VERSION ""

NS_ :

BS_:

BU_: VCM TCM ECM EBS ACM

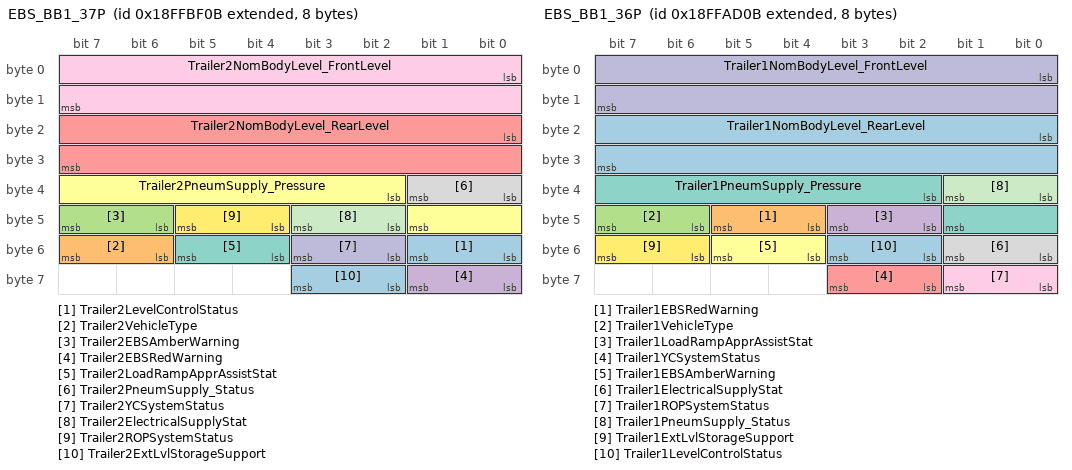
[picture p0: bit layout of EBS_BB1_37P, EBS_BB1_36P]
BO_ 2566897419 EBS_BB1_37P: 8 EBS
 SG_ Trailer2LevelControlStatus : 48|2@1+ (1,0) [0|0] ""  VCM
 SG_ Trailer2VehicleType : 54|2@1+ (1,0) [0|0] ""  VCM
 SG_ Trailer2EBSAmberWarning : 46|2@1+ (1,0) [0|0] ""  VCM
 SG_ Trailer2EBSRedWarning : 56|2@1+ (1,0) [0|0] ""  VCM
 SG_ Trailer2NomBodyLevel_RearLevel : 16|16@1+ (1,0) [0|65535] "mm"  VCM
 SG_ Trailer2PneumSupply_Pressure : 34|8@1+ (5,0) [0|1275] "kPa"  VCM
 SG_ Trailer2LoadRampApprAssistStat : 52|2@1+ (1,0) [0|0] ""  VCM
 SG_ Trailer2PneumSupply_Status : 32|2@1+ (1,0) [0|0] ""  VCM
 SG_ Trailer2NomBodyLevel_FrontLevel : 0|16@1+ (1,0) [0|65535] "mm"  VCM
 SG_ Trailer2YCSystemStatus : 50|2@1+ (1,0) [0|0] ""  VCM
 SG_ Trailer2ElectricalSupplyStat : 42|2@1+ (1,0) [0|0] ""  VCM
 SG_ Trailer2ROPSystemStatus : 44|2@1+ (1,0) [0|0] ""  VCM
 SG_ Trailer2ExtLvlStorageSupport : 58|2@1+ (1,0) [0|0] ""  VCM

BO_ 2566892811 EBS_BB1_36P: 8 EBS
 SG_ Trailer1NomBodyLevel_RearLevel : 16|16@1+ (1,0) [0|65535] "mm"  VCM
 SG_ Trailer1EBSRedWarning : 44|2@1+ (1,0) [0|0] ""  VCM
 SG_ Trailer1VehicleType : 46|2@1+ (1,0) [0|0] ""  VCM
 SG_ Trailer1LoadRampApprAssistStat : 42|2@1+ (1,0) [0|0] ""  VCM
 SG_ Trailer1YCSystemStatus : 58|2@1+ (1,0) [0|0] ""  VCM
 SG_ Trailer1EBSAmberWarning : 52|2@1+ (1,0) [0|0] ""  VCM
 SG_ Trailer1PneumSupply_Pressure : 34|8@1+ (5,0) [0|1275] "kPa"  VCM
 SG_ Trailer1ElectricalSupplyStat : 48|2@1+ (1,0) [0|0] ""  VCM
 SG_ Trailer1ROPSystemStatus : 56|2@1+ (1,0) [0|0] ""  VCM
 SG_ Trailer1NomBodyLevel_FrontLevel : 0|16@1+ (1,0) [0|65535] "mm"  VCM
 SG_ Trailer1PneumSupply_Status : 32|2@1+ (1,0) [0|0] ""  VCM
 SG_ Trailer1ExtLvlStorageSupport : 54|2@1+ (1,0) [0|0] ""  VCM
 SG_ Trailer1LevelControlStatus : 50|2@1+ (1,0) [0|0] ""  VCM

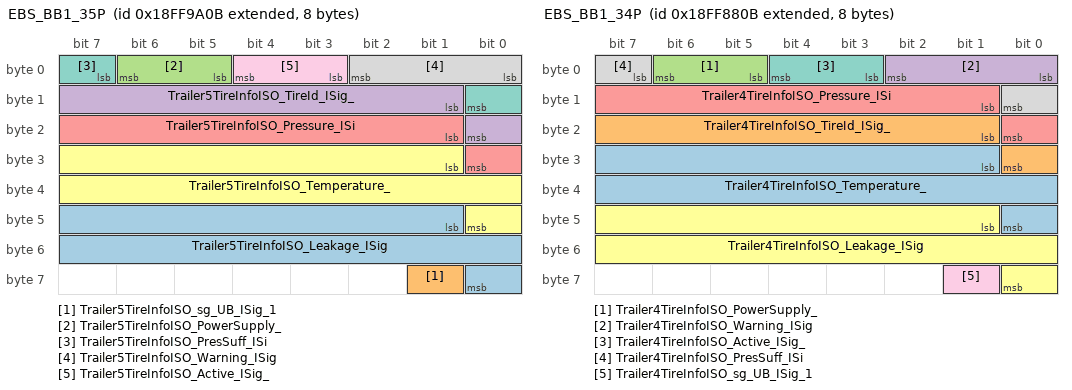
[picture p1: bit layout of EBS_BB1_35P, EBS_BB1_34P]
BO_ 2566887947 EBS_BB1_35P: 8 EBS
 SG_ Trailer5TireInfoISO_Leakage_ISig : 41|16@1+ (0.1,0) [0|6553.5] "Pa_per_s"  VCM
 SG_ Trailer5TireInfoISO_sg_UB_ISig_1 : 57|1@1+ (1,0) [0|0] ""  VCM
 SG_ Trailer5TireInfoISO_PowerSupply_ : 5|2@1+ (1,0) [0|0] ""  VCM
 SG_ Trailer5TireInfoISO_TireId_ISig_ : 9|8@1+ (1,0) [0|255] "NotApplicable"  VCM
 SG_ Trailer5TireInfoISO_Pressure_ISi : 17|8@1+ (10,0) [0|2550] "kPa"  VCM
 SG_ Trailer5TireInfoISO_Temperature_ : 25|16@1+ (0.03125,-273) [-273|1774.96875] "DegreeC"  VCM
 SG_ Trailer5TireInfoISO_PresSuff_ISi : 7|2@1+ (1,0) [0|0] ""  VCM
 SG_ Trailer5TireInfoISO_Warning_ISig : 0|3@1+ (1,0) [0|0] ""  VCM
 SG_ Trailer5TireInfoISO_Active_ISig_ : 3|2@1+ (1,0) [0|0] ""  VCM

BO_ 2566883339 EBS_BB1_34P: 8 EBS
 SG_ Trailer4TireInfoISO_Temperature_ : 25|16@1+ (0.03125,-273) [-273|1774.96875] "DegreeC"  VCM
 SG_ Trailer4TireInfoISO_TireId_ISig_ : 17|8@1+ (1,0) [0|255] "NotApplicable"  VCM
 SG_ Trailer4TireInfoISO_PowerSupply_ : 5|2@1+ (1,0) [0|0] ""  VCM
 SG_ Trailer4TireInfoISO_Warning_ISig : 0|3@1+ (1,0) [0|0] ""  VCM
 SG_ Trailer4TireInfoISO_Pressure_ISi : 9|8@1+ (10,0) [0|2550] "kPa"  VCM
 SG_ Trailer4TireInfoISO_Leakage_ISig : 41|16@1+ (0.1,0) [0|6553.5] "Pa_per_s"  VCM
 SG_ Trailer4TireInfoISO_Active_ISig_ : 3|2@1+ (1,0) [0|0] ""  VCM
 SG_ Trailer4TireInfoISO_PresSuff_ISi : 7|2@1+ (1,0) [0|0] ""  VCM
 SG_ Trailer4TireInfoISO_sg_UB_ISig_1 : 57|1@1+ (1,0) [0|0] ""  VCM

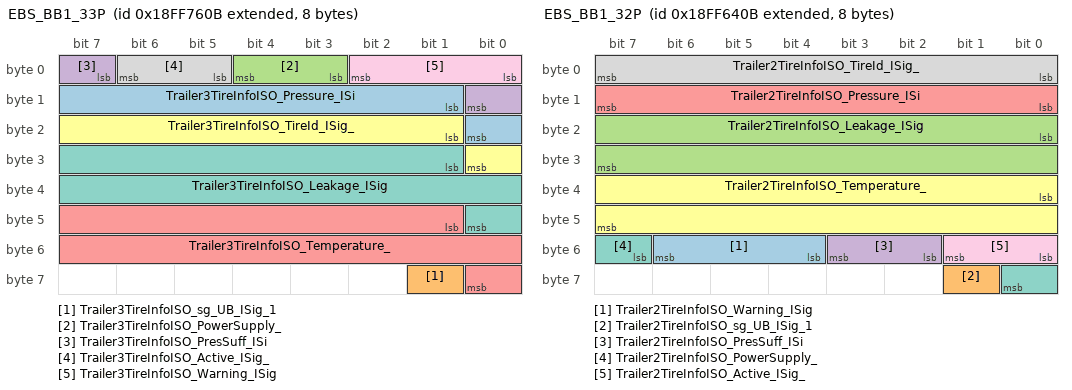
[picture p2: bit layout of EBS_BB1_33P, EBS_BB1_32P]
BO_ 2566878731 EBS_BB1_33P: 8 EBS
 SG_ Trailer3TireInfoISO_Pressure_ISi : 9|8@1+ (10,0) [0|2550] "kPa"  VCM
 SG_ Trailer3TireInfoISO_sg_UB_ISig_1 : 57|1@1+ (1,0) [0|0] ""  VCM
 SG_ Trailer3TireInfoISO_PowerSupply_ : 3|2@1+ (1,0) [0|0] ""  VCM
 SG_ Trailer3TireInfoISO_PresSuff_ISi : 7|2@1+ (1,0) [0|0] ""  VCM
 SG_ Trailer3TireInfoISO_Temperature_ : 41|16@1+ (0.03125,-273) [-273|1774.96875] "DegreeC"  VCM
 SG_ Trailer3TireInfoISO_TireId_ISig_ : 17|8@1+ (1,0) [0|255] "NotApplicable"  VCM
 SG_ Trailer3TireInfoISO_Leakage_ISig : 25|16@1+ (0.1,0) [0|6553.5] "Pa_per_s"  VCM
 SG_ Trailer3TireInfoISO_Active_ISig_ : 5|2@1+ (1,0) [0|0] ""  VCM
 SG_ Trailer3TireInfoISO_Warning_ISig : 0|3@1+ (1,0) [0|0] ""  VCM

BO_ 2566874123 EBS_BB1_32P: 8 EBS
 SG_ Trailer2TireInfoISO_Warning_ISig : 52|3@1+ (1,0) [0|0] ""  VCM
 SG_ Trailer2TireInfoISO_sg_UB_ISig_1 : 57|1@1+ (1,0) [0|0] ""  VCM
 SG_ Trailer2TireInfoISO_Leakage_ISig : 16|16@1+ (0.1,0) [0|6553.5] "Pa_per_s"  VCM
 SG_ Trailer2TireInfoISO_PresSuff_ISi : 50|2@1+ (1,0) [0|0] ""  VCM
 SG_ Trailer2TireInfoISO_Pressure_ISi : 8|8@1+ (10,0) [0|2550] "kPa"  VCM
 SG_ Trailer2TireInfoISO_Temperature_ : 32|16@1+ (0.03125,-273) [-273|1774.96875] "DegreeC"  VCM
 SG_ Trailer2TireInfoISO_PowerSupply_ : 55|2@1+ (1,0) [0|0] ""  VCM
 SG_ Trailer2TireInfoISO_TireId_ISig_ : 0|8@1+ (1,0) [0|255] "NotApplicable"  VCM
 SG_ Trailer2TireInfoISO_Active_ISig_ : 48|2@1+ (1,0) [0|0] ""  VCM

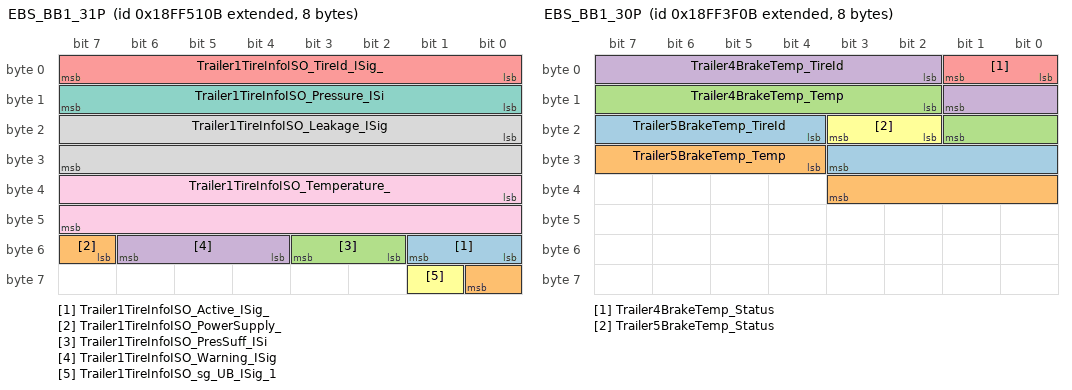
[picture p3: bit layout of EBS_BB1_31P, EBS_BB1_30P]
BO_ 2566869259 EBS_BB1_31P: 8 EBS
 SG_ Trailer1TireInfoISO_Active_ISig_ : 48|2@1+ (1,0) [0|0] ""  VCM
 SG_ Trailer1TireInfoISO_PowerSupply_ : 55|2@1+ (1,0) [0|0] ""  VCM
 SG_ Trailer1TireInfoISO_PresSuff_ISi : 50|2@1+ (1,0) [0|0] ""  VCM
 SG_ Trailer1TireInfoISO_Warning_ISig : 52|3@1+ (1,0) [0|0] ""  VCM
 SG_ Trailer1TireInfoISO_TireId_ISig_ : 0|8@1+ (1,0) [0|255] "NotApplicable"  VCM
 SG_ Trailer1TireInfoISO_sg_UB_ISig_1 : 57|1@1+ (1,0) [0|0] ""  VCM
 SG_ Trailer1TireInfoISO_Pressure_ISi : 8|8@1+ (10,0) [0|2550] "kPa"  VCM
 SG_ Trailer1TireInfoISO_Leakage_ISig : 16|16@1+ (0.1,0) [0|6553.5] "Pa_per_s"  VCM
 SG_ Trailer1TireInfoISO_Temperature_ : 32|16@1+ (0.03125,-273) [-273|1774.96875] "DegreeC"  VCM

BO_ 2566864651 EBS_BB1_30P: 8 EBS
 SG_ Trailer5BrakeTemp_TireId : 20|8@1+ (1,0) [0|255] "NotApplicable"  VCM
 SG_ Trailer5BrakeTemp_Temp : 28|8@1+ (10,0) [0|2550] "DegreeC"  VCM
 SG_ Trailer4BrakeTemp_Temp : 10|8@1+ (10,0) [0|2550] "DegreeC"  VCM
 SG_ Trailer4BrakeTemp_TireId : 2|8@1+ (1,0) [0|255] "NotApplicable"  VCM
 SG_ Trailer4BrakeTemp_Status : 0|2@1+ (1,0) [0|0] ""  VCM
 SG_ Trailer5BrakeTemp_Status : 18|2@1+ (1,0) [0|0] ""  VCM

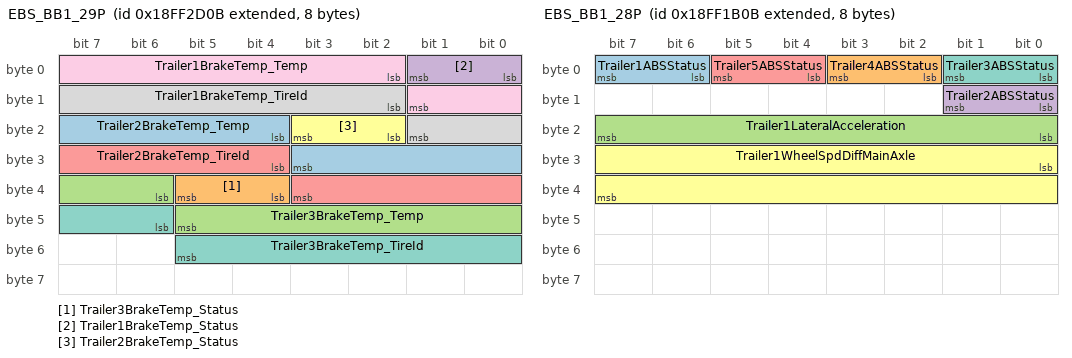
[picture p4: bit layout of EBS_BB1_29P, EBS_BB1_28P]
BO_ 2566860043 EBS_BB1_29P: 8 EBS
 SG_ Trailer2BrakeTemp_Temp : 20|8@1+ (10,0) [0|2550] "DegreeC"  VCM
 SG_ Trailer3BrakeTemp_Status : 36|2@1+ (1,0) [0|0] ""  VCM
 SG_ Trailer3BrakeTemp_Temp : 38|8@1+ (10,0) [0|2550] "DegreeC"  VCM
 SG_ Trailer1BrakeTemp_Status : 0|2@1+ (1,0) [0|0] ""  VCM
 SG_ Trailer2BrakeTemp_TireId : 28|8@1+ (1,0) [0|255] "NotApplicable"  VCM
 SG_ Trailer2BrakeTemp_Status : 18|2@1+ (1,0) [0|0] ""  VCM
 SG_ Trailer3BrakeTemp_TireId : 46|8@1+ (1,0) [0|255] "NotApplicable"  VCM
 SG_ Trailer1BrakeTemp_TireId : 10|8@1+ (1,0) [0|255] "NotApplicable"  VCM
 SG_ Trailer1BrakeTemp_Temp : 2|8@1+ (10,0) [0|2550] "DegreeC"  VCM

BO_ 2566855435 EBS_BB1_28P: 8 EBS
 SG_ Trailer1ABSStatus : 6|2@1+ (1,0) [0|0] ""  VCM
 SG_ Trailer4ABSStatus : 2|2@1+ (1,0) [0|0] ""  VCM
 SG_ Trailer1LateralAcceleration : 16|8@1+ (0.1,-12.5) [-12.5|13] "m_per_s_squared"  VCM
 SG_ Trailer2ABSStatus : 8|2@1+ (1,0) [0|0] ""  VCM
 SG_ Trailer5ABSStatus : 4|2@1+ (1,0) [0|0] ""  VCM
 SG_ Trailer1WheelSpdDiffMainAxle : 24|16@1+ (0.00390625,-125) [-125|130.99609375] "Km_per_h"  VCM
 SG_ Trailer3ABSStatus : 0|2@1+ (1,0) [0|0] ""  VCM

BO_ 2566850827 EBS_BB1_27P: 8 EBS
 SG_ Trailer4StopLevelChangeAck : 18|2@1+ (1,0) [0|0] ""  VCM
 SG_ Trailer4NormalLevelStorStat : 2|2@1+ (1,0) [0|0] ""  VCM
 SG_ Trailer2StopLevelChangeAck : 22|2@1+ (1,0) [0|0] ""  VCM
 SG_ Trailer4RampLevelStorStat : 28|2@1+ (1,0) [0|0] ""  VCM
 SG_ Trailer5NormalLevelStorStat : 6|2@1+ (1,0) [0|0] ""  VCM
 SG_ Trailer5LevelChangeFrontAxle : 26|2@1+ (1,0) [0|0] ""  VCM
 SG_ Trailer3NormalLevelStorStat : 56|2@1+ (1,0) [0|0] ""  VCM
 SG_ Trailer2NormalLevelStorStat : 46|2@1+ (1,0) [0|0] ""  VCM
 SG_ Trailer4TractionHelp : 42|2@1+ (1,0) [0|0] ""  VCM
 SG_ Trailer5StopLevelChangeAck : 24|2@1+ (1,0) [0|0] ""  VCM
 SG_ Trailer1LevelChangeRearAxle : 54|2@1+ (1,0) [0|0] ""  VCM
 SG_ Trailer4LevelChangeRearAxle : 36|2@1+ (1,0) [0|0] ""  VCM
 SG_ Trailer3LevelChangeRearAxle : 0|2@1+ (1,0) [0|0] ""  VCM
 SG_ Trailer3TractionHelp : 32|2@1+ (1,0) [0|0] ""  VCM
 SG_ Trailer2LevelChangeRearAxle : 30|2@1+ (1,0) [0|0] ""  VCM
 SG_ Trailer2RampLevelStorStat : 14|2@1+ (1,0) [0|0] ""  VCM
 SG_ Trailer3StopLevelChangeAck : 44|2@1+ (1,0) [0|0] ""  VCM
 SG_ Trailer5LevelChangeRearAxle : 48|2@1+ (1,0) [0|0] ""  VCM
 SG_ Trailer4LevelChangeFrontAxle : 40|2@1+ (1,0) [0|0] ""  VCM
 SG_ Trailer2TractionHelp : 4|2@1+ (1,0) [0|0] ""  VCM
 SG_ Trailer1RampLevelStorStat : 52|2@1+ (1,0) [0|0] ""  VCM
 SG_ Trailer5RampLevelStorStat : 8|2@1+ (1,0) [0|0] ""  VCM
 SG_ Trailer3LevelChangeFrontAxle : 38|2@1+ (1,0) [0|0] ""  VCM
 SG_ Trailer1StopLevelChangeAck : 50|2@1+ (1,0) [0|0] ""  VCM
 SG_ Trailer2LevelChangeFrontAxle : 34|2@1+ (1,0) [0|0] ""  VCM
 SG_ Trailer5TractionHelp : 58|2@1+ (1,0) [0|0] ""  VCM
 SG_ Trailer1LevelChangeFrontAxle : 16|2@1+ (1,0) [0|0] ""  VCM
 SG_ Trailer3RampLevelStorStat : 12|2@1+ (1,0) [0|0] ""  VCM
 SG_ Trailer1NormalLevelStorStat : 10|2@1+ (1,0) [0|0] ""  VCM

BO_ 2566899211 EBS_BB1_26P: 8 EBS
 SG_ Trailer5TowedVehStat_BrakeSystem : 36|2@1+ (1,0) [0|0] ""  VCM
 SG_ Trailer4TowedVehStat_DetectSupp : 30|2@1+ (1,0) [0|0] ""  VCM
 SG_ Trailer4TowedVehStat_CANAvail : 26|2@1+ (1,0) [0|0] ""  VCM
 SG_ Trailer3TowedVehStat_DetectStat : 16|2@1+ (1,0) [0|0] ""  VCM
 SG_ Trailer1TowedVehStat_DetectSupp : 6|2@1+ (1,0) [0|0] ""  VCM
 SG_ Trailer2TowedVehStat_CANAvail : 10|2@1+ (1,0) [0|0] ""  VCM
 SG_ Trailer1TowedVehStat_CANAvail : 2|2@1+ (1,0) [0|0] ""  VCM
 SG_ Trailer3TowedVehStat_DetectSupp : 22|2@1+ (1,0) [0|0] ""  VCM
 SG_ Trailer3TowedVehStat_CANAvail : 18|2@1+ (1,0) [0|0] ""  VCM
 SG_ Trailer1TowedVehStat_DetectStat : 0|2@1+ (1,0) [0|0] ""  VCM
 SG_ Trailer5TowedVehStat_DetectSupp : 38|2@1+ (1,0) [0|0] ""  VCM
 SG_ Trailer4TowedVehStat_DetectStat : 24|2@1+ (1,0) [0|0] ""  VCM
 SG_ Trailer4TowedVehStat_BrakeSystem : 28|2@1+ (1,0) [0|0] ""  VCM
 SG_ Trailer5TowedVehStat_DetectStat : 32|2@1+ (1,0) [0|0] ""  VCM
 SG_ Trailer3TowedVehStat_BrakeSystem : 20|2@1+ (1,0) [0|0] ""  VCM
 SG_ Trailer1TowedVehStat_BrakeSystem : 4|2@1+ (1,0) [0|0] ""  VCM
 SG_ Trailer5TowedVehStat_CANAvail : 34|2@1+ (1,0) [0|0] ""  VCM
 SG_ Trailer2TowedVehStat_DetectStat : 8|2@1+ (1,0) [0|0] ""  VCM
 SG_ Trailer2TowedVehStat_BrakeSystem : 12|2@1+ (1,0) [0|0] ""  VCM
 SG_ Trailer2TowedVehStat_DetectSupp : 14|2@1+ (1,0) [0|0] ""  VCM

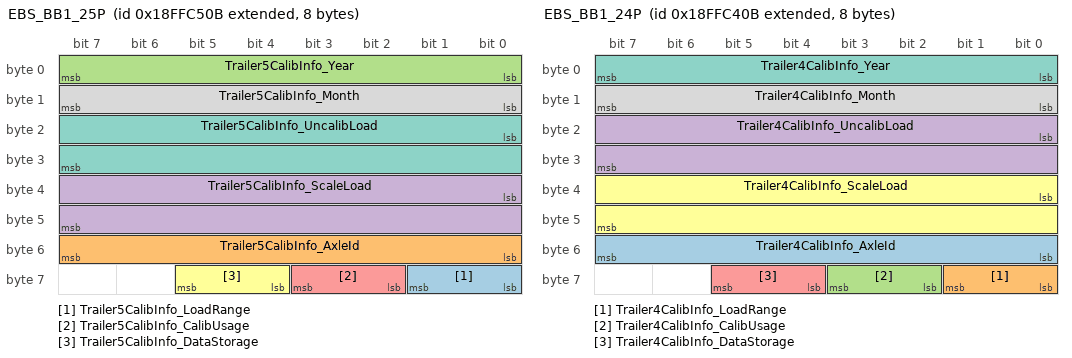
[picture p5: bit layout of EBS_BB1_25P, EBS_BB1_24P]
BO_ 2566898955 EBS_BB1_25P: 8 EBS
 SG_ Trailer5CalibInfo_LoadRange : 56|2@1+ (1,0) [0|0] ""  VCM
 SG_ Trailer5CalibInfo_AxleId : 48|8@1+ (1,0) [0|255] "NotApplicable"  VCM
 SG_ Trailer5CalibInfo_Year : 0|8@1+ (1,1985) [1985|2240] "Years"  VCM
 SG_ Trailer5CalibInfo_ScaleLoad : 32|16@1+ (1,0) [0|65535] "kg"  VCM
 SG_ Trailer5CalibInfo_CalibUsage : 58|2@1+ (1,0) [0|0] ""  VCM
 SG_ Trailer5CalibInfo_DataStorage : 60|2@1+ (1,0) [0|0] ""  VCM
 SG_ Trailer5CalibInfo_UncalibLoad : 16|16@1+ (1,0) [0|65535] "kg"  VCM
 SG_ Trailer5CalibInfo_Month : 8|8@1+ (1,0) [0|255] "Months"  VCM

BO_ 2566898699 EBS_BB1_24P: 8 EBS
 SG_ Trailer4CalibInfo_AxleId : 48|8@1+ (1,0) [0|255] "NotApplicable"  VCM
 SG_ Trailer4CalibInfo_LoadRange : 56|2@1+ (1,0) [0|0] ""  VCM
 SG_ Trailer4CalibInfo_CalibUsage : 58|2@1+ (1,0) [0|0] ""  VCM
 SG_ Trailer4CalibInfo_UncalibLoad : 16|16@1+ (1,0) [0|65535] "kg"  VCM
 SG_ Trailer4CalibInfo_DataStorage : 60|2@1+ (1,0) [0|0] ""  VCM
 SG_ Trailer4CalibInfo_ScaleLoad : 32|16@1+ (1,0) [0|65535] "kg"  VCM
 SG_ Trailer4CalibInfo_Year : 0|8@1+ (1,1985) [1985|2240] "Years"  VCM
 SG_ Trailer4CalibInfo_Month : 8|8@1+ (1,0) [0|255] "Months"  VCM

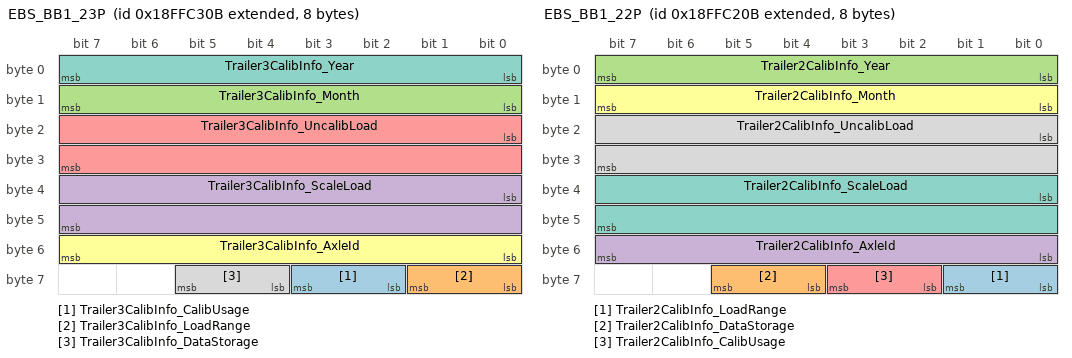
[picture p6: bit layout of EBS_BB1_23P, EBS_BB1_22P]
BO_ 2566898443 EBS_BB1_23P: 8 EBS
 SG_ Trailer3CalibInfo_CalibUsage : 58|2@1+ (1,0) [0|0] ""  VCM
 SG_ Trailer3CalibInfo_LoadRange : 56|2@1+ (1,0) [0|0] ""  VCM
 SG_ Trailer3CalibInfo_Month : 8|8@1+ (1,0) [0|255] "Months"  VCM
 SG_ Trailer3CalibInfo_ScaleLoad : 32|16@1+ (1,0) [0|65535] "kg"  VCM
 SG_ Trailer3CalibInfo_UncalibLoad : 16|16@1+ (1,0) [0|65535] "kg"  VCM
 SG_ Trailer3CalibInfo_AxleId : 48|8@1+ (1,0) [0|255] "NotApplicable"  VCM
 SG_ Trailer3CalibInfo_Year : 0|8@1+ (1,1985) [1985|2240] "Years"  VCM
 SG_ Trailer3CalibInfo_DataStorage : 60|2@1+ (1,0) [0|0] ""  VCM

BO_ 2566898187 EBS_BB1_22P: 8 EBS
 SG_ Trailer2CalibInfo_LoadRange : 56|2@1+ (1,0) [0|0] ""  VCM
 SG_ Trailer2CalibInfo_DataStorage : 60|2@1+ (1,0) [0|0] ""  VCM
 SG_ Trailer2CalibInfo_Year : 0|8@1+ (1,1985) [1985|2240] "Years"  VCM
 SG_ Trailer2CalibInfo_AxleId : 48|8@1+ (1,0) [0|255] "NotApplicable"  VCM
 SG_ Trailer2CalibInfo_CalibUsage : 58|2@1+ (1,0) [0|0] ""  VCM
 SG_ Trailer2CalibInfo_Month : 8|8@1+ (1,0) [0|255] "Months"  VCM
 SG_ Trailer2CalibInfo_ScaleLoad : 32|16@1+ (1,0) [0|65535] "kg"  VCM
 SG_ Trailer2CalibInfo_UncalibLoad : 16|16@1+ (1,0) [0|65535] "kg"  VCM

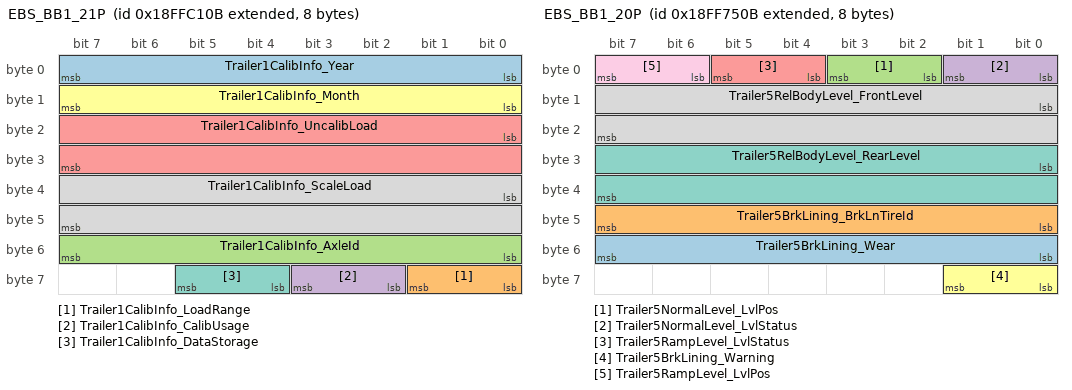
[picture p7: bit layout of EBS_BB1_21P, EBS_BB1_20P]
BO_ 2566897931 EBS_BB1_21P: 8 EBS
 SG_ Trailer1CalibInfo_Year : 0|8@1+ (1,1985) [1985|2240] "Years"  VCM
 SG_ Trailer1CalibInfo_LoadRange : 56|2@1+ (1,0) [0|0] ""  VCM
 SG_ Trailer1CalibInfo_AxleId : 48|8@1+ (1,0) [0|255] "NotApplicable"  VCM
 SG_ Trailer1CalibInfo_CalibUsage : 58|2@1+ (1,0) [0|0] ""  VCM
 SG_ Trailer1CalibInfo_UncalibLoad : 16|16@1+ (1,0) [0|65535] "kg"  VCM
 SG_ Trailer1CalibInfo_Month : 8|8@1+ (1,0) [0|255] "Months"  VCM
 SG_ Trailer1CalibInfo_DataStorage : 60|2@1+ (1,0) [0|0] ""  VCM
 SG_ Trailer1CalibInfo_ScaleLoad : 32|16@1+ (1,0) [0|65535] "kg"  VCM

BO_ 2566878475 EBS_BB1_20P: 8 EBS
 SG_ Trailer5BrkLining_Wear : 48|8@1+ (0.4,0) [0|102] "Percent"  VCM
 SG_ Trailer5BrkLining_BrkLnTireId : 40|8@1+ (1,0) [0|255] "NotApplicable"  VCM
 SG_ Trailer5NormalLevel_LvlPos : 2|2@1+ (1,0) [0|0] ""  VCM
 SG_ Trailer5NormalLevel_LvlStatus : 0|2@1+ (1,0) [0|0] ""  VCM
 SG_ Trailer5RampLevel_LvlStatus : 4|2@1+ (1,0) [0|0] ""  VCM
 SG_ Trailer5BrkLining_Warning : 56|2@1+ (1,0) [0|0] ""  VCM
 SG_ Trailer5RelBodyLevel_RearLevel : 24|16@1+ (1,-32000) [-32000|33535] "mm"  VCM
 SG_ Trailer5RelBodyLevel_FrontLevel : 8|16@1+ (1,-32000) [-32000|33535] "mm"  VCM
 SG_ Trailer5RampLevel_LvlPos : 6|2@1+ (1,0) [0|0] ""  VCM

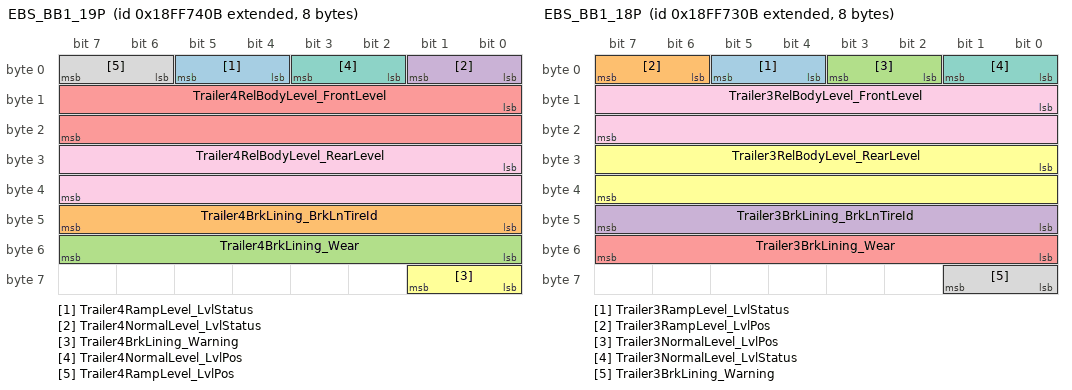
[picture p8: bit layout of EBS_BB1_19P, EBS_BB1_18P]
BO_ 2566878219 EBS_BB1_19P: 8 EBS
 SG_ Trailer4RampLevel_LvlStatus : 4|2@1+ (1,0) [0|0] ""  VCM
 SG_ Trailer4BrkLining_BrkLnTireId : 40|8@1+ (1,0) [0|255] "NotApplicable"  VCM
 SG_ Trailer4BrkLining_Wear : 48|8@1+ (0.4,0) [0|102] "Percent"  VCM
 SG_ Trailer4NormalLevel_LvlStatus : 0|2@1+ (1,0) [0|0] ""  VCM
 SG_ Trailer4RelBodyLevel_FrontLevel : 8|16@1+ (1,-32000) [-32000|33535] "mm"  VCM
 SG_ Trailer4BrkLining_Warning : 56|2@1+ (1,0) [0|0] ""  VCM
 SG_ Trailer4NormalLevel_LvlPos : 2|2@1+ (1,0) [0|0] ""  VCM
 SG_ Trailer4RampLevel_LvlPos : 6|2@1+ (1,0) [0|0] ""  VCM
 SG_ Trailer4RelBodyLevel_RearLevel : 24|16@1+ (1,-32000) [-32000|33535] "mm"  VCM

BO_ 2566877963 EBS_BB1_18P: 8 EBS
 SG_ Trailer3RampLevel_LvlStatus : 4|2@1+ (1,0) [0|0] ""  VCM
 SG_ Trailer3RampLevel_LvlPos : 6|2@1+ (1,0) [0|0] ""  VCM
 SG_ Trailer3NormalLevel_LvlPos : 2|2@1+ (1,0) [0|0] ""  VCM
 SG_ Trailer3BrkLining_BrkLnTireId : 40|8@1+ (1,0) [0|255] "NotApplicable"  VCM
 SG_ Trailer3BrkLining_Wear : 48|8@1+ (0.4,0) [0|102] "Percent"  VCM
 SG_ Trailer3RelBodyLevel_RearLevel : 24|16@1+ (1,-32000) [-32000|33535] "mm"  VCM
 SG_ Trailer3NormalLevel_LvlStatus : 0|2@1+ (1,0) [0|0] ""  VCM
 SG_ Trailer3BrkLining_Warning : 56|2@1+ (1,0) [0|0] ""  VCM
 SG_ Trailer3RelBodyLevel_FrontLevel : 8|16@1+ (1,-32000) [-32000|33535] "mm"  VCM

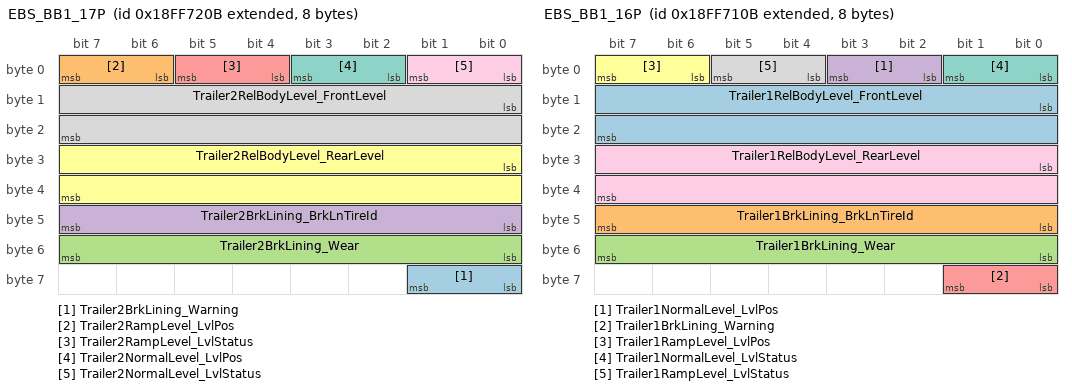
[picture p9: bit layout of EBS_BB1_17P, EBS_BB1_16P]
BO_ 2566877707 EBS_BB1_17P: 8 EBS
 SG_ Trailer2BrkLining_Warning : 56|2@1+ (1,0) [0|0] ""  VCM
 SG_ Trailer2RampLevel_LvlPos : 6|2@1+ (1,0) [0|0] ""  VCM
 SG_ Trailer2BrkLining_Wear : 48|8@1+ (0.4,0) [0|102] "Percent"  VCM
 SG_ Trailer2BrkLining_BrkLnTireId : 40|8@1+ (1,0) [0|255] "NotApplicable"  VCM
 SG_ Trailer2RampLevel_LvlStatus : 4|2@1+ (1,0) [0|0] ""  VCM
 SG_ Trailer2RelBodyLevel_RearLevel : 24|16@1+ (1,-32000) [-32000|33535] "mm"  VCM
 SG_ Trailer2NormalLevel_LvlPos : 2|2@1+ (1,0) [0|0] ""  VCM
 SG_ Trailer2RelBodyLevel_FrontLevel : 8|16@1+ (1,-32000) [-32000|33535] "mm"  VCM
 SG_ Trailer2NormalLevel_LvlStatus : 0|2@1+ (1,0) [0|0] ""  VCM

BO_ 2566877451 EBS_BB1_16P: 8 EBS
 SG_ Trailer1RelBodyLevel_FrontLevel : 8|16@1+ (1,-32000) [-32000|33535] "mm"  VCM
 SG_ Trailer1BrkLining_BrkLnTireId : 40|8@1+ (1,0) [0|255] "NotApplicable"  VCM
 SG_ Trailer1BrkLining_Wear : 48|8@1+ (0.4,0) [0|102] "Percent"  VCM
 SG_ Trailer1NormalLevel_LvlPos : 2|2@1+ (1,0) [0|0] ""  VCM
 SG_ Trailer1BrkLining_Warning : 56|2@1+ (1,0) [0|0] ""  VCM
 SG_ Trailer1RampLevel_LvlPos : 6|2@1+ (1,0) [0|0] ""  VCM
 SG_ Trailer1NormalLevel_LvlStatus : 0|2@1+ (1,0) [0|0] ""  VCM
 SG_ Trailer1RampLevel_LvlStatus : 4|2@1+ (1,0) [0|0] ""  VCM
 SG_ Trailer1RelBodyLevel_RearLevel : 24|16@1+ (1,-32000) [-32000|33535] "mm"  VCM

BO_ 2566894859 EBS_BB1_15P: 17 EBS
 SG_ Trailer5VIN : 0|136@1+ (1,0) [0|0] ""  VCM

BO_ 2566894603 EBS_BB1_14P: 17 EBS
 SG_ Trailer4VIN : 0|136@1+ (1,0) [0|0] ""  VCM

BO_ 2566894347 EBS_BB1_13P: 17 EBS
 SG_ Trailer3VIN : 0|136@1+ (1,0) [0|0] ""  VCM

BO_ 2566894091 EBS_BB1_12P: 17 EBS
 SG_ Trailer2VIN : 0|136@1+ (1,0) [0|0] ""  VCM

BO_ 2566893835 EBS_BB1_11P: 17 EBS
 SG_ Trailer1VIN : 0|136@1+ (1,0) [0|0] ""  VCM

CM_ SG_ 2566897419 Trailer2PneumSupply_Pressure "254 Error ; 255 Not available";
CM_ SG_ 2566892811 Trailer1PneumSupply_Pressure "254 Error ; 255 Not available";
CM_ SG_ 2566887947 Trailer5TireInfoISO_Leakage_ISig "64256-65023 Spare; 65024-65279 Error; 65280-65535 NotAvailable;";
CM_ SG_ 2566887947 Trailer5TireInfoISO_Pressure_ISi "251-253 Spare; 254 Error; 255 NotAvailable;";
CM_ SG_ 2566887947 Trailer5TireInfoISO_Temperature_ "64256-65023 Spare; 65024-65279 Error; 65280-65535 NotAvailable;";
CM_ SG_ 2566883339 Trailer4TireInfoISO_Temperature_ "64256-65023 Spare; 65024-65279 Error; 65280-65535 NotAvailable;";
CM_ SG_ 2566883339 Trailer4TireInfoISO_Pressure_ISi "251-253 Spare; 254 Error; 255 NotAvailable;";
CM_ SG_ 2566883339 Trailer4TireInfoISO_Leakage_ISig "64256-65023 Spare; 65024-65279 Error; 65280-65535 NotAvailable;";
CM_ SG_ 2566878731 Trailer3TireInfoISO_Pressure_ISi "251-253 Spare; 254 Error; 255 NotAvailable;";
CM_ SG_ 2566878731 Trailer3TireInfoISO_Temperature_ "64256-65023 Spare; 65024-65279 Error; 65280-65535 NotAvailable;";
CM_ SG_ 2566878731 Trailer3TireInfoISO_Leakage_ISig "64256-65023 Spare; 65024-65279 Error; 65280-65535 NotAvailable;";
CM_ SG_ 2566874123 Trailer2TireInfoISO_Leakage_ISig "64256-65023 Spare; 65024-65279 Error; 65280-65535 NotAvailable;";
CM_ SG_ 2566874123 Trailer2TireInfoISO_Pressure_ISi "251-253 Spare; 254 Error; 255 NotAvailable;";
CM_ SG_ 2566874123 Trailer2TireInfoISO_Temperature_ "64256-65023 Spare; 65024-65279 Error; 65280-65535 NotAvailable;";
CM_ SG_ 2566869259 Trailer1TireInfoISO_Pressure_ISi "251-253 Spare; 254 Error; 255 NotAvailable;";
CM_ SG_ 2566869259 Trailer1TireInfoISO_Leakage_ISig "64256-65023 Spare; 65024-65279 Error; 65280-65535 NotAvailable;";
CM_ SG_ 2566869259 Trailer1TireInfoISO_Temperature_ "64256-65023 Spare; 65024-65279 Error; 65280-65535 NotAvailable;";
CM_ SG_ 2566864651 Trailer5BrakeTemp_Temp "254 Error; 255 Not Available";
CM_ SG_ 2566864651 Trailer4BrakeTemp_Temp "254 Error; 255 Not Available";
CM_ SG_ 2566860043 Trailer2BrakeTemp_Temp "254 Error; 255 Not Available";
CM_ SG_ 2566860043 Trailer3BrakeTemp_Temp "254 Error; 255 Not Available";
CM_ SG_ 2566860043 Trailer1BrakeTemp_Temp "254 Error; 255 Not Available";
CM_ SG_ 2566898955 Trailer5CalibInfo_Year "254 Error ; 255 Not available";
CM_ SG_ 2566898955 Trailer5CalibInfo_ScaleLoad "10000-65023: Spare, 65024-65279: Error, 65280-65535: NotAvailable";
CM_ SG_ 2566898955 Trailer5CalibInfo_UncalibLoad "10000-65023: Spare, 65024-65279: Error, 65280-65535: NotAvailable";
CM_ SG_ 2566898955 Trailer5CalibInfo_Month "254 Error ; 255 Not available";
CM_ SG_ 2566898699 Trailer4CalibInfo_UncalibLoad "10000-65023: Spare, 65024-65279: Error, 65280-65535: NotAvailable";
CM_ SG_ 2566898699 Trailer4CalibInfo_ScaleLoad "10000-65023: Spare, 65024-65279: Error, 65280-65535: NotAvailable";
CM_ SG_ 2566898699 Trailer4CalibInfo_Year "254 Error ; 255 Not available";
CM_ SG_ 2566898699 Trailer4CalibInfo_Month "254 Error ; 255 Not available";
CM_ SG_ 2566898443 Trailer3CalibInfo_Month "254 Error ; 255 Not available";
CM_ SG_ 2566898443 Trailer3CalibInfo_ScaleLoad "10000-65023: Spare, 65024-65279: Error, 65280-65535: NotAvailable";
CM_ SG_ 2566898443 Trailer3CalibInfo_UncalibLoad "10000-65023: Spare, 65024-65279: Error, 65280-65535: NotAvailable";
CM_ SG_ 2566898443 Trailer3CalibInfo_Year "254 Error ; 255 Not available";
CM_ SG_ 2566898187 Trailer2CalibInfo_Year "254 Error ; 255 Not available";
CM_ SG_ 2566898187 Trailer2CalibInfo_Month "254 Error ; 255 Not available";
CM_ SG_ 2566898187 Trailer2CalibInfo_ScaleLoad "10000-65023: Spare, 65024-65279: Error, 65280-65535: NotAvailable";
CM_ SG_ 2566898187 Trailer2CalibInfo_UncalibLoad "10000-65023: Spare, 65024-65279: Error, 65280-65535: NotAvailable";
CM_ SG_ 2566897931 Trailer1CalibInfo_Year "254 Error ; 255 Not available";
CM_ SG_ 2566897931 Trailer1CalibInfo_UncalibLoad "10000-65023: Spare, 65024-65279: Error, 65280-65535: NotAvailable";
CM_ SG_ 2566897931 Trailer1CalibInfo_Month "254 Error ; 255 Not available";
CM_ SG_ 2566897931 Trailer1CalibInfo_ScaleLoad "10000-65023: Spare, 65024-65279: Error, 65280-65535: NotAvailable";
BA_DEF_ BO_  "GenMsgStartDelayTime" INT 0 0;
BA_DEF_ BO_  "GenMsgDelayTime" INT 0 0;
BA_DEF_ BO_  "GenMsgNrOfRepetition" INT 0 0;
BA_DEF_ BO_  "GenMsgCycleTimeFast" INT 0 0;
BA_DEF_ BO_  "GenMsgCycleTime" INT 0 0;
BA_DEF_ BO_  "GenMsgSendType" ENUM  "Cyclic","NotUsed","NotUsed","NotUsed","NotUsed","NotUsed","NotUsed","IfActive","NoMsgSendType","NotUsed";
BA_DEF_ SG_  "GenSigStartValue" INT 0 0;
BA_DEF_ SG_  "GenSigCycleTimeActive" INT 0 0;
BA_DEF_ SG_  "GenSigCycleTime" INT 0 0;
BA_DEF_ SG_  "GenSigSendType" ENUM  "Cyclic","OnWrite","OnWriteWithRepetition","OnChange","OnChangeWithRepetition","IfActive","IfActiveWithRepetition","NoSigSendType","NotUsed","NotUsed","NotUsed","NotUsed","NotUsed";
BA_DEF_ BO_  "VFrameFormat" ENUM  "StandardCAN","ExtendedCAN","reserved","J1939PG","reserved","reserved","reserved","reserved","reserved","reserved","reserved","reserved","reserved","reserved","StandardCAN_FD","ExtendedCAN_FD";
BA_DEF_ BO_  "TpJ1939VarDlc" ENUM  "No","Yes";
BA_DEF_ SG_  "SigType" ENUM  "Default","Range","RangeSigned","ASCII","Discrete","Control","ReferencePGN","DTC","StringDelimiter","StringLength","StringLengthControl";
BA_DEF_ SG_  "SeToolVersion_SIGNAL" STRING ;
BA_DEF_ SG_  "SeToolUniqueID_SIGNAL" STRING ;
BA_DEF_ SG_  "SeToolOwnerSigGroup_SIGNAL" STRING ;
BA_DEF_ SG_  "SeToolOwnerSigGroupID_SIGNAL" STRING ;
BA_DEF_ SG_  "SeToolName_SIGNAL" STRING ;
BA_DEF_ SG_  "SeToolItemID_SIGNAL" STRING ;
BA_DEF_ SG_  "SeToolAncestorID_SIGNAL" STRING ;
BA_DEF_ SG_  "Platform_VMCU1_Sig" ENUM  "No","Yes";
BA_DEF_ SG_  "NeedsUpdateBit" ENUM  "No","Yes";
BA_DEF_ SG_  "GenSigMaxLatency" INT 0 65535;
BA_DEF_ SG_  "GenSigILSupport" ENUM  "Yes","No";
BA_DEF_ BO_  "GenMsgILSupport" ENUM  "No","Yes";
BA_DEF_ SG_  "E2EProfile" STRING ;
BA_DEF_ SG_  "E2EDataLength" INT 0 65535;
BA_DEF_ SG_  "E2EDataId" INT 0 65535;
BA_DEF_ BO_  "DiagUUDTResponse" ENUM  "No","Yes";
BA_DEF_ BO_  "DiagState" ENUM  "No","Yes";
BA_DEF_ BO_  "DiagResponse" ENUM  "No","Yes";
BA_DEF_ BO_  "DiagRequest" ENUM  "No","Yes";
BA_DEF_ BO_  "DiagConnection" HEX 0 65535;
BA_DEF_ BO_  "CanTpFcFrameId" HEX 0 2147483647;
BA_DEF_ BO_  "CanTpBs" INT 0 255;
BA_DEF_ SG_  "SystemSignalLongSymbol" STRING ;
BA_DEF_REL_ BU_SG_REL_  "GenSigTimeoutTime" INT 0 65535;
BA_DEF_REL_ BU_SG_REL_  "GenSigFirstTimeoutTime" INT 0 65535;
BA_DEF_DEF_  "GenMsgStartDelayTime" 0;
BA_DEF_DEF_  "GenMsgDelayTime" 0;
BA_DEF_DEF_  "GenMsgNrOfRepetition" 0;
BA_DEF_DEF_  "GenMsgCycleTimeFast" 0;
BA_DEF_DEF_  "GenMsgCycleTime" 0;
BA_DEF_DEF_  "GenMsgSendType" "Cyclic";
BA_DEF_DEF_  "GenSigStartValue" 0;
BA_DEF_DEF_  "GenSigCycleTimeActive" 0;
BA_DEF_DEF_  "GenSigCycleTime" 0;
BA_DEF_DEF_  "GenSigSendType" "Cyclic";
BA_DEF_DEF_  "VFrameFormat" "ExtendedCAN";
BA_DEF_DEF_  "TpJ1939VarDlc" "No";
BA_DEF_DEF_  "SigType" "Default";
BA_DEF_DEF_  "SeToolVersion_SIGNAL" "";
BA_DEF_DEF_  "SeToolUniqueID_SIGNAL" "";
BA_DEF_DEF_  "SeToolOwnerSigGroup_SIGNAL" "";
BA_DEF_DEF_  "SeToolOwnerSigGroupID_SIGNAL" "";
BA_DEF_DEF_  "SeToolName_SIGNAL" "";
BA_DEF_DEF_  "SeToolItemID_SIGNAL" "";
BA_DEF_DEF_  "SeToolAncestorID_SIGNAL" "";
BA_DEF_DEF_  "Platform_VMCU1_Sig" "No";
BA_DEF_DEF_  "NeedsUpdateBit" "No";
BA_DEF_DEF_  "GenSigMaxLatency" 0;
BA_DEF_DEF_  "GenSigILSupport" "Yes";
BA_DEF_DEF_  "GenMsgILSupport" "Yes";
BA_DEF_DEF_  "E2EProfile" "none";
BA_DEF_DEF_  "E2EDataLength" 0;
BA_DEF_DEF_  "E2EDataId" 0;
BA_DEF_DEF_  "DiagUUDTResponse" "No";
BA_DEF_DEF_  "DiagState" "No";
BA_DEF_DEF_  "DiagResponse" "No";
BA_DEF_DEF_  "DiagRequest" "No";
BA_DEF_DEF_  "DiagConnection" 0;
BA_DEF_DEF_  "CanTpFcFrameId" 2147483647;
BA_DEF_DEF_  "CanTpBs" 255;
BA_DEF_DEF_REL_ "GenSigTimeoutTime" 0;
BA_DEF_DEF_REL_ "GenSigFirstTimeoutTime" 0;
BA_DEF_DEF_  "SystemSignalLongSymbol" "";
BA_ "GenMsgCycleTime" BO_ 2566897419 1000;
BA_ "GenMsgStartDelayTime" BO_ 2566897419 340;
BA_ "VFrameFormat" BO_ 2566897419 3;
BA_ "GenMsgCycleTime" BO_ 2566892811 1000;
BA_ "GenMsgStartDelayTime" BO_ 2566892811 270;
BA_ "VFrameFormat" BO_ 2566892811 3;
BA_ "GenMsgCycleTime" BO_ 2566887947 1000;
BA_ "GenMsgStartDelayTime" BO_ 2566887947 220;
BA_ "VFrameFormat" BO_ 2566887947 3;
BA_ "GenMsgCycleTime" BO_ 2566883339 1000;
BA_ "GenMsgStartDelayTime" BO_ 2566883339 180;
BA_ "VFrameFormat" BO_ 2566883339 3;
BA_ "GenMsgCycleTime" BO_ 2566878731 1000;
BA_ "GenMsgStartDelayTime" BO_ 2566878731 120;
BA_ "VFrameFormat" BO_ 2566878731 3;
BA_ "GenMsgCycleTime" BO_ 2566874123 1000;
BA_ "GenMsgStartDelayTime" BO_ 2566874123 70;
BA_ "VFrameFormat" BO_ 2566874123 3;
BA_ "GenMsgCycleTime" BO_ 2566869259 1000;
BA_ "GenMsgStartDelayTime" BO_ 2566869259 30;
BA_ "VFrameFormat" BO_ 2566869259 3;
BA_ "GenMsgCycleTime" BO_ 2566864651 100;
BA_ "GenMsgStartDelayTime" BO_ 2566864651 60;
BA_ "VFrameFormat" BO_ 2566864651 3;
BA_ "GenMsgCycleTime" BO_ 2566860043 100;
BA_ "GenMsgStartDelayTime" BO_ 2566860043 40;
BA_ "VFrameFormat" BO_ 2566860043 3;
BA_ "GenMsgCycleTime" BO_ 2566855435 100;
BA_ "GenMsgStartDelayTime" BO_ 2566855435 20;
BA_ "VFrameFormat" BO_ 2566855435 3;
BA_ "GenMsgCycleTime" BO_ 2566850827 100;
BA_ "GenMsgStartDelayTime" BO_ 2566850827 10;
BA_ "VFrameFormat" BO_ 2566850827 3;
BA_ "GenMsgCycleTime" BO_ 2566899211 1000;
BA_ "GenMsgStartDelayTime" BO_ 2566899211 530;
BA_ "VFrameFormat" BO_ 2566899211 3;
BA_ "GenMsgCycleTime" BO_ 2566898955 1000;
BA_ "GenMsgStartDelayTime" BO_ 2566898955 485;
BA_ "VFrameFormat" BO_ 2566898955 3;
BA_ "GenMsgCycleTime" BO_ 2566898699 1000;
BA_ "GenMsgStartDelayTime" BO_ 2566898699 375;
BA_ "VFrameFormat" BO_ 2566898699 3;
BA_ "GenMsgCycleTime" BO_ 2566898443 1000;
BA_ "GenMsgStartDelayTime" BO_ 2566898443 275;
BA_ "VFrameFormat" BO_ 2566898443 3;
BA_ "GenMsgCycleTime" BO_ 2566898187 1000;
BA_ "GenMsgStartDelayTime" BO_ 2566898187 160;
BA_ "VFrameFormat" BO_ 2566898187 3;
BA_ "GenMsgCycleTime" BO_ 2566897931 1000;
BA_ "GenMsgStartDelayTime" BO_ 2566897931 55;
BA_ "VFrameFormat" BO_ 2566897931 3;
BA_ "GenMsgCycleTime" BO_ 2566878475 100;
BA_ "GenMsgStartDelayTime" BO_ 2566878475 65;
BA_ "VFrameFormat" BO_ 2566878475 3;
BA_ "GenMsgCycleTime" BO_ 2566878219 100;
BA_ "GenMsgStartDelayTime" BO_ 2566878219 25;
BA_ "VFrameFormat" BO_ 2566878219 3;
BA_ "GenMsgCycleTime" BO_ 2566877963 100;
BA_ "GenMsgStartDelayTime" BO_ 2566877963 75;
BA_ "VFrameFormat" BO_ 2566877963 3;
BA_ "GenMsgCycleTime" BO_ 2566877707 100;
BA_ "GenMsgStartDelayTime" BO_ 2566877707 15;
BA_ "VFrameFormat" BO_ 2566877707 3;
BA_ "GenMsgCycleTime" BO_ 2566877451 100;
BA_ "GenMsgStartDelayTime" BO_ 2566877451 80;
BA_ "VFrameFormat" BO_ 2566877451 3;
BA_ "GenMsgCycleTime" BO_ 2566894859 10000;
BA_ "GenMsgStartDelayTime" BO_ 2566894859 2040;
BA_ "VFrameFormat" BO_ 2566894859 3;
BA_ "GenMsgCycleTime" BO_ 2566894603 10000;
BA_ "GenMsgStartDelayTime" BO_ 2566894603 1530;
BA_ "VFrameFormat" BO_ 2566894603 3;
BA_ "GenMsgCycleTime" BO_ 2566894347 10000;
BA_ "GenMsgStartDelayTime" BO_ 2566894347 1020;
BA_ "VFrameFormat" BO_ 2566894347 3;
BA_ "GenMsgCycleTime" BO_ 2566894091 10000;
BA_ "GenMsgStartDelayTime" BO_ 2566894091 510;
BA_ "VFrameFormat" BO_ 2566894091 3;
BA_ "GenMsgCycleTime" BO_ 2566893835 10000;
BA_ "GenMsgStartDelayTime" BO_ 2566893835 100;
BA_ "VFrameFormat" BO_ 2566893835 3;
BA_ "GenSigCycleTime" SG_ 2566897419 Trailer2LevelControlStatus 100;
BA_ "GenSigCycleTimeActive" SG_ 2566897419 Trailer2LevelControlStatus 100;
BA_ "GenSigStartValue" SG_ 2566897419 Trailer2LevelControlStatus 3;
BA_ "GenSigCycleTime" SG_ 2566897419 Trailer2VehicleType 100;
BA_ "GenSigCycleTimeActive" SG_ 2566897419 Trailer2VehicleType 100;
BA_ "GenSigStartValue" SG_ 2566897419 Trailer2VehicleType 3;
BA_ "GenSigCycleTime" SG_ 2566897419 Trailer2EBSAmberWarning 100;
BA_ "GenSigCycleTimeActive" SG_ 2566897419 Trailer2EBSAmberWarning 100;
BA_ "GenSigStartValue" SG_ 2566897419 Trailer2EBSAmberWarning 3;
BA_ "GenSigCycleTime" SG_ 2566897419 Trailer2EBSRedWarning 100;
BA_ "GenSigCycleTimeActive" SG_ 2566897419 Trailer2EBSRedWarning 100;
BA_ "GenSigStartValue" SG_ 2566897419 Trailer2EBSRedWarning 3;
BA_ "GenSigCycleTime" SG_ 2566897419 Trailer2NomBodyLevel_RearLevel 100;
BA_ "GenSigCycleTimeActive" SG_ 2566897419 Trailer2NomBodyLevel_RearLevel 100;
BA_ "GenSigStartValue" SG_ 2566897419 Trailer2NomBodyLevel_RearLevel 65535;
BA_ "GenSigCycleTime" SG_ 2566897419 Trailer2PneumSupply_Pressure 100;
BA_ "GenSigCycleTimeActive" SG_ 2566897419 Trailer2PneumSupply_Pressure 100;
BA_ "GenSigStartValue" SG_ 2566897419 Trailer2PneumSupply_Pressure 255;
BA_ "GenSigCycleTime" SG_ 2566897419 Trailer2LoadRampApprAssistStat 100;
BA_ "GenSigCycleTimeActive" SG_ 2566897419 Trailer2LoadRampApprAssistStat 100;
BA_ "GenSigStartValue" SG_ 2566897419 Trailer2LoadRampApprAssistStat 3;
BA_ "GenSigCycleTime" SG_ 2566897419 Trailer2PneumSupply_Status 100;
BA_ "GenSigCycleTimeActive" SG_ 2566897419 Trailer2PneumSupply_Status 100;
BA_ "GenSigStartValue" SG_ 2566897419 Trailer2PneumSupply_Status 3;
BA_ "GenSigCycleTime" SG_ 2566897419 Trailer2NomBodyLevel_FrontLevel 100;
BA_ "GenSigCycleTimeActive" SG_ 2566897419 Trailer2NomBodyLevel_FrontLevel 100;
BA_ "GenSigStartValue" SG_ 2566897419 Trailer2NomBodyLevel_FrontLevel 65535;
BA_ "GenSigCycleTime" SG_ 2566897419 Trailer2YCSystemStatus 100;
BA_ "GenSigCycleTimeActive" SG_ 2566897419 Trailer2YCSystemStatus 100;
BA_ "GenSigStartValue" SG_ 2566897419 Trailer2YCSystemStatus 3;
BA_ "GenSigCycleTime" SG_ 2566897419 Trailer2ElectricalSupplyStat 100;
BA_ "GenSigCycleTimeActive" SG_ 2566897419 Trailer2ElectricalSupplyStat 100;
BA_ "GenSigStartValue" SG_ 2566897419 Trailer2ElectricalSupplyStat 3;
BA_ "GenSigCycleTime" SG_ 2566897419 Trailer2ROPSystemStatus 100;
BA_ "GenSigCycleTimeActive" SG_ 2566897419 Trailer2ROPSystemStatus 100;
BA_ "GenSigStartValue" SG_ 2566897419 Trailer2ROPSystemStatus 3;
BA_ "GenSigCycleTime" SG_ 2566897419 Trailer2ExtLvlStorageSupport 100;
BA_ "GenSigCycleTimeActive" SG_ 2566897419 Trailer2ExtLvlStorageSupport 100;
BA_ "GenSigStartValue" SG_ 2566897419 Trailer2ExtLvlStorageSupport 3;
BA_ "GenSigCycleTime" SG_ 2566892811 Trailer1NomBodyLevel_RearLevel 100;
BA_ "GenSigCycleTimeActive" SG_ 2566892811 Trailer1NomBodyLevel_RearLevel 100;
BA_ "GenSigStartValue" SG_ 2566892811 Trailer1NomBodyLevel_RearLevel 65535;
BA_ "GenSigCycleTime" SG_ 2566892811 Trailer1EBSRedWarning 100;
BA_ "GenSigCycleTimeActive" SG_ 2566892811 Trailer1EBSRedWarning 100;
BA_ "GenSigStartValue" SG_ 2566892811 Trailer1EBSRedWarning 3;
BA_ "GenSigCycleTime" SG_ 2566892811 Trailer1VehicleType 100;
BA_ "GenSigCycleTimeActive" SG_ 2566892811 Trailer1VehicleType 100;
BA_ "GenSigStartValue" SG_ 2566892811 Trailer1VehicleType 3;
BA_ "GenSigCycleTime" SG_ 2566892811 Trailer1LoadRampApprAssistStat 100;
BA_ "GenSigCycleTimeActive" SG_ 2566892811 Trailer1LoadRampApprAssistStat 100;
BA_ "GenSigStartValue" SG_ 2566892811 Trailer1LoadRampApprAssistStat 3;
BA_ "GenSigCycleTime" SG_ 2566892811 Trailer1YCSystemStatus 100;
BA_ "GenSigCycleTimeActive" SG_ 2566892811 Trailer1YCSystemStatus 100;
BA_ "GenSigStartValue" SG_ 2566892811 Trailer1YCSystemStatus 3;
BA_ "GenSigCycleTime" SG_ 2566892811 Trailer1EBSAmberWarning 100;
BA_ "GenSigCycleTimeActive" SG_ 2566892811 Trailer1EBSAmberWarning 100;
BA_ "GenSigStartValue" SG_ 2566892811 Trailer1EBSAmberWarning 3;
BA_ "GenSigCycleTime" SG_ 2566892811 Trailer1PneumSupply_Pressure 100;
BA_ "GenSigCycleTimeActive" SG_ 2566892811 Trailer1PneumSupply_Pressure 100;
BA_ "GenSigStartValue" SG_ 2566892811 Trailer1PneumSupply_Pressure 255;
BA_ "GenSigCycleTime" SG_ 2566892811 Trailer1ElectricalSupplyStat 100;
BA_ "GenSigCycleTimeActive" SG_ 2566892811 Trailer1ElectricalSupplyStat 100;
BA_ "GenSigStartValue" SG_ 2566892811 Trailer1ElectricalSupplyStat 3;
BA_ "GenSigCycleTime" SG_ 2566892811 Trailer1ROPSystemStatus 100;
BA_ "GenSigCycleTimeActive" SG_ 2566892811 Trailer1ROPSystemStatus 100;
BA_ "GenSigStartValue" SG_ 2566892811 Trailer1ROPSystemStatus 3;
BA_ "GenSigCycleTime" SG_ 2566892811 Trailer1NomBodyLevel_FrontLevel 100;
BA_ "GenSigCycleTimeActive" SG_ 2566892811 Trailer1NomBodyLevel_FrontLevel 100;
BA_ "GenSigStartValue" SG_ 2566892811 Trailer1NomBodyLevel_FrontLevel 65535;
BA_ "GenSigCycleTime" SG_ 2566892811 Trailer1PneumSupply_Status 100;
BA_ "GenSigCycleTimeActive" SG_ 2566892811 Trailer1PneumSupply_Status 100;
BA_ "GenSigStartValue" SG_ 2566892811 Trailer1PneumSupply_Status 3;
BA_ "GenSigCycleTime" SG_ 2566892811 Trailer1ExtLvlStorageSupport 100;
BA_ "GenSigCycleTimeActive" SG_ 2566892811 Trailer1ExtLvlStorageSupport 100;
BA_ "GenSigStartValue" SG_ 2566892811 Trailer1ExtLvlStorageSupport 3;
BA_ "GenSigCycleTime" SG_ 2566892811 Trailer1LevelControlStatus 100;
BA_ "GenSigCycleTimeActive" SG_ 2566892811 Trailer1LevelControlStatus 100;
BA_ "GenSigStartValue" SG_ 2566892811 Trailer1LevelControlStatus 3;
BA_ "GenSigCycleTime" SG_ 2566887947 Trailer5TireInfoISO_Leakage_ISig 100;
BA_ "GenSigCycleTimeActive" SG_ 2566887947 Trailer5TireInfoISO_Leakage_ISig 100;
BA_ "GenSigStartValue" SG_ 2566887947 Trailer5TireInfoISO_Leakage_ISig 65535;
BA_ "NeedsUpdateBit" SG_ 2566887947 Trailer5TireInfoISO_Leakage_ISig 1;
BA_ "SystemSignalLongSymbol" SG_ 2566887947 Trailer5TireInfoISO_Leakage_ISig "Trailer5TireInfoISO_Leakage_ISig_1";
BA_ "GenSigSendType" SG_ 2566887947 Trailer5TireInfoISO_sg_UB_ISig_1 7;
BA_ "Platform_VMCU1_Sig" SG_ 2566887947 Trailer5TireInfoISO_sg_UB_ISig_1 1;
BA_ "GenSigCycleTime" SG_ 2566887947 Trailer5TireInfoISO_PowerSupply_ 100;
BA_ "GenSigCycleTimeActive" SG_ 2566887947 Trailer5TireInfoISO_PowerSupply_ 100;
BA_ "GenSigStartValue" SG_ 2566887947 Trailer5TireInfoISO_PowerSupply_ 3;
BA_ "NeedsUpdateBit" SG_ 2566887947 Trailer5TireInfoISO_PowerSupply_ 1;
BA_ "SystemSignalLongSymbol" SG_ 2566887947 Trailer5TireInfoISO_PowerSupply_ "Trailer5TireInfoISO_PowerSupply_ISig_1";
BA_ "GenSigCycleTime" SG_ 2566887947 Trailer5TireInfoISO_TireId_ISig_ 100;
BA_ "GenSigCycleTimeActive" SG_ 2566887947 Trailer5TireInfoISO_TireId_ISig_ 100;
BA_ "NeedsUpdateBit" SG_ 2566887947 Trailer5TireInfoISO_TireId_ISig_ 1;
BA_ "SystemSignalLongSymbol" SG_ 2566887947 Trailer5TireInfoISO_TireId_ISig_ "Trailer5TireInfoISO_TireId_ISig_1";
BA_ "GenSigCycleTime" SG_ 2566887947 Trailer5TireInfoISO_Pressure_ISi 100;
BA_ "GenSigCycleTimeActive" SG_ 2566887947 Trailer5TireInfoISO_Pressure_ISi 100;
BA_ "GenSigStartValue" SG_ 2566887947 Trailer5TireInfoISO_Pressure_ISi 255;
BA_ "NeedsUpdateBit" SG_ 2566887947 Trailer5TireInfoISO_Pressure_ISi 1;
BA_ "SystemSignalLongSymbol" SG_ 2566887947 Trailer5TireInfoISO_Pressure_ISi "Trailer5TireInfoISO_Pressure_ISig_1";
BA_ "GenSigCycleTime" SG_ 2566887947 Trailer5TireInfoISO_Temperature_ 100;
BA_ "GenSigCycleTimeActive" SG_ 2566887947 Trailer5TireInfoISO_Temperature_ 100;
BA_ "GenSigStartValue" SG_ 2566887947 Trailer5TireInfoISO_Temperature_ 65535;
BA_ "NeedsUpdateBit" SG_ 2566887947 Trailer5TireInfoISO_Temperature_ 1;
BA_ "SystemSignalLongSymbol" SG_ 2566887947 Trailer5TireInfoISO_Temperature_ "Trailer5TireInfoISO_Temperature_ISig_1";
BA_ "GenSigCycleTime" SG_ 2566887947 Trailer5TireInfoISO_PresSuff_ISi 100;
BA_ "GenSigCycleTimeActive" SG_ 2566887947 Trailer5TireInfoISO_PresSuff_ISi 100;
BA_ "GenSigStartValue" SG_ 2566887947 Trailer5TireInfoISO_PresSuff_ISi 3;
BA_ "NeedsUpdateBit" SG_ 2566887947 Trailer5TireInfoISO_PresSuff_ISi 1;
BA_ "SystemSignalLongSymbol" SG_ 2566887947 Trailer5TireInfoISO_PresSuff_ISi "Trailer5TireInfoISO_PresSuff_ISig_1";
BA_ "GenSigCycleTime" SG_ 2566887947 Trailer5TireInfoISO_Warning_ISig 100;
BA_ "GenSigCycleTimeActive" SG_ 2566887947 Trailer5TireInfoISO_Warning_ISig 100;
BA_ "GenSigStartValue" SG_ 2566887947 Trailer5TireInfoISO_Warning_ISig 7;
BA_ "NeedsUpdateBit" SG_ 2566887947 Trailer5TireInfoISO_Warning_ISig 1;
BA_ "SystemSignalLongSymbol" SG_ 2566887947 Trailer5TireInfoISO_Warning_ISig "Trailer5TireInfoISO_Warning_ISig_1";
BA_ "GenSigCycleTime" SG_ 2566887947 Trailer5TireInfoISO_Active_ISig_ 100;
BA_ "GenSigCycleTimeActive" SG_ 2566887947 Trailer5TireInfoISO_Active_ISig_ 100;
BA_ "GenSigStartValue" SG_ 2566887947 Trailer5TireInfoISO_Active_ISig_ 3;
BA_ "NeedsUpdateBit" SG_ 2566887947 Trailer5TireInfoISO_Active_ISig_ 1;
BA_ "SystemSignalLongSymbol" SG_ 2566887947 Trailer5TireInfoISO_Active_ISig_ "Trailer5TireInfoISO_Active_ISig_1";
BA_ "GenSigCycleTime" SG_ 2566883339 Trailer4TireInfoISO_Temperature_ 100;
BA_ "GenSigCycleTimeActive" SG_ 2566883339 Trailer4TireInfoISO_Temperature_ 100;
BA_ "GenSigStartValue" SG_ 2566883339 Trailer4TireInfoISO_Temperature_ 65535;
BA_ "NeedsUpdateBit" SG_ 2566883339 Trailer4TireInfoISO_Temperature_ 1;
BA_ "SystemSignalLongSymbol" SG_ 2566883339 Trailer4TireInfoISO_Temperature_ "Trailer4TireInfoISO_Temperature_ISig_1";
BA_ "GenSigCycleTime" SG_ 2566883339 Trailer4TireInfoISO_TireId_ISig_ 100;
BA_ "GenSigCycleTimeActive" SG_ 2566883339 Trailer4TireInfoISO_TireId_ISig_ 100;
BA_ "NeedsUpdateBit" SG_ 2566883339 Trailer4TireInfoISO_TireId_ISig_ 1;
BA_ "SystemSignalLongSymbol" SG_ 2566883339 Trailer4TireInfoISO_TireId_ISig_ "Trailer4TireInfoISO_TireId_ISig_1";
BA_ "GenSigCycleTime" SG_ 2566883339 Trailer4TireInfoISO_PowerSupply_ 100;
BA_ "GenSigCycleTimeActive" SG_ 2566883339 Trailer4TireInfoISO_PowerSupply_ 100;
BA_ "GenSigStartValue" SG_ 2566883339 Trailer4TireInfoISO_PowerSupply_ 3;
BA_ "NeedsUpdateBit" SG_ 2566883339 Trailer4TireInfoISO_PowerSupply_ 1;
BA_ "SystemSignalLongSymbol" SG_ 2566883339 Trailer4TireInfoISO_PowerSupply_ "Trailer4TireInfoISO_PowerSupply_ISig_1";
BA_ "GenSigCycleTime" SG_ 2566883339 Trailer4TireInfoISO_Warning_ISig 100;
BA_ "GenSigCycleTimeActive" SG_ 2566883339 Trailer4TireInfoISO_Warning_ISig 100;
BA_ "GenSigStartValue" SG_ 2566883339 Trailer4TireInfoISO_Warning_ISig 7;
BA_ "NeedsUpdateBit" SG_ 2566883339 Trailer4TireInfoISO_Warning_ISig 1;
BA_ "SystemSignalLongSymbol" SG_ 2566883339 Trailer4TireInfoISO_Warning_ISig "Trailer4TireInfoISO_Warning_ISig_1";
BA_ "GenSigCycleTime" SG_ 2566883339 Trailer4TireInfoISO_Pressure_ISi 100;
BA_ "GenSigCycleTimeActive" SG_ 2566883339 Trailer4TireInfoISO_Pressure_ISi 100;
BA_ "GenSigStartValue" SG_ 2566883339 Trailer4TireInfoISO_Pressure_ISi 255;
BA_ "NeedsUpdateBit" SG_ 2566883339 Trailer4TireInfoISO_Pressure_ISi 1;
BA_ "SystemSignalLongSymbol" SG_ 2566883339 Trailer4TireInfoISO_Pressure_ISi "Trailer4TireInfoISO_Pressure_ISig_1";
BA_ "GenSigCycleTime" SG_ 2566883339 Trailer4TireInfoISO_Leakage_ISig 100;
BA_ "GenSigCycleTimeActive" SG_ 2566883339 Trailer4TireInfoISO_Leakage_ISig 100;
BA_ "GenSigStartValue" SG_ 2566883339 Trailer4TireInfoISO_Leakage_ISig 65535;
BA_ "NeedsUpdateBit" SG_ 2566883339 Trailer4TireInfoISO_Leakage_ISig 1;
BA_ "SystemSignalLongSymbol" SG_ 2566883339 Trailer4TireInfoISO_Leakage_ISig "Trailer4TireInfoISO_Leakage_ISig_1";
BA_ "GenSigCycleTime" SG_ 2566883339 Trailer4TireInfoISO_Active_ISig_ 100;
BA_ "GenSigCycleTimeActive" SG_ 2566883339 Trailer4TireInfoISO_Active_ISig_ 100;
BA_ "GenSigStartValue" SG_ 2566883339 Trailer4TireInfoISO_Active_ISig_ 3;
BA_ "NeedsUpdateBit" SG_ 2566883339 Trailer4TireInfoISO_Active_ISig_ 1;
BA_ "SystemSignalLongSymbol" SG_ 2566883339 Trailer4TireInfoISO_Active_ISig_ "Trailer4TireInfoISO_Active_ISig_1";
BA_ "GenSigCycleTime" SG_ 2566883339 Trailer4TireInfoISO_PresSuff_ISi 100;
BA_ "GenSigCycleTimeActive" SG_ 2566883339 Trailer4TireInfoISO_PresSuff_ISi 100;
BA_ "GenSigStartValue" SG_ 2566883339 Trailer4TireInfoISO_PresSuff_ISi 3;
BA_ "NeedsUpdateBit" SG_ 2566883339 Trailer4TireInfoISO_PresSuff_ISi 1;
BA_ "SystemSignalLongSymbol" SG_ 2566883339 Trailer4TireInfoISO_PresSuff_ISi "Trailer4TireInfoISO_PresSuff_ISig_1";
BA_ "GenSigSendType" SG_ 2566883339 Trailer4TireInfoISO_sg_UB_ISig_1 7;
BA_ "Platform_VMCU1_Sig" SG_ 2566883339 Trailer4TireInfoISO_sg_UB_ISig_1 1;
BA_ "GenSigCycleTime" SG_ 2566878731 Trailer3TireInfoISO_Pressure_ISi 100;
BA_ "GenSigCycleTimeActive" SG_ 2566878731 Trailer3TireInfoISO_Pressure_ISi 100;
BA_ "GenSigStartValue" SG_ 2566878731 Trailer3TireInfoISO_Pressure_ISi 255;
BA_ "NeedsUpdateBit" SG_ 2566878731 Trailer3TireInfoISO_Pressure_ISi 1;
BA_ "SystemSignalLongSymbol" SG_ 2566878731 Trailer3TireInfoISO_Pressure_ISi "Trailer3TireInfoISO_Pressure_ISig_1";
BA_ "GenSigSendType" SG_ 2566878731 Trailer3TireInfoISO_sg_UB_ISig_1 7;
BA_ "Platform_VMCU1_Sig" SG_ 2566878731 Trailer3TireInfoISO_sg_UB_ISig_1 1;
BA_ "GenSigCycleTime" SG_ 2566878731 Trailer3TireInfoISO_PowerSupply_ 100;
BA_ "GenSigCycleTimeActive" SG_ 2566878731 Trailer3TireInfoISO_PowerSupply_ 100;
BA_ "GenSigStartValue" SG_ 2566878731 Trailer3TireInfoISO_PowerSupply_ 3;
BA_ "NeedsUpdateBit" SG_ 2566878731 Trailer3TireInfoISO_PowerSupply_ 1;
BA_ "SystemSignalLongSymbol" SG_ 2566878731 Trailer3TireInfoISO_PowerSupply_ "Trailer3TireInfoISO_PowerSupply_ISig_1";
BA_ "GenSigCycleTime" SG_ 2566878731 Trailer3TireInfoISO_PresSuff_ISi 100;
BA_ "GenSigCycleTimeActive" SG_ 2566878731 Trailer3TireInfoISO_PresSuff_ISi 100;
BA_ "GenSigStartValue" SG_ 2566878731 Trailer3TireInfoISO_PresSuff_ISi 3;
BA_ "NeedsUpdateBit" SG_ 2566878731 Trailer3TireInfoISO_PresSuff_ISi 1;
BA_ "SystemSignalLongSymbol" SG_ 2566878731 Trailer3TireInfoISO_PresSuff_ISi "Trailer3TireInfoISO_PresSuff_ISig_1";
BA_ "GenSigCycleTime" SG_ 2566878731 Trailer3TireInfoISO_Temperature_ 100;
BA_ "GenSigCycleTimeActive" SG_ 2566878731 Trailer3TireInfoISO_Temperature_ 100;
BA_ "GenSigStartValue" SG_ 2566878731 Trailer3TireInfoISO_Temperature_ 65535;
BA_ "NeedsUpdateBit" SG_ 2566878731 Trailer3TireInfoISO_Temperature_ 1;
BA_ "SystemSignalLongSymbol" SG_ 2566878731 Trailer3TireInfoISO_Temperature_ "Trailer3TireInfoISO_Temperature_ISig_1";
BA_ "GenSigCycleTime" SG_ 2566878731 Trailer3TireInfoISO_TireId_ISig_ 100;
BA_ "GenSigCycleTimeActive" SG_ 2566878731 Trailer3TireInfoISO_TireId_ISig_ 100;
BA_ "NeedsUpdateBit" SG_ 2566878731 Trailer3TireInfoISO_TireId_ISig_ 1;
BA_ "SystemSignalLongSymbol" SG_ 2566878731 Trailer3TireInfoISO_TireId_ISig_ "Trailer3TireInfoISO_TireId_ISig_1";
BA_ "GenSigCycleTime" SG_ 2566878731 Trailer3TireInfoISO_Leakage_ISig 100;
BA_ "GenSigCycleTimeActive" SG_ 2566878731 Trailer3TireInfoISO_Leakage_ISig 100;
BA_ "GenSigStartValue" SG_ 2566878731 Trailer3TireInfoISO_Leakage_ISig 65535;
BA_ "NeedsUpdateBit" SG_ 2566878731 Trailer3TireInfoISO_Leakage_ISig 1;
BA_ "SystemSignalLongSymbol" SG_ 2566878731 Trailer3TireInfoISO_Leakage_ISig "Trailer3TireInfoISO_Leakage_ISig_1";
BA_ "GenSigCycleTime" SG_ 2566878731 Trailer3TireInfoISO_Active_ISig_ 100;
BA_ "GenSigCycleTimeActive" SG_ 2566878731 Trailer3TireInfoISO_Active_ISig_ 100;
BA_ "GenSigStartValue" SG_ 2566878731 Trailer3TireInfoISO_Active_ISig_ 3;
BA_ "NeedsUpdateBit" SG_ 2566878731 Trailer3TireInfoISO_Active_ISig_ 1;
BA_ "SystemSignalLongSymbol" SG_ 2566878731 Trailer3TireInfoISO_Active_ISig_ "Trailer3TireInfoISO_Active_ISig_1";
BA_ "GenSigCycleTime" SG_ 2566878731 Trailer3TireInfoISO_Warning_ISig 100;
BA_ "GenSigCycleTimeActive" SG_ 2566878731 Trailer3TireInfoISO_Warning_ISig 100;
BA_ "GenSigStartValue" SG_ 2566878731 Trailer3TireInfoISO_Warning_ISig 7;
BA_ "NeedsUpdateBit" SG_ 2566878731 Trailer3TireInfoISO_Warning_ISig 1;
BA_ "SystemSignalLongSymbol" SG_ 2566878731 Trailer3TireInfoISO_Warning_ISig "Trailer3TireInfoISO_Warning_ISig_1";
BA_ "GenSigCycleTime" SG_ 2566874123 Trailer2TireInfoISO_Warning_ISig 100;
BA_ "GenSigCycleTimeActive" SG_ 2566874123 Trailer2TireInfoISO_Warning_ISig 100;
BA_ "GenSigStartValue" SG_ 2566874123 Trailer2TireInfoISO_Warning_ISig 7;
BA_ "NeedsUpdateBit" SG_ 2566874123 Trailer2TireInfoISO_Warning_ISig 1;
BA_ "SystemSignalLongSymbol" SG_ 2566874123 Trailer2TireInfoISO_Warning_ISig "Trailer2TireInfoISO_Warning_ISig_1";
BA_ "GenSigSendType" SG_ 2566874123 Trailer2TireInfoISO_sg_UB_ISig_1 7;
BA_ "Platform_VMCU1_Sig" SG_ 2566874123 Trailer2TireInfoISO_sg_UB_ISig_1 1;
BA_ "GenSigCycleTime" SG_ 2566874123 Trailer2TireInfoISO_Leakage_ISig 100;
BA_ "GenSigCycleTimeActive" SG_ 2566874123 Trailer2TireInfoISO_Leakage_ISig 100;
BA_ "GenSigStartValue" SG_ 2566874123 Trailer2TireInfoISO_Leakage_ISig 65535;
BA_ "NeedsUpdateBit" SG_ 2566874123 Trailer2TireInfoISO_Leakage_ISig 1;
BA_ "SystemSignalLongSymbol" SG_ 2566874123 Trailer2TireInfoISO_Leakage_ISig "Trailer2TireInfoISO_Leakage_ISig_1";
BA_ "GenSigCycleTime" SG_ 2566874123 Trailer2TireInfoISO_PresSuff_ISi 100;
BA_ "GenSigCycleTimeActive" SG_ 2566874123 Trailer2TireInfoISO_PresSuff_ISi 100;
BA_ "GenSigStartValue" SG_ 2566874123 Trailer2TireInfoISO_PresSuff_ISi 3;
BA_ "NeedsUpdateBit" SG_ 2566874123 Trailer2TireInfoISO_PresSuff_ISi 1;
BA_ "SystemSignalLongSymbol" SG_ 2566874123 Trailer2TireInfoISO_PresSuff_ISi "Trailer2TireInfoISO_PresSuff_ISig_1";
BA_ "GenSigCycleTime" SG_ 2566874123 Trailer2TireInfoISO_Pressure_ISi 100;
BA_ "GenSigCycleTimeActive" SG_ 2566874123 Trailer2TireInfoISO_Pressure_ISi 100;
BA_ "GenSigStartValue" SG_ 2566874123 Trailer2TireInfoISO_Pressure_ISi 255;
BA_ "NeedsUpdateBit" SG_ 2566874123 Trailer2TireInfoISO_Pressure_ISi 1;
BA_ "SystemSignalLongSymbol" SG_ 2566874123 Trailer2TireInfoISO_Pressure_ISi "Trailer2TireInfoISO_Pressure_ISig_1";
BA_ "GenSigCycleTime" SG_ 2566874123 Trailer2TireInfoISO_Temperature_ 100;
BA_ "GenSigCycleTimeActive" SG_ 2566874123 Trailer2TireInfoISO_Temperature_ 100;
BA_ "GenSigStartValue" SG_ 2566874123 Trailer2TireInfoISO_Temperature_ 65535;
BA_ "NeedsUpdateBit" SG_ 2566874123 Trailer2TireInfoISO_Temperature_ 1;
BA_ "SystemSignalLongSymbol" SG_ 2566874123 Trailer2TireInfoISO_Temperature_ "Trailer2TireInfoISO_Temperature_ISig_1";
BA_ "GenSigCycleTime" SG_ 2566874123 Trailer2TireInfoISO_PowerSupply_ 100;
BA_ "GenSigCycleTimeActive" SG_ 2566874123 Trailer2TireInfoISO_PowerSupply_ 100;
BA_ "GenSigStartValue" SG_ 2566874123 Trailer2TireInfoISO_PowerSupply_ 3;
BA_ "NeedsUpdateBit" SG_ 2566874123 Trailer2TireInfoISO_PowerSupply_ 1;
BA_ "SystemSignalLongSymbol" SG_ 2566874123 Trailer2TireInfoISO_PowerSupply_ "Trailer2TireInfoISO_PowerSupply_ISig_1";
BA_ "GenSigCycleTime" SG_ 2566874123 Trailer2TireInfoISO_TireId_ISig_ 100;
BA_ "GenSigCycleTimeActive" SG_ 2566874123 Trailer2TireInfoISO_TireId_ISig_ 100;
BA_ "NeedsUpdateBit" SG_ 2566874123 Trailer2TireInfoISO_TireId_ISig_ 1;
BA_ "SystemSignalLongSymbol" SG_ 2566874123 Trailer2TireInfoISO_TireId_ISig_ "Trailer2TireInfoISO_TireId_ISig_1";
BA_ "GenSigCycleTime" SG_ 2566874123 Trailer2TireInfoISO_Active_ISig_ 100;
BA_ "GenSigCycleTimeActive" SG_ 2566874123 Trailer2TireInfoISO_Active_ISig_ 100;
BA_ "GenSigStartValue" SG_ 2566874123 Trailer2TireInfoISO_Active_ISig_ 3;
BA_ "NeedsUpdateBit" SG_ 2566874123 Trailer2TireInfoISO_Active_ISig_ 1;
BA_ "SystemSignalLongSymbol" SG_ 2566874123 Trailer2TireInfoISO_Active_ISig_ "Trailer2TireInfoISO_Active_ISig_1";
BA_ "GenSigCycleTime" SG_ 2566869259 Trailer1TireInfoISO_Active_ISig_ 100;
BA_ "GenSigCycleTimeActive" SG_ 2566869259 Trailer1TireInfoISO_Active_ISig_ 100;
BA_ "GenSigStartValue" SG_ 2566869259 Trailer1TireInfoISO_Active_ISig_ 3;
BA_ "NeedsUpdateBit" SG_ 2566869259 Trailer1TireInfoISO_Active_ISig_ 1;
BA_ "SystemSignalLongSymbol" SG_ 2566869259 Trailer1TireInfoISO_Active_ISig_ "Trailer1TireInfoISO_Active_ISig_1";
BA_ "GenSigCycleTime" SG_ 2566869259 Trailer1TireInfoISO_PowerSupply_ 100;
BA_ "GenSigCycleTimeActive" SG_ 2566869259 Trailer1TireInfoISO_PowerSupply_ 100;
BA_ "GenSigStartValue" SG_ 2566869259 Trailer1TireInfoISO_PowerSupply_ 3;
BA_ "NeedsUpdateBit" SG_ 2566869259 Trailer1TireInfoISO_PowerSupply_ 1;
BA_ "SystemSignalLongSymbol" SG_ 2566869259 Trailer1TireInfoISO_PowerSupply_ "Trailer1TireInfoISO_PowerSupply_ISig_1";
BA_ "GenSigCycleTime" SG_ 2566869259 Trailer1TireInfoISO_PresSuff_ISi 100;
BA_ "GenSigCycleTimeActive" SG_ 2566869259 Trailer1TireInfoISO_PresSuff_ISi 100;
BA_ "GenSigStartValue" SG_ 2566869259 Trailer1TireInfoISO_PresSuff_ISi 3;
BA_ "NeedsUpdateBit" SG_ 2566869259 Trailer1TireInfoISO_PresSuff_ISi 1;
BA_ "SystemSignalLongSymbol" SG_ 2566869259 Trailer1TireInfoISO_PresSuff_ISi "Trailer1TireInfoISO_PresSuff_ISig_1";
BA_ "GenSigCycleTime" SG_ 2566869259 Trailer1TireInfoISO_Warning_ISig 100;
BA_ "GenSigCycleTimeActive" SG_ 2566869259 Trailer1TireInfoISO_Warning_ISig 100;
BA_ "GenSigStartValue" SG_ 2566869259 Trailer1TireInfoISO_Warning_ISig 7;
BA_ "NeedsUpdateBit" SG_ 2566869259 Trailer1TireInfoISO_Warning_ISig 1;
BA_ "SystemSignalLongSymbol" SG_ 2566869259 Trailer1TireInfoISO_Warning_ISig "Trailer1TireInfoISO_Warning_ISig_1";
BA_ "GenSigCycleTime" SG_ 2566869259 Trailer1TireInfoISO_TireId_ISig_ 100;
BA_ "GenSigCycleTimeActive" SG_ 2566869259 Trailer1TireInfoISO_TireId_ISig_ 100;
BA_ "NeedsUpdateBit" SG_ 2566869259 Trailer1TireInfoISO_TireId_ISig_ 1;
BA_ "SystemSignalLongSymbol" SG_ 2566869259 Trailer1TireInfoISO_TireId_ISig_ "Trailer1TireInfoISO_TireId_ISig_1";
BA_ "GenSigSendType" SG_ 2566869259 Trailer1TireInfoISO_sg_UB_ISig_1 7;
BA_ "Platform_VMCU1_Sig" SG_ 2566869259 Trailer1TireInfoISO_sg_UB_ISig_1 1;
BA_ "GenSigCycleTime" SG_ 2566869259 Trailer1TireInfoISO_Pressure_ISi 100;
BA_ "GenSigCycleTimeActive" SG_ 2566869259 Trailer1TireInfoISO_Pressure_ISi 100;
BA_ "GenSigStartValue" SG_ 2566869259 Trailer1TireInfoISO_Pressure_ISi 255;
BA_ "NeedsUpdateBit" SG_ 2566869259 Trailer1TireInfoISO_Pressure_ISi 1;
BA_ "SystemSignalLongSymbol" SG_ 2566869259 Trailer1TireInfoISO_Pressure_ISi "Trailer1TireInfoISO_Pressure_ISig_1";
BA_ "GenSigCycleTime" SG_ 2566869259 Trailer1TireInfoISO_Leakage_ISig 100;
BA_ "GenSigCycleTimeActive" SG_ 2566869259 Trailer1TireInfoISO_Leakage_ISig 100;
BA_ "GenSigStartValue" SG_ 2566869259 Trailer1TireInfoISO_Leakage_ISig 65535;
BA_ "NeedsUpdateBit" SG_ 2566869259 Trailer1TireInfoISO_Leakage_ISig 1;
BA_ "SystemSignalLongSymbol" SG_ 2566869259 Trailer1TireInfoISO_Leakage_ISig "Trailer1TireInfoISO_Leakage_ISig_1";
BA_ "GenSigCycleTime" SG_ 2566869259 Trailer1TireInfoISO_Temperature_ 100;
BA_ "GenSigCycleTimeActive" SG_ 2566869259 Trailer1TireInfoISO_Temperature_ 100;
BA_ "GenSigStartValue" SG_ 2566869259 Trailer1TireInfoISO_Temperature_ 65535;
BA_ "NeedsUpdateBit" SG_ 2566869259 Trailer1TireInfoISO_Temperature_ 1;
BA_ "SystemSignalLongSymbol" SG_ 2566869259 Trailer1TireInfoISO_Temperature_ "Trailer1TireInfoISO_Temperature_ISig_1";
BA_ "GenSigCycleTime" SG_ 2566864651 Trailer5BrakeTemp_TireId 100;
BA_ "GenSigCycleTimeActive" SG_ 2566864651 Trailer5BrakeTemp_TireId 100;
BA_ "GenSigStartValue" SG_ 2566864651 Trailer5BrakeTemp_TireId 255;
BA_ "GenSigCycleTime" SG_ 2566864651 Trailer5BrakeTemp_Temp 100;
BA_ "GenSigCycleTimeActive" SG_ 2566864651 Trailer5BrakeTemp_Temp 100;
BA_ "GenSigStartValue" SG_ 2566864651 Trailer5BrakeTemp_Temp 255;
BA_ "GenSigCycleTime" SG_ 2566864651 Trailer4BrakeTemp_Temp 100;
BA_ "GenSigCycleTimeActive" SG_ 2566864651 Trailer4BrakeTemp_Temp 100;
BA_ "GenSigStartValue" SG_ 2566864651 Trailer4BrakeTemp_Temp 255;
BA_ "GenSigCycleTime" SG_ 2566864651 Trailer4BrakeTemp_TireId 100;
BA_ "GenSigCycleTimeActive" SG_ 2566864651 Trailer4BrakeTemp_TireId 100;
BA_ "GenSigStartValue" SG_ 2566864651 Trailer4BrakeTemp_TireId 255;
BA_ "GenSigCycleTime" SG_ 2566864651 Trailer4BrakeTemp_Status 100;
BA_ "GenSigCycleTimeActive" SG_ 2566864651 Trailer4BrakeTemp_Status 100;
BA_ "GenSigStartValue" SG_ 2566864651 Trailer4BrakeTemp_Status 3;
BA_ "GenSigCycleTime" SG_ 2566864651 Trailer5BrakeTemp_Status 100;
BA_ "GenSigCycleTimeActive" SG_ 2566864651 Trailer5BrakeTemp_Status 100;
BA_ "GenSigStartValue" SG_ 2566864651 Trailer5BrakeTemp_Status 3;
BA_ "GenSigCycleTime" SG_ 2566860043 Trailer2BrakeTemp_Temp 100;
BA_ "GenSigCycleTimeActive" SG_ 2566860043 Trailer2BrakeTemp_Temp 100;
BA_ "GenSigStartValue" SG_ 2566860043 Trailer2BrakeTemp_Temp 255;
BA_ "GenSigCycleTime" SG_ 2566860043 Trailer3BrakeTemp_Status 100;
BA_ "GenSigCycleTimeActive" SG_ 2566860043 Trailer3BrakeTemp_Status 100;
BA_ "GenSigStartValue" SG_ 2566860043 Trailer3BrakeTemp_Status 3;
BA_ "GenSigCycleTime" SG_ 2566860043 Trailer3BrakeTemp_Temp 100;
BA_ "GenSigCycleTimeActive" SG_ 2566860043 Trailer3BrakeTemp_Temp 100;
BA_ "GenSigStartValue" SG_ 2566860043 Trailer3BrakeTemp_Temp 255;
BA_ "GenSigCycleTime" SG_ 2566860043 Trailer1BrakeTemp_Status 100;
BA_ "GenSigCycleTimeActive" SG_ 2566860043 Trailer1BrakeTemp_Status 100;
BA_ "GenSigStartValue" SG_ 2566860043 Trailer1BrakeTemp_Status 3;
BA_ "GenSigCycleTime" SG_ 2566860043 Trailer2BrakeTemp_TireId 100;
BA_ "GenSigCycleTimeActive" SG_ 2566860043 Trailer2BrakeTemp_TireId 100;
BA_ "GenSigStartValue" SG_ 2566860043 Trailer2BrakeTemp_TireId 255;
BA_ "GenSigCycleTime" SG_ 2566860043 Trailer2BrakeTemp_Status 100;
BA_ "GenSigCycleTimeActive" SG_ 2566860043 Trailer2BrakeTemp_Status 100;
BA_ "GenSigStartValue" SG_ 2566860043 Trailer2BrakeTemp_Status 3;
BA_ "GenSigCycleTime" SG_ 2566860043 Trailer3BrakeTemp_TireId 100;
BA_ "GenSigCycleTimeActive" SG_ 2566860043 Trailer3BrakeTemp_TireId 100;
BA_ "GenSigStartValue" SG_ 2566860043 Trailer3BrakeTemp_TireId 255;
BA_ "GenSigCycleTime" SG_ 2566860043 Trailer1BrakeTemp_TireId 100;
BA_ "GenSigCycleTimeActive" SG_ 2566860043 Trailer1BrakeTemp_TireId 100;
BA_ "GenSigStartValue" SG_ 2566860043 Trailer1BrakeTemp_TireId 255;
BA_ "GenSigCycleTime" SG_ 2566860043 Trailer1BrakeTemp_Temp 100;
BA_ "GenSigCycleTimeActive" SG_ 2566860043 Trailer1BrakeTemp_Temp 100;
BA_ "GenSigStartValue" SG_ 2566860043 Trailer1BrakeTemp_Temp 255;
BA_ "GenSigCycleTime" SG_ 2566855435 Trailer1ABSStatus 100;
BA_ "GenSigCycleTimeActive" SG_ 2566855435 Trailer1ABSStatus 100;
BA_ "GenSigStartValue" SG_ 2566855435 Trailer1ABSStatus 3;
BA_ "GenSigCycleTime" SG_ 2566855435 Trailer4ABSStatus 100;
BA_ "GenSigCycleTimeActive" SG_ 2566855435 Trailer4ABSStatus 100;
BA_ "GenSigStartValue" SG_ 2566855435 Trailer4ABSStatus 3;
BA_ "GenSigCycleTime" SG_ 2566855435 Trailer1LateralAcceleration 100;
BA_ "GenSigCycleTimeActive" SG_ 2566855435 Trailer1LateralAcceleration 100;
BA_ "GenSigStartValue" SG_ 2566855435 Trailer1LateralAcceleration 255;
BA_ "GenSigCycleTime" SG_ 2566855435 Trailer2ABSStatus 100;
BA_ "GenSigCycleTimeActive" SG_ 2566855435 Trailer2ABSStatus 100;
BA_ "GenSigStartValue" SG_ 2566855435 Trailer2ABSStatus 3;
BA_ "GenSigCycleTime" SG_ 2566855435 Trailer5ABSStatus 100;
BA_ "GenSigCycleTimeActive" SG_ 2566855435 Trailer5ABSStatus 100;
BA_ "GenSigStartValue" SG_ 2566855435 Trailer5ABSStatus 3;
BA_ "GenSigCycleTime" SG_ 2566855435 Trailer1WheelSpdDiffMainAxle 100;
BA_ "GenSigCycleTimeActive" SG_ 2566855435 Trailer1WheelSpdDiffMainAxle 100;
BA_ "GenSigStartValue" SG_ 2566855435 Trailer1WheelSpdDiffMainAxle 65535;
BA_ "GenSigCycleTime" SG_ 2566855435 Trailer3ABSStatus 100;
BA_ "GenSigCycleTimeActive" SG_ 2566855435 Trailer3ABSStatus 100;
BA_ "GenSigStartValue" SG_ 2566855435 Trailer3ABSStatus 3;
BA_ "GenSigCycleTime" SG_ 2566850827 Trailer4StopLevelChangeAck 100;
BA_ "GenSigCycleTimeActive" SG_ 2566850827 Trailer4StopLevelChangeAck 100;
BA_ "GenSigStartValue" SG_ 2566850827 Trailer4StopLevelChangeAck 3;
BA_ "GenSigCycleTime" SG_ 2566850827 Trailer4NormalLevelStorStat 100;
BA_ "GenSigCycleTimeActive" SG_ 2566850827 Trailer4NormalLevelStorStat 100;
BA_ "GenSigStartValue" SG_ 2566850827 Trailer4NormalLevelStorStat 3;
BA_ "GenSigCycleTime" SG_ 2566850827 Trailer2StopLevelChangeAck 100;
BA_ "GenSigCycleTimeActive" SG_ 2566850827 Trailer2StopLevelChangeAck 100;
BA_ "GenSigStartValue" SG_ 2566850827 Trailer2StopLevelChangeAck 3;
BA_ "GenSigCycleTime" SG_ 2566850827 Trailer4RampLevelStorStat 100;
BA_ "GenSigCycleTimeActive" SG_ 2566850827 Trailer4RampLevelStorStat 100;
BA_ "GenSigStartValue" SG_ 2566850827 Trailer4RampLevelStorStat 3;
BA_ "GenSigCycleTime" SG_ 2566850827 Trailer5NormalLevelStorStat 100;
BA_ "GenSigCycleTimeActive" SG_ 2566850827 Trailer5NormalLevelStorStat 100;
BA_ "GenSigStartValue" SG_ 2566850827 Trailer5NormalLevelStorStat 3;
BA_ "GenSigCycleTime" SG_ 2566850827 Trailer5LevelChangeFrontAxle 100;
BA_ "GenSigCycleTimeActive" SG_ 2566850827 Trailer5LevelChangeFrontAxle 100;
BA_ "GenSigStartValue" SG_ 2566850827 Trailer5LevelChangeFrontAxle 3;
BA_ "GenSigCycleTime" SG_ 2566850827 Trailer3NormalLevelStorStat 100;
BA_ "GenSigCycleTimeActive" SG_ 2566850827 Trailer3NormalLevelStorStat 100;
BA_ "GenSigStartValue" SG_ 2566850827 Trailer3NormalLevelStorStat 3;
BA_ "GenSigCycleTime" SG_ 2566850827 Trailer2NormalLevelStorStat 100;
BA_ "GenSigCycleTimeActive" SG_ 2566850827 Trailer2NormalLevelStorStat 100;
BA_ "GenSigStartValue" SG_ 2566850827 Trailer2NormalLevelStorStat 3;
BA_ "GenSigCycleTime" SG_ 2566850827 Trailer4TractionHelp 100;
BA_ "GenSigCycleTimeActive" SG_ 2566850827 Trailer4TractionHelp 100;
BA_ "GenSigStartValue" SG_ 2566850827 Trailer4TractionHelp 3;
BA_ "GenSigCycleTime" SG_ 2566850827 Trailer5StopLevelChangeAck 100;
BA_ "GenSigCycleTimeActive" SG_ 2566850827 Trailer5StopLevelChangeAck 100;
BA_ "GenSigStartValue" SG_ 2566850827 Trailer5StopLevelChangeAck 3;
BA_ "GenSigCycleTime" SG_ 2566850827 Trailer1LevelChangeRearAxle 100;
BA_ "GenSigCycleTimeActive" SG_ 2566850827 Trailer1LevelChangeRearAxle 100;
BA_ "GenSigStartValue" SG_ 2566850827 Trailer1LevelChangeRearAxle 3;
BA_ "GenSigCycleTime" SG_ 2566850827 Trailer4LevelChangeRearAxle 100;
BA_ "GenSigCycleTimeActive" SG_ 2566850827 Trailer4LevelChangeRearAxle 100;
BA_ "GenSigStartValue" SG_ 2566850827 Trailer4LevelChangeRearAxle 3;
BA_ "GenSigCycleTime" SG_ 2566850827 Trailer3LevelChangeRearAxle 100;
BA_ "GenSigCycleTimeActive" SG_ 2566850827 Trailer3LevelChangeRearAxle 100;
BA_ "GenSigStartValue" SG_ 2566850827 Trailer3LevelChangeRearAxle 3;
BA_ "GenSigCycleTime" SG_ 2566850827 Trailer3TractionHelp 100;
BA_ "GenSigCycleTimeActive" SG_ 2566850827 Trailer3TractionHelp 100;
BA_ "GenSigStartValue" SG_ 2566850827 Trailer3TractionHelp 3;
BA_ "GenSigCycleTime" SG_ 2566850827 Trailer2LevelChangeRearAxle 100;
BA_ "GenSigCycleTimeActive" SG_ 2566850827 Trailer2LevelChangeRearAxle 100;
BA_ "GenSigStartValue" SG_ 2566850827 Trailer2LevelChangeRearAxle 3;
BA_ "GenSigCycleTime" SG_ 2566850827 Trailer2RampLevelStorStat 100;
BA_ "GenSigCycleTimeActive" SG_ 2566850827 Trailer2RampLevelStorStat 100;
BA_ "GenSigStartValue" SG_ 2566850827 Trailer2RampLevelStorStat 3;
BA_ "GenSigCycleTime" SG_ 2566850827 Trailer3StopLevelChangeAck 100;
BA_ "GenSigCycleTimeActive" SG_ 2566850827 Trailer3StopLevelChangeAck 100;
BA_ "GenSigStartValue" SG_ 2566850827 Trailer3StopLevelChangeAck 3;
BA_ "GenSigCycleTime" SG_ 2566850827 Trailer5LevelChangeRearAxle 100;
BA_ "GenSigCycleTimeActive" SG_ 2566850827 Trailer5LevelChangeRearAxle 100;
BA_ "GenSigStartValue" SG_ 2566850827 Trailer5LevelChangeRearAxle 3;
BA_ "GenSigCycleTime" SG_ 2566850827 Trailer4LevelChangeFrontAxle 100;
BA_ "GenSigCycleTimeActive" SG_ 2566850827 Trailer4LevelChangeFrontAxle 100;
BA_ "GenSigStartValue" SG_ 2566850827 Trailer4LevelChangeFrontAxle 3;
BA_ "GenSigCycleTime" SG_ 2566850827 Trailer2TractionHelp 100;
BA_ "GenSigCycleTimeActive" SG_ 2566850827 Trailer2TractionHelp 100;
BA_ "GenSigStartValue" SG_ 2566850827 Trailer2TractionHelp 3;
BA_ "GenSigCycleTime" SG_ 2566850827 Trailer1RampLevelStorStat 100;
BA_ "GenSigCycleTimeActive" SG_ 2566850827 Trailer1RampLevelStorStat 100;
BA_ "GenSigStartValue" SG_ 2566850827 Trailer1RampLevelStorStat 3;
BA_ "GenSigCycleTime" SG_ 2566850827 Trailer5RampLevelStorStat 100;
BA_ "GenSigCycleTimeActive" SG_ 2566850827 Trailer5RampLevelStorStat 100;
BA_ "GenSigStartValue" SG_ 2566850827 Trailer5RampLevelStorStat 3;
BA_ "GenSigCycleTime" SG_ 2566850827 Trailer3LevelChangeFrontAxle 100;
BA_ "GenSigCycleTimeActive" SG_ 2566850827 Trailer3LevelChangeFrontAxle 100;
BA_ "GenSigStartValue" SG_ 2566850827 Trailer3LevelChangeFrontAxle 3;
BA_ "GenSigCycleTime" SG_ 2566850827 Trailer1StopLevelChangeAck 100;
BA_ "GenSigCycleTimeActive" SG_ 2566850827 Trailer1StopLevelChangeAck 100;
BA_ "GenSigStartValue" SG_ 2566850827 Trailer1StopLevelChangeAck 3;
BA_ "GenSigCycleTime" SG_ 2566850827 Trailer2LevelChangeFrontAxle 100;
BA_ "GenSigCycleTimeActive" SG_ 2566850827 Trailer2LevelChangeFrontAxle 100;
BA_ "GenSigStartValue" SG_ 2566850827 Trailer2LevelChangeFrontAxle 3;
BA_ "GenSigCycleTime" SG_ 2566850827 Trailer5TractionHelp 100;
BA_ "GenSigCycleTimeActive" SG_ 2566850827 Trailer5TractionHelp 100;
BA_ "GenSigStartValue" SG_ 2566850827 Trailer5TractionHelp 3;
BA_ "GenSigCycleTime" SG_ 2566850827 Trailer1LevelChangeFrontAxle 100;
BA_ "GenSigCycleTimeActive" SG_ 2566850827 Trailer1LevelChangeFrontAxle 100;
BA_ "GenSigStartValue" SG_ 2566850827 Trailer1LevelChangeFrontAxle 3;
BA_ "GenSigCycleTime" SG_ 2566850827 Trailer3RampLevelStorStat 100;
BA_ "GenSigCycleTimeActive" SG_ 2566850827 Trailer3RampLevelStorStat 100;
BA_ "GenSigStartValue" SG_ 2566850827 Trailer3RampLevelStorStat 3;
BA_ "GenSigCycleTime" SG_ 2566850827 Trailer1NormalLevelStorStat 100;
BA_ "GenSigCycleTimeActive" SG_ 2566850827 Trailer1NormalLevelStorStat 100;
BA_ "GenSigStartValue" SG_ 2566850827 Trailer1NormalLevelStorStat 3;
BA_ "GenSigCycleTime" SG_ 2566899211 Trailer5TowedVehStat_BrakeSystem 100;
BA_ "GenSigCycleTimeActive" SG_ 2566899211 Trailer5TowedVehStat_BrakeSystem 100;
BA_ "GenSigStartValue" SG_ 2566899211 Trailer5TowedVehStat_BrakeSystem 3;
BA_ "GenSigCycleTime" SG_ 2566899211 Trailer4TowedVehStat_DetectSupp 100;
BA_ "GenSigCycleTimeActive" SG_ 2566899211 Trailer4TowedVehStat_DetectSupp 100;
BA_ "GenSigStartValue" SG_ 2566899211 Trailer4TowedVehStat_DetectSupp 3;
BA_ "GenSigCycleTime" SG_ 2566899211 Trailer4TowedVehStat_CANAvail 100;
BA_ "GenSigCycleTimeActive" SG_ 2566899211 Trailer4TowedVehStat_CANAvail 100;
BA_ "GenSigStartValue" SG_ 2566899211 Trailer4TowedVehStat_CANAvail 3;
BA_ "GenSigCycleTime" SG_ 2566899211 Trailer3TowedVehStat_DetectStat 100;
BA_ "GenSigCycleTimeActive" SG_ 2566899211 Trailer3TowedVehStat_DetectStat 100;
BA_ "GenSigStartValue" SG_ 2566899211 Trailer3TowedVehStat_DetectStat 3;
BA_ "GenSigCycleTime" SG_ 2566899211 Trailer1TowedVehStat_DetectSupp 100;
BA_ "GenSigCycleTimeActive" SG_ 2566899211 Trailer1TowedVehStat_DetectSupp 100;
BA_ "GenSigStartValue" SG_ 2566899211 Trailer1TowedVehStat_DetectSupp 3;
BA_ "GenSigCycleTime" SG_ 2566899211 Trailer2TowedVehStat_CANAvail 100;
BA_ "GenSigCycleTimeActive" SG_ 2566899211 Trailer2TowedVehStat_CANAvail 100;
BA_ "GenSigStartValue" SG_ 2566899211 Trailer2TowedVehStat_CANAvail 3;
BA_ "GenSigCycleTime" SG_ 2566899211 Trailer1TowedVehStat_CANAvail 100;
BA_ "GenSigCycleTimeActive" SG_ 2566899211 Trailer1TowedVehStat_CANAvail 100;
BA_ "GenSigStartValue" SG_ 2566899211 Trailer1TowedVehStat_CANAvail 3;
BA_ "GenSigCycleTime" SG_ 2566899211 Trailer3TowedVehStat_DetectSupp 100;
BA_ "GenSigCycleTimeActive" SG_ 2566899211 Trailer3TowedVehStat_DetectSupp 100;
BA_ "GenSigStartValue" SG_ 2566899211 Trailer3TowedVehStat_DetectSupp 3;
BA_ "GenSigCycleTime" SG_ 2566899211 Trailer3TowedVehStat_CANAvail 100;
BA_ "GenSigCycleTimeActive" SG_ 2566899211 Trailer3TowedVehStat_CANAvail 100;
BA_ "GenSigStartValue" SG_ 2566899211 Trailer3TowedVehStat_CANAvail 3;
BA_ "GenSigCycleTime" SG_ 2566899211 Trailer1TowedVehStat_DetectStat 100;
BA_ "GenSigCycleTimeActive" SG_ 2566899211 Trailer1TowedVehStat_DetectStat 100;
BA_ "GenSigStartValue" SG_ 2566899211 Trailer1TowedVehStat_DetectStat 3;
BA_ "GenSigCycleTime" SG_ 2566899211 Trailer5TowedVehStat_DetectSupp 100;
BA_ "GenSigCycleTimeActive" SG_ 2566899211 Trailer5TowedVehStat_DetectSupp 100;
BA_ "GenSigStartValue" SG_ 2566899211 Trailer5TowedVehStat_DetectSupp 3;
BA_ "GenSigCycleTime" SG_ 2566899211 Trailer4TowedVehStat_DetectStat 100;
BA_ "GenSigCycleTimeActive" SG_ 2566899211 Trailer4TowedVehStat_DetectStat 100;
BA_ "GenSigStartValue" SG_ 2566899211 Trailer4TowedVehStat_DetectStat 3;
BA_ "GenSigCycleTime" SG_ 2566899211 Trailer4TowedVehStat_BrakeSystem 100;
BA_ "GenSigCycleTimeActive" SG_ 2566899211 Trailer4TowedVehStat_BrakeSystem 100;
BA_ "GenSigStartValue" SG_ 2566899211 Trailer4TowedVehStat_BrakeSystem 3;
BA_ "GenSigCycleTime" SG_ 2566899211 Trailer5TowedVehStat_DetectStat 100;
BA_ "GenSigCycleTimeActive" SG_ 2566899211 Trailer5TowedVehStat_DetectStat 100;
BA_ "GenSigStartValue" SG_ 2566899211 Trailer5TowedVehStat_DetectStat 3;
BA_ "GenSigCycleTime" SG_ 2566899211 Trailer3TowedVehStat_BrakeSystem 100;
BA_ "GenSigCycleTimeActive" SG_ 2566899211 Trailer3TowedVehStat_BrakeSystem 100;
BA_ "GenSigStartValue" SG_ 2566899211 Trailer3TowedVehStat_BrakeSystem 3;
BA_ "GenSigCycleTime" SG_ 2566899211 Trailer1TowedVehStat_BrakeSystem 100;
BA_ "GenSigCycleTimeActive" SG_ 2566899211 Trailer1TowedVehStat_BrakeSystem 100;
BA_ "GenSigStartValue" SG_ 2566899211 Trailer1TowedVehStat_BrakeSystem 3;
BA_ "GenSigCycleTime" SG_ 2566899211 Trailer5TowedVehStat_CANAvail 100;
BA_ "GenSigCycleTimeActive" SG_ 2566899211 Trailer5TowedVehStat_CANAvail 100;
BA_ "GenSigStartValue" SG_ 2566899211 Trailer5TowedVehStat_CANAvail 3;
BA_ "GenSigCycleTime" SG_ 2566899211 Trailer2TowedVehStat_DetectStat 100;
BA_ "GenSigCycleTimeActive" SG_ 2566899211 Trailer2TowedVehStat_DetectStat 100;
BA_ "GenSigStartValue" SG_ 2566899211 Trailer2TowedVehStat_DetectStat 3;
BA_ "GenSigCycleTime" SG_ 2566899211 Trailer2TowedVehStat_BrakeSystem 100;
BA_ "GenSigCycleTimeActive" SG_ 2566899211 Trailer2TowedVehStat_BrakeSystem 100;
BA_ "GenSigStartValue" SG_ 2566899211 Trailer2TowedVehStat_BrakeSystem 3;
BA_ "GenSigCycleTime" SG_ 2566899211 Trailer2TowedVehStat_DetectSupp 100;
BA_ "GenSigCycleTimeActive" SG_ 2566899211 Trailer2TowedVehStat_DetectSupp 100;
BA_ "GenSigStartValue" SG_ 2566899211 Trailer2TowedVehStat_DetectSupp 3;
BA_ "GenSigCycleTime" SG_ 2566898955 Trailer5CalibInfo_LoadRange 100;
BA_ "GenSigCycleTimeActive" SG_ 2566898955 Trailer5CalibInfo_LoadRange 100;
BA_ "GenSigStartValue" SG_ 2566898955 Trailer5CalibInfo_LoadRange 3;
BA_ "GenSigCycleTime" SG_ 2566898955 Trailer5CalibInfo_AxleId 100;
BA_ "GenSigCycleTimeActive" SG_ 2566898955 Trailer5CalibInfo_AxleId 100;
BA_ "GenSigStartValue" SG_ 2566898955 Trailer5CalibInfo_AxleId 255;
BA_ "GenSigCycleTime" SG_ 2566898955 Trailer5CalibInfo_Year 100;
BA_ "GenSigCycleTimeActive" SG_ 2566898955 Trailer5CalibInfo_Year 100;
BA_ "GenSigStartValue" SG_ 2566898955 Trailer5CalibInfo_Year 255;
BA_ "GenSigCycleTime" SG_ 2566898955 Trailer5CalibInfo_ScaleLoad 100;
BA_ "GenSigCycleTimeActive" SG_ 2566898955 Trailer5CalibInfo_ScaleLoad 100;
BA_ "GenSigStartValue" SG_ 2566898955 Trailer5CalibInfo_ScaleLoad 65535;
BA_ "GenSigCycleTime" SG_ 2566898955 Trailer5CalibInfo_CalibUsage 100;
BA_ "GenSigCycleTimeActive" SG_ 2566898955 Trailer5CalibInfo_CalibUsage 100;
BA_ "GenSigStartValue" SG_ 2566898955 Trailer5CalibInfo_CalibUsage 3;
BA_ "GenSigCycleTime" SG_ 2566898955 Trailer5CalibInfo_DataStorage 100;
BA_ "GenSigCycleTimeActive" SG_ 2566898955 Trailer5CalibInfo_DataStorage 100;
BA_ "GenSigStartValue" SG_ 2566898955 Trailer5CalibInfo_DataStorage 3;
BA_ "GenSigCycleTime" SG_ 2566898955 Trailer5CalibInfo_UncalibLoad 100;
BA_ "GenSigCycleTimeActive" SG_ 2566898955 Trailer5CalibInfo_UncalibLoad 100;
BA_ "GenSigStartValue" SG_ 2566898955 Trailer5CalibInfo_UncalibLoad 65535;
BA_ "GenSigCycleTime" SG_ 2566898955 Trailer5CalibInfo_Month 100;
BA_ "GenSigCycleTimeActive" SG_ 2566898955 Trailer5CalibInfo_Month 100;
BA_ "GenSigStartValue" SG_ 2566898955 Trailer5CalibInfo_Month 255;
BA_ "GenSigCycleTime" SG_ 2566898699 Trailer4CalibInfo_AxleId 100;
BA_ "GenSigCycleTimeActive" SG_ 2566898699 Trailer4CalibInfo_AxleId 100;
BA_ "GenSigStartValue" SG_ 2566898699 Trailer4CalibInfo_AxleId 255;
BA_ "GenSigCycleTime" SG_ 2566898699 Trailer4CalibInfo_LoadRange 100;
BA_ "GenSigCycleTimeActive" SG_ 2566898699 Trailer4CalibInfo_LoadRange 100;
BA_ "GenSigStartValue" SG_ 2566898699 Trailer4CalibInfo_LoadRange 3;
BA_ "GenSigCycleTime" SG_ 2566898699 Trailer4CalibInfo_CalibUsage 100;
BA_ "GenSigCycleTimeActive" SG_ 2566898699 Trailer4CalibInfo_CalibUsage 100;
BA_ "GenSigStartValue" SG_ 2566898699 Trailer4CalibInfo_CalibUsage 3;
BA_ "GenSigCycleTime" SG_ 2566898699 Trailer4CalibInfo_UncalibLoad 100;
BA_ "GenSigCycleTimeActive" SG_ 2566898699 Trailer4CalibInfo_UncalibLoad 100;
BA_ "GenSigStartValue" SG_ 2566898699 Trailer4CalibInfo_UncalibLoad 65535;
BA_ "GenSigCycleTime" SG_ 2566898699 Trailer4CalibInfo_DataStorage 100;
BA_ "GenSigCycleTimeActive" SG_ 2566898699 Trailer4CalibInfo_DataStorage 100;
BA_ "GenSigStartValue" SG_ 2566898699 Trailer4CalibInfo_DataStorage 3;
BA_ "GenSigCycleTime" SG_ 2566898699 Trailer4CalibInfo_ScaleLoad 100;
BA_ "GenSigCycleTimeActive" SG_ 2566898699 Trailer4CalibInfo_ScaleLoad 100;
BA_ "GenSigStartValue" SG_ 2566898699 Trailer4CalibInfo_ScaleLoad 65535;
BA_ "GenSigCycleTime" SG_ 2566898699 Trailer4CalibInfo_Year 100;
BA_ "GenSigCycleTimeActive" SG_ 2566898699 Trailer4CalibInfo_Year 100;
BA_ "GenSigStartValue" SG_ 2566898699 Trailer4CalibInfo_Year 255;
BA_ "GenSigCycleTime" SG_ 2566898699 Trailer4CalibInfo_Month 100;
BA_ "GenSigCycleTimeActive" SG_ 2566898699 Trailer4CalibInfo_Month 100;
BA_ "GenSigStartValue" SG_ 2566898699 Trailer4CalibInfo_Month 255;
BA_ "GenSigCycleTime" SG_ 2566898443 Trailer3CalibInfo_CalibUsage 100;
BA_ "GenSigCycleTimeActive" SG_ 2566898443 Trailer3CalibInfo_CalibUsage 100;
BA_ "GenSigStartValue" SG_ 2566898443 Trailer3CalibInfo_CalibUsage 3;
BA_ "GenSigCycleTime" SG_ 2566898443 Trailer3CalibInfo_LoadRange 100;
BA_ "GenSigCycleTimeActive" SG_ 2566898443 Trailer3CalibInfo_LoadRange 100;
BA_ "GenSigStartValue" SG_ 2566898443 Trailer3CalibInfo_LoadRange 3;
BA_ "GenSigCycleTime" SG_ 2566898443 Trailer3CalibInfo_Month 100;
BA_ "GenSigCycleTimeActive" SG_ 2566898443 Trailer3CalibInfo_Month 100;
BA_ "GenSigStartValue" SG_ 2566898443 Trailer3CalibInfo_Month 255;
BA_ "GenSigCycleTime" SG_ 2566898443 Trailer3CalibInfo_ScaleLoad 100;
BA_ "GenSigCycleTimeActive" SG_ 2566898443 Trailer3CalibInfo_ScaleLoad 100;
BA_ "GenSigStartValue" SG_ 2566898443 Trailer3CalibInfo_ScaleLoad 65535;
BA_ "GenSigCycleTime" SG_ 2566898443 Trailer3CalibInfo_UncalibLoad 100;
BA_ "GenSigCycleTimeActive" SG_ 2566898443 Trailer3CalibInfo_UncalibLoad 100;
BA_ "GenSigStartValue" SG_ 2566898443 Trailer3CalibInfo_UncalibLoad 65535;
BA_ "GenSigCycleTime" SG_ 2566898443 Trailer3CalibInfo_AxleId 100;
BA_ "GenSigCycleTimeActive" SG_ 2566898443 Trailer3CalibInfo_AxleId 100;
BA_ "GenSigStartValue" SG_ 2566898443 Trailer3CalibInfo_AxleId 255;
BA_ "GenSigCycleTime" SG_ 2566898443 Trailer3CalibInfo_Year 100;
BA_ "GenSigCycleTimeActive" SG_ 2566898443 Trailer3CalibInfo_Year 100;
BA_ "GenSigStartValue" SG_ 2566898443 Trailer3CalibInfo_Year 255;
BA_ "GenSigCycleTime" SG_ 2566898443 Trailer3CalibInfo_DataStorage 100;
BA_ "GenSigCycleTimeActive" SG_ 2566898443 Trailer3CalibInfo_DataStorage 100;
BA_ "GenSigStartValue" SG_ 2566898443 Trailer3CalibInfo_DataStorage 3;
BA_ "GenSigCycleTime" SG_ 2566898187 Trailer2CalibInfo_LoadRange 100;
BA_ "GenSigCycleTimeActive" SG_ 2566898187 Trailer2CalibInfo_LoadRange 100;
BA_ "GenSigStartValue" SG_ 2566898187 Trailer2CalibInfo_LoadRange 3;
BA_ "GenSigCycleTime" SG_ 2566898187 Trailer2CalibInfo_DataStorage 100;
BA_ "GenSigCycleTimeActive" SG_ 2566898187 Trailer2CalibInfo_DataStorage 100;
BA_ "GenSigStartValue" SG_ 2566898187 Trailer2CalibInfo_DataStorage 3;
BA_ "GenSigCycleTime" SG_ 2566898187 Trailer2CalibInfo_Year 100;
BA_ "GenSigCycleTimeActive" SG_ 2566898187 Trailer2CalibInfo_Year 100;
BA_ "GenSigStartValue" SG_ 2566898187 Trailer2CalibInfo_Year 255;
BA_ "GenSigCycleTime" SG_ 2566898187 Trailer2CalibInfo_AxleId 100;
BA_ "GenSigCycleTimeActive" SG_ 2566898187 Trailer2CalibInfo_AxleId 100;
BA_ "GenSigStartValue" SG_ 2566898187 Trailer2CalibInfo_AxleId 255;
BA_ "GenSigCycleTime" SG_ 2566898187 Trailer2CalibInfo_CalibUsage 100;
BA_ "GenSigCycleTimeActive" SG_ 2566898187 Trailer2CalibInfo_CalibUsage 100;
BA_ "GenSigStartValue" SG_ 2566898187 Trailer2CalibInfo_CalibUsage 3;
BA_ "GenSigCycleTime" SG_ 2566898187 Trailer2CalibInfo_Month 100;
BA_ "GenSigCycleTimeActive" SG_ 2566898187 Trailer2CalibInfo_Month 100;
BA_ "GenSigStartValue" SG_ 2566898187 Trailer2CalibInfo_Month 255;
BA_ "GenSigCycleTime" SG_ 2566898187 Trailer2CalibInfo_ScaleLoad 100;
BA_ "GenSigCycleTimeActive" SG_ 2566898187 Trailer2CalibInfo_ScaleLoad 100;
BA_ "GenSigStartValue" SG_ 2566898187 Trailer2CalibInfo_ScaleLoad 65535;
BA_ "GenSigCycleTime" SG_ 2566898187 Trailer2CalibInfo_UncalibLoad 100;
BA_ "GenSigCycleTimeActive" SG_ 2566898187 Trailer2CalibInfo_UncalibLoad 100;
BA_ "GenSigStartValue" SG_ 2566898187 Trailer2CalibInfo_UncalibLoad 65535;
BA_ "GenSigCycleTime" SG_ 2566897931 Trailer1CalibInfo_Year 100;
BA_ "GenSigCycleTimeActive" SG_ 2566897931 Trailer1CalibInfo_Year 100;
BA_ "GenSigStartValue" SG_ 2566897931 Trailer1CalibInfo_Year 255;
BA_ "GenSigCycleTime" SG_ 2566897931 Trailer1CalibInfo_LoadRange 100;
BA_ "GenSigCycleTimeActive" SG_ 2566897931 Trailer1CalibInfo_LoadRange 100;
BA_ "GenSigStartValue" SG_ 2566897931 Trailer1CalibInfo_LoadRange 3;
BA_ "GenSigCycleTime" SG_ 2566897931 Trailer1CalibInfo_AxleId 100;
BA_ "GenSigCycleTimeActive" SG_ 2566897931 Trailer1CalibInfo_AxleId 100;
BA_ "GenSigStartValue" SG_ 2566897931 Trailer1CalibInfo_AxleId 255;
BA_ "GenSigCycleTime" SG_ 2566897931 Trailer1CalibInfo_CalibUsage 100;
BA_ "GenSigCycleTimeActive" SG_ 2566897931 Trailer1CalibInfo_CalibUsage 100;
BA_ "GenSigStartValue" SG_ 2566897931 Trailer1CalibInfo_CalibUsage 3;
BA_ "GenSigCycleTime" SG_ 2566897931 Trailer1CalibInfo_UncalibLoad 100;
BA_ "GenSigCycleTimeActive" SG_ 2566897931 Trailer1CalibInfo_UncalibLoad 100;
BA_ "GenSigStartValue" SG_ 2566897931 Trailer1CalibInfo_UncalibLoad 65535;
BA_ "GenSigCycleTime" SG_ 2566897931 Trailer1CalibInfo_Month 100;
BA_ "GenSigCycleTimeActive" SG_ 2566897931 Trailer1CalibInfo_Month 100;
BA_ "GenSigStartValue" SG_ 2566897931 Trailer1CalibInfo_Month 255;
BA_ "GenSigCycleTime" SG_ 2566897931 Trailer1CalibInfo_DataStorage 100;
BA_ "GenSigCycleTimeActive" SG_ 2566897931 Trailer1CalibInfo_DataStorage 100;
BA_ "GenSigStartValue" SG_ 2566897931 Trailer1CalibInfo_DataStorage 3;
BA_ "GenSigCycleTime" SG_ 2566897931 Trailer1CalibInfo_ScaleLoad 100;
BA_ "GenSigCycleTimeActive" SG_ 2566897931 Trailer1CalibInfo_ScaleLoad 100;
BA_ "GenSigStartValue" SG_ 2566897931 Trailer1CalibInfo_ScaleLoad 65535;
BA_ "GenSigCycleTime" SG_ 2566878475 Trailer5BrkLining_Wear 100;
BA_ "GenSigCycleTimeActive" SG_ 2566878475 Trailer5BrkLining_Wear 100;
BA_ "GenSigStartValue" SG_ 2566878475 Trailer5BrkLining_Wear 255;
BA_ "GenSigCycleTime" SG_ 2566878475 Trailer5BrkLining_BrkLnTireId 100;
BA_ "GenSigCycleTimeActive" SG_ 2566878475 Trailer5BrkLining_BrkLnTireId 100;
BA_ "GenSigStartValue" SG_ 2566878475 Trailer5BrkLining_BrkLnTireId 255;
BA_ "GenSigCycleTime" SG_ 2566878475 Trailer5NormalLevel_LvlPos 100;
BA_ "GenSigCycleTimeActive" SG_ 2566878475 Trailer5NormalLevel_LvlPos 100;
BA_ "GenSigStartValue" SG_ 2566878475 Trailer5NormalLevel_LvlPos 3;
BA_ "GenSigCycleTime" SG_ 2566878475 Trailer5NormalLevel_LvlStatus 100;
BA_ "GenSigCycleTimeActive" SG_ 2566878475 Trailer5NormalLevel_LvlStatus 100;
BA_ "GenSigStartValue" SG_ 2566878475 Trailer5NormalLevel_LvlStatus 3;
BA_ "GenSigCycleTime" SG_ 2566878475 Trailer5RampLevel_LvlStatus 100;
BA_ "GenSigCycleTimeActive" SG_ 2566878475 Trailer5RampLevel_LvlStatus 100;
BA_ "GenSigStartValue" SG_ 2566878475 Trailer5RampLevel_LvlStatus 3;
BA_ "GenSigCycleTime" SG_ 2566878475 Trailer5BrkLining_Warning 100;
BA_ "GenSigCycleTimeActive" SG_ 2566878475 Trailer5BrkLining_Warning 100;
BA_ "GenSigStartValue" SG_ 2566878475 Trailer5BrkLining_Warning 3;
BA_ "GenSigCycleTime" SG_ 2566878475 Trailer5RelBodyLevel_RearLevel 100;
BA_ "GenSigCycleTimeActive" SG_ 2566878475 Trailer5RelBodyLevel_RearLevel 100;
BA_ "GenSigStartValue" SG_ 2566878475 Trailer5RelBodyLevel_RearLevel 65535;
BA_ "GenSigCycleTime" SG_ 2566878475 Trailer5RelBodyLevel_FrontLevel 100;
BA_ "GenSigCycleTimeActive" SG_ 2566878475 Trailer5RelBodyLevel_FrontLevel 100;
BA_ "GenSigStartValue" SG_ 2566878475 Trailer5RelBodyLevel_FrontLevel 65535;
BA_ "GenSigCycleTime" SG_ 2566878475 Trailer5RampLevel_LvlPos 100;
BA_ "GenSigCycleTimeActive" SG_ 2566878475 Trailer5RampLevel_LvlPos 100;
BA_ "GenSigStartValue" SG_ 2566878475 Trailer5RampLevel_LvlPos 3;
BA_ "GenSigCycleTime" SG_ 2566878219 Trailer4RampLevel_LvlStatus 100;
BA_ "GenSigCycleTimeActive" SG_ 2566878219 Trailer4RampLevel_LvlStatus 100;
BA_ "GenSigStartValue" SG_ 2566878219 Trailer4RampLevel_LvlStatus 3;
BA_ "GenSigCycleTime" SG_ 2566878219 Trailer4BrkLining_BrkLnTireId 100;
BA_ "GenSigCycleTimeActive" SG_ 2566878219 Trailer4BrkLining_BrkLnTireId 100;
BA_ "GenSigStartValue" SG_ 2566878219 Trailer4BrkLining_BrkLnTireId 255;
BA_ "GenSigCycleTime" SG_ 2566878219 Trailer4BrkLining_Wear 100;
BA_ "GenSigCycleTimeActive" SG_ 2566878219 Trailer4BrkLining_Wear 100;
BA_ "GenSigStartValue" SG_ 2566878219 Trailer4BrkLining_Wear 255;
BA_ "GenSigCycleTime" SG_ 2566878219 Trailer4NormalLevel_LvlStatus 100;
BA_ "GenSigCycleTimeActive" SG_ 2566878219 Trailer4NormalLevel_LvlStatus 100;
BA_ "GenSigStartValue" SG_ 2566878219 Trailer4NormalLevel_LvlStatus 3;
BA_ "GenSigCycleTime" SG_ 2566878219 Trailer4RelBodyLevel_FrontLevel 100;
BA_ "GenSigCycleTimeActive" SG_ 2566878219 Trailer4RelBodyLevel_FrontLevel 100;
BA_ "GenSigStartValue" SG_ 2566878219 Trailer4RelBodyLevel_FrontLevel 65535;
BA_ "GenSigMaxLatency" SG_ 2566878219 Trailer4RelBodyLevel_FrontLevel 140;
BA_ "Platform_VMCU1_Sig" SG_ 2566878219 Trailer4RelBodyLevel_FrontLevel 1;
BA_ "GenSigCycleTime" SG_ 2566878219 Trailer4BrkLining_Warning 100;
BA_ "GenSigCycleTimeActive" SG_ 2566878219 Trailer4BrkLining_Warning 100;
BA_ "GenSigStartValue" SG_ 2566878219 Trailer4BrkLining_Warning 3;
BA_ "GenSigCycleTime" SG_ 2566878219 Trailer4NormalLevel_LvlPos 100;
BA_ "GenSigCycleTimeActive" SG_ 2566878219 Trailer4NormalLevel_LvlPos 100;
BA_ "GenSigStartValue" SG_ 2566878219 Trailer4NormalLevel_LvlPos 3;
BA_ "GenSigCycleTime" SG_ 2566878219 Trailer4RampLevel_LvlPos 100;
BA_ "GenSigCycleTimeActive" SG_ 2566878219 Trailer4RampLevel_LvlPos 100;
BA_ "GenSigStartValue" SG_ 2566878219 Trailer4RampLevel_LvlPos 3;
BA_ "GenSigCycleTime" SG_ 2566878219 Trailer4RelBodyLevel_RearLevel 100;
BA_ "GenSigCycleTimeActive" SG_ 2566878219 Trailer4RelBodyLevel_RearLevel 100;
BA_ "GenSigStartValue" SG_ 2566878219 Trailer4RelBodyLevel_RearLevel 65535;
BA_ "GenSigMaxLatency" SG_ 2566878219 Trailer4RelBodyLevel_RearLevel 140;
BA_ "Platform_VMCU1_Sig" SG_ 2566878219 Trailer4RelBodyLevel_RearLevel 1;
BA_ "GenSigCycleTime" SG_ 2566877963 Trailer3RampLevel_LvlStatus 100;
BA_ "GenSigCycleTimeActive" SG_ 2566877963 Trailer3RampLevel_LvlStatus 100;
BA_ "GenSigStartValue" SG_ 2566877963 Trailer3RampLevel_LvlStatus 3;
BA_ "GenSigCycleTime" SG_ 2566877963 Trailer3RampLevel_LvlPos 100;
BA_ "GenSigCycleTimeActive" SG_ 2566877963 Trailer3RampLevel_LvlPos 100;
BA_ "GenSigStartValue" SG_ 2566877963 Trailer3RampLevel_LvlPos 3;
BA_ "GenSigCycleTime" SG_ 2566877963 Trailer3NormalLevel_LvlPos 100;
BA_ "GenSigCycleTimeActive" SG_ 2566877963 Trailer3NormalLevel_LvlPos 100;
BA_ "GenSigStartValue" SG_ 2566877963 Trailer3NormalLevel_LvlPos 3;
BA_ "GenSigCycleTime" SG_ 2566877963 Trailer3BrkLining_BrkLnTireId 100;
BA_ "GenSigCycleTimeActive" SG_ 2566877963 Trailer3BrkLining_BrkLnTireId 100;
BA_ "GenSigStartValue" SG_ 2566877963 Trailer3BrkLining_BrkLnTireId 255;
BA_ "GenSigCycleTime" SG_ 2566877963 Trailer3BrkLining_Wear 100;
BA_ "GenSigCycleTimeActive" SG_ 2566877963 Trailer3BrkLining_Wear 100;
BA_ "GenSigStartValue" SG_ 2566877963 Trailer3BrkLining_Wear 255;
BA_ "GenSigCycleTime" SG_ 2566877963 Trailer3RelBodyLevel_RearLevel 100;
BA_ "GenSigCycleTimeActive" SG_ 2566877963 Trailer3RelBodyLevel_RearLevel 100;
BA_ "GenSigStartValue" SG_ 2566877963 Trailer3RelBodyLevel_RearLevel 65535;
BA_ "GenSigCycleTime" SG_ 2566877963 Trailer3NormalLevel_LvlStatus 100;
BA_ "GenSigCycleTimeActive" SG_ 2566877963 Trailer3NormalLevel_LvlStatus 100;
BA_ "GenSigStartValue" SG_ 2566877963 Trailer3NormalLevel_LvlStatus 3;
BA_ "GenSigCycleTime" SG_ 2566877963 Trailer3BrkLining_Warning 100;
BA_ "GenSigCycleTimeActive" SG_ 2566877963 Trailer3BrkLining_Warning 100;
BA_ "GenSigStartValue" SG_ 2566877963 Trailer3BrkLining_Warning 3;
BA_ "GenSigCycleTime" SG_ 2566877963 Trailer3RelBodyLevel_FrontLevel 100;
BA_ "GenSigCycleTimeActive" SG_ 2566877963 Trailer3RelBodyLevel_FrontLevel 100;
BA_ "GenSigStartValue" SG_ 2566877963 Trailer3RelBodyLevel_FrontLevel 65535;
BA_ "GenSigCycleTime" SG_ 2566877707 Trailer2BrkLining_Warning 100;
BA_ "GenSigCycleTimeActive" SG_ 2566877707 Trailer2BrkLining_Warning 100;
BA_ "GenSigStartValue" SG_ 2566877707 Trailer2BrkLining_Warning 3;
BA_ "GenSigCycleTime" SG_ 2566877707 Trailer2RampLevel_LvlPos 100;
BA_ "GenSigCycleTimeActive" SG_ 2566877707 Trailer2RampLevel_LvlPos 100;
BA_ "GenSigStartValue" SG_ 2566877707 Trailer2RampLevel_LvlPos 3;
BA_ "GenSigCycleTime" SG_ 2566877707 Trailer2BrkLining_Wear 100;
BA_ "GenSigCycleTimeActive" SG_ 2566877707 Trailer2BrkLining_Wear 100;
BA_ "GenSigStartValue" SG_ 2566877707 Trailer2BrkLining_Wear 255;
BA_ "GenSigCycleTime" SG_ 2566877707 Trailer2BrkLining_BrkLnTireId 100;
BA_ "GenSigCycleTimeActive" SG_ 2566877707 Trailer2BrkLining_BrkLnTireId 100;
BA_ "GenSigStartValue" SG_ 2566877707 Trailer2BrkLining_BrkLnTireId 255;
BA_ "GenSigCycleTime" SG_ 2566877707 Trailer2RampLevel_LvlStatus 100;
BA_ "GenSigCycleTimeActive" SG_ 2566877707 Trailer2RampLevel_LvlStatus 100;
BA_ "GenSigStartValue" SG_ 2566877707 Trailer2RampLevel_LvlStatus 3;
BA_ "GenSigCycleTime" SG_ 2566877707 Trailer2RelBodyLevel_RearLevel 100;
BA_ "GenSigCycleTimeActive" SG_ 2566877707 Trailer2RelBodyLevel_RearLevel 100;
BA_ "GenSigStartValue" SG_ 2566877707 Trailer2RelBodyLevel_RearLevel 65535;
BA_ "GenSigCycleTime" SG_ 2566877707 Trailer2NormalLevel_LvlPos 100;
BA_ "GenSigCycleTimeActive" SG_ 2566877707 Trailer2NormalLevel_LvlPos 100;
BA_ "GenSigStartValue" SG_ 2566877707 Trailer2NormalLevel_LvlPos 3;
BA_ "GenSigCycleTime" SG_ 2566877707 Trailer2RelBodyLevel_FrontLevel 100;
BA_ "GenSigCycleTimeActive" SG_ 2566877707 Trailer2RelBodyLevel_FrontLevel 100;
BA_ "GenSigStartValue" SG_ 2566877707 Trailer2RelBodyLevel_FrontLevel 65535;
BA_ "GenSigCycleTime" SG_ 2566877707 Trailer2NormalLevel_LvlStatus 100;
BA_ "GenSigCycleTimeActive" SG_ 2566877707 Trailer2NormalLevel_LvlStatus 100;
BA_ "GenSigStartValue" SG_ 2566877707 Trailer2NormalLevel_LvlStatus 3;
BA_ "GenSigCycleTime" SG_ 2566877451 Trailer1RelBodyLevel_FrontLevel 100;
BA_ "GenSigCycleTimeActive" SG_ 2566877451 Trailer1RelBodyLevel_FrontLevel 100;
BA_ "GenSigStartValue" SG_ 2566877451 Trailer1RelBodyLevel_FrontLevel 65535;
BA_ "GenSigCycleTime" SG_ 2566877451 Trailer1BrkLining_BrkLnTireId 100;
BA_ "GenSigCycleTimeActive" SG_ 2566877451 Trailer1BrkLining_BrkLnTireId 100;
BA_ "GenSigStartValue" SG_ 2566877451 Trailer1BrkLining_BrkLnTireId 255;
BA_ "GenSigCycleTime" SG_ 2566877451 Trailer1BrkLining_Wear 100;
BA_ "GenSigCycleTimeActive" SG_ 2566877451 Trailer1BrkLining_Wear 100;
BA_ "GenSigStartValue" SG_ 2566877451 Trailer1BrkLining_Wear 255;
BA_ "GenSigCycleTime" SG_ 2566877451 Trailer1NormalLevel_LvlPos 100;
BA_ "GenSigCycleTimeActive" SG_ 2566877451 Trailer1NormalLevel_LvlPos 100;
BA_ "GenSigStartValue" SG_ 2566877451 Trailer1NormalLevel_LvlPos 3;
BA_ "GenSigCycleTime" SG_ 2566877451 Trailer1BrkLining_Warning 100;
BA_ "GenSigCycleTimeActive" SG_ 2566877451 Trailer1BrkLining_Warning 100;
BA_ "GenSigStartValue" SG_ 2566877451 Trailer1BrkLining_Warning 3;
BA_ "GenSigCycleTime" SG_ 2566877451 Trailer1RampLevel_LvlPos 100;
BA_ "GenSigCycleTimeActive" SG_ 2566877451 Trailer1RampLevel_LvlPos 100;
BA_ "GenSigStartValue" SG_ 2566877451 Trailer1RampLevel_LvlPos 3;
BA_ "GenSigCycleTime" SG_ 2566877451 Trailer1NormalLevel_LvlStatus 100;
BA_ "GenSigCycleTimeActive" SG_ 2566877451 Trailer1NormalLevel_LvlStatus 100;
BA_ "GenSigStartValue" SG_ 2566877451 Trailer1NormalLevel_LvlStatus 3;
BA_ "GenSigCycleTime" SG_ 2566877451 Trailer1RampLevel_LvlStatus 100;
BA_ "GenSigCycleTimeActive" SG_ 2566877451 Trailer1RampLevel_LvlStatus 100;
BA_ "GenSigStartValue" SG_ 2566877451 Trailer1RampLevel_LvlStatus 3;
BA_ "GenSigCycleTime" SG_ 2566877451 Trailer1RelBodyLevel_RearLevel 100;
BA_ "GenSigCycleTimeActive" SG_ 2566877451 Trailer1RelBodyLevel_RearLevel 100;
BA_ "GenSigStartValue" SG_ 2566877451 Trailer1RelBodyLevel_RearLevel 65535;
BA_ "GenSigCycleTime" SG_ 2566894859 Trailer5VIN 100;
BA_ "GenSigCycleTimeActive" SG_ 2566894859 Trailer5VIN 100;
BA_ "GenSigCycleTime" SG_ 2566894603 Trailer4VIN 100;
BA_ "GenSigCycleTimeActive" SG_ 2566894603 Trailer4VIN 100;
BA_ "GenSigCycleTime" SG_ 2566894347 Trailer3VIN 100;
BA_ "GenSigCycleTimeActive" SG_ 2566894347 Trailer3VIN 100;
BA_ "GenSigCycleTime" SG_ 2566894091 Trailer2VIN 100;
BA_ "GenSigCycleTimeActive" SG_ 2566894091 Trailer2VIN 100;
BA_ "GenSigCycleTime" SG_ 2566893835 Trailer1VIN 100;
BA_ "GenSigCycleTimeActive" SG_ 2566893835 Trailer1VIN 100;
BA_REL_ "GenSigFirstTimeoutTime" BU_SG_REL_ VCM SG_ 2566897419 Trailer2LevelControlStatus 24000;
BA_REL_ "GenSigTimeoutTime" BU_SG_REL_ VCM SG_ 2566897419 Trailer2LevelControlStatus 6000;
BA_REL_ "GenSigFirstTimeoutTime" BU_SG_REL_ VCM SG_ 2566897419 Trailer2VehicleType 24000;
BA_REL_ "GenSigTimeoutTime" BU_SG_REL_ VCM SG_ 2566897419 Trailer2VehicleType 6000;
BA_REL_ "GenSigFirstTimeoutTime" BU_SG_REL_ VCM SG_ 2566897419 Trailer2EBSAmberWarning 24000;
BA_REL_ "GenSigTimeoutTime" BU_SG_REL_ VCM SG_ 2566897419 Trailer2EBSAmberWarning 6000;
BA_REL_ "GenSigFirstTimeoutTime" BU_SG_REL_ VCM SG_ 2566897419 Trailer2EBSRedWarning 24000;
BA_REL_ "GenSigTimeoutTime" BU_SG_REL_ VCM SG_ 2566897419 Trailer2EBSRedWarning 6000;
BA_REL_ "GenSigFirstTimeoutTime" BU_SG_REL_ VCM SG_ 2566897419 Trailer2NomBodyLevel_RearLevel 24000;
BA_REL_ "GenSigTimeoutTime" BU_SG_REL_ VCM SG_ 2566897419 Trailer2NomBodyLevel_RearLevel 6000;
BA_REL_ "GenSigFirstTimeoutTime" BU_SG_REL_ VCM SG_ 2566897419 Trailer2PneumSupply_Pressure 24000;
BA_REL_ "GenSigTimeoutTime" BU_SG_REL_ VCM SG_ 2566897419 Trailer2PneumSupply_Pressure 6000;
BA_REL_ "GenSigFirstTimeoutTime" BU_SG_REL_ VCM SG_ 2566897419 Trailer2LoadRampApprAssistStat 24000;
BA_REL_ "GenSigTimeoutTime" BU_SG_REL_ VCM SG_ 2566897419 Trailer2LoadRampApprAssistStat 6000;
BA_REL_ "GenSigFirstTimeoutTime" BU_SG_REL_ VCM SG_ 2566897419 Trailer2PneumSupply_Status 24000;
BA_REL_ "GenSigTimeoutTime" BU_SG_REL_ VCM SG_ 2566897419 Trailer2PneumSupply_Status 6000;
BA_REL_ "GenSigFirstTimeoutTime" BU_SG_REL_ VCM SG_ 2566897419 Trailer2NomBodyLevel_FrontLevel 24000;
BA_REL_ "GenSigTimeoutTime" BU_SG_REL_ VCM SG_ 2566897419 Trailer2NomBodyLevel_FrontLevel 6000;
BA_REL_ "GenSigFirstTimeoutTime" BU_SG_REL_ VCM SG_ 2566897419 Trailer2YCSystemStatus 24000;
BA_REL_ "GenSigTimeoutTime" BU_SG_REL_ VCM SG_ 2566897419 Trailer2YCSystemStatus 6000;
BA_REL_ "GenSigFirstTimeoutTime" BU_SG_REL_ VCM SG_ 2566897419 Trailer2ElectricalSupplyStat 24000;
BA_REL_ "GenSigTimeoutTime" BU_SG_REL_ VCM SG_ 2566897419 Trailer2ElectricalSupplyStat 6000;
BA_REL_ "GenSigFirstTimeoutTime" BU_SG_REL_ VCM SG_ 2566897419 Trailer2ROPSystemStatus 24000;
BA_REL_ "GenSigTimeoutTime" BU_SG_REL_ VCM SG_ 2566897419 Trailer2ROPSystemStatus 6000;
BA_REL_ "GenSigFirstTimeoutTime" BU_SG_REL_ VCM SG_ 2566897419 Trailer2ExtLvlStorageSupport 24000;
BA_REL_ "GenSigTimeoutTime" BU_SG_REL_ VCM SG_ 2566897419 Trailer2ExtLvlStorageSupport 6000;
BA_REL_ "GenSigFirstTimeoutTime" BU_SG_REL_ VCM SG_ 2566892811 Trailer1NomBodyLevel_RearLevel 24000;
BA_REL_ "GenSigTimeoutTime" BU_SG_REL_ VCM SG_ 2566892811 Trailer1NomBodyLevel_RearLevel 6000;
BA_REL_ "GenSigFirstTimeoutTime" BU_SG_REL_ VCM SG_ 2566892811 Trailer1EBSRedWarning 24000;
BA_REL_ "GenSigTimeoutTime" BU_SG_REL_ VCM SG_ 2566892811 Trailer1EBSRedWarning 6000;
BA_REL_ "GenSigFirstTimeoutTime" BU_SG_REL_ VCM SG_ 2566892811 Trailer1VehicleType 24000;
BA_REL_ "GenSigTimeoutTime" BU_SG_REL_ VCM SG_ 2566892811 Trailer1VehicleType 6000;
BA_REL_ "GenSigFirstTimeoutTime" BU_SG_REL_ VCM SG_ 2566892811 Trailer1LoadRampApprAssistStat 24000;
BA_REL_ "GenSigTimeoutTime" BU_SG_REL_ VCM SG_ 2566892811 Trailer1LoadRampApprAssistStat 6000;
BA_REL_ "GenSigFirstTimeoutTime" BU_SG_REL_ VCM SG_ 2566892811 Trailer1YCSystemStatus 24000;
BA_REL_ "GenSigTimeoutTime" BU_SG_REL_ VCM SG_ 2566892811 Trailer1YCSystemStatus 6000;
BA_REL_ "GenSigFirstTimeoutTime" BU_SG_REL_ VCM SG_ 2566892811 Trailer1EBSAmberWarning 24000;
BA_REL_ "GenSigTimeoutTime" BU_SG_REL_ VCM SG_ 2566892811 Trailer1EBSAmberWarning 6000;
BA_REL_ "GenSigFirstTimeoutTime" BU_SG_REL_ VCM SG_ 2566892811 Trailer1PneumSupply_Pressure 24000;
BA_REL_ "GenSigTimeoutTime" BU_SG_REL_ VCM SG_ 2566892811 Trailer1PneumSupply_Pressure 6000;
BA_REL_ "GenSigFirstTimeoutTime" BU_SG_REL_ VCM SG_ 2566892811 Trailer1ElectricalSupplyStat 24000;
BA_REL_ "GenSigTimeoutTime" BU_SG_REL_ VCM SG_ 2566892811 Trailer1ElectricalSupplyStat 6000;
BA_REL_ "GenSigFirstTimeoutTime" BU_SG_REL_ VCM SG_ 2566892811 Trailer1ROPSystemStatus 24000;
BA_REL_ "GenSigTimeoutTime" BU_SG_REL_ VCM SG_ 2566892811 Trailer1ROPSystemStatus 6000;
BA_REL_ "GenSigFirstTimeoutTime" BU_SG_REL_ VCM SG_ 2566892811 Trailer1NomBodyLevel_FrontLevel 24000;
BA_REL_ "GenSigTimeoutTime" BU_SG_REL_ VCM SG_ 2566892811 Trailer1NomBodyLevel_FrontLevel 6000;
BA_REL_ "GenSigFirstTimeoutTime" BU_SG_REL_ VCM SG_ 2566892811 Trailer1PneumSupply_Status 24000;
BA_REL_ "GenSigTimeoutTime" BU_SG_REL_ VCM SG_ 2566892811 Trailer1PneumSupply_Status 6000;
BA_REL_ "GenSigFirstTimeoutTime" BU_SG_REL_ VCM SG_ 2566892811 Trailer1ExtLvlStorageSupport 24000;
BA_REL_ "GenSigTimeoutTime" BU_SG_REL_ VCM SG_ 2566892811 Trailer1ExtLvlStorageSupport 6000;
BA_REL_ "GenSigFirstTimeoutTime" BU_SG_REL_ VCM SG_ 2566892811 Trailer1LevelControlStatus 24000;
BA_REL_ "GenSigTimeoutTime" BU_SG_REL_ VCM SG_ 2566892811 Trailer1LevelControlStatus 6000;
BA_REL_ "GenSigFirstTimeoutTime" BU_SG_REL_ VCM SG_ 2566887947 Trailer5TireInfoISO_Leakage_ISig 24000;
BA_REL_ "GenSigTimeoutTime" BU_SG_REL_ VCM SG_ 2566887947 Trailer5TireInfoISO_Leakage_ISig 6000;
BA_REL_ "GenSigFirstTimeoutTime" BU_SG_REL_ VCM SG_ 2566887947 Trailer5TireInfoISO_sg_UB_ISig_1 24000;
BA_REL_ "GenSigTimeoutTime" BU_SG_REL_ VCM SG_ 2566887947 Trailer5TireInfoISO_sg_UB_ISig_1 6000;
BA_REL_ "GenSigFirstTimeoutTime" BU_SG_REL_ VCM SG_ 2566887947 Trailer5TireInfoISO_PowerSupply_ 24000;
BA_REL_ "GenSigTimeoutTime" BU_SG_REL_ VCM SG_ 2566887947 Trailer5TireInfoISO_PowerSupply_ 6000;
BA_REL_ "GenSigFirstTimeoutTime" BU_SG_REL_ VCM SG_ 2566887947 Trailer5TireInfoISO_TireId_ISig_ 24000;
BA_REL_ "GenSigTimeoutTime" BU_SG_REL_ VCM SG_ 2566887947 Trailer5TireInfoISO_TireId_ISig_ 6000;
BA_REL_ "GenSigFirstTimeoutTime" BU_SG_REL_ VCM SG_ 2566887947 Trailer5TireInfoISO_Pressure_ISi 24000;
BA_REL_ "GenSigTimeoutTime" BU_SG_REL_ VCM SG_ 2566887947 Trailer5TireInfoISO_Pressure_ISi 6000;
BA_REL_ "GenSigFirstTimeoutTime" BU_SG_REL_ VCM SG_ 2566887947 Trailer5TireInfoISO_Temperature_ 24000;
BA_REL_ "GenSigTimeoutTime" BU_SG_REL_ VCM SG_ 2566887947 Trailer5TireInfoISO_Temperature_ 6000;
BA_REL_ "GenSigFirstTimeoutTime" BU_SG_REL_ VCM SG_ 2566887947 Trailer5TireInfoISO_PresSuff_ISi 24000;
BA_REL_ "GenSigTimeoutTime" BU_SG_REL_ VCM SG_ 2566887947 Trailer5TireInfoISO_PresSuff_ISi 6000;
BA_REL_ "GenSigFirstTimeoutTime" BU_SG_REL_ VCM SG_ 2566887947 Trailer5TireInfoISO_Warning_ISig 24000;
BA_REL_ "GenSigTimeoutTime" BU_SG_REL_ VCM SG_ 2566887947 Trailer5TireInfoISO_Warning_ISig 6000;
BA_REL_ "GenSigFirstTimeoutTime" BU_SG_REL_ VCM SG_ 2566887947 Trailer5TireInfoISO_Active_ISig_ 24000;
BA_REL_ "GenSigTimeoutTime" BU_SG_REL_ VCM SG_ 2566887947 Trailer5TireInfoISO_Active_ISig_ 6000;
BA_REL_ "GenSigFirstTimeoutTime" BU_SG_REL_ VCM SG_ 2566883339 Trailer4TireInfoISO_Temperature_ 24000;
BA_REL_ "GenSigTimeoutTime" BU_SG_REL_ VCM SG_ 2566883339 Trailer4TireInfoISO_Temperature_ 6000;
BA_REL_ "GenSigFirstTimeoutTime" BU_SG_REL_ VCM SG_ 2566883339 Trailer4TireInfoISO_TireId_ISig_ 24000;
BA_REL_ "GenSigTimeoutTime" BU_SG_REL_ VCM SG_ 2566883339 Trailer4TireInfoISO_TireId_ISig_ 6000;
BA_REL_ "GenSigFirstTimeoutTime" BU_SG_REL_ VCM SG_ 2566883339 Trailer4TireInfoISO_PowerSupply_ 24000;
BA_REL_ "GenSigTimeoutTime" BU_SG_REL_ VCM SG_ 2566883339 Trailer4TireInfoISO_PowerSupply_ 6000;
BA_REL_ "GenSigFirstTimeoutTime" BU_SG_REL_ VCM SG_ 2566883339 Trailer4TireInfoISO_Warning_ISig 24000;
BA_REL_ "GenSigTimeoutTime" BU_SG_REL_ VCM SG_ 2566883339 Trailer4TireInfoISO_Warning_ISig 6000;
BA_REL_ "GenSigFirstTimeoutTime" BU_SG_REL_ VCM SG_ 2566883339 Trailer4TireInfoISO_Pressure_ISi 24000;
BA_REL_ "GenSigTimeoutTime" BU_SG_REL_ VCM SG_ 2566883339 Trailer4TireInfoISO_Pressure_ISi 6000;
BA_REL_ "GenSigFirstTimeoutTime" BU_SG_REL_ VCM SG_ 2566883339 Trailer4TireInfoISO_Leakage_ISig 24000;
BA_REL_ "GenSigTimeoutTime" BU_SG_REL_ VCM SG_ 2566883339 Trailer4TireInfoISO_Leakage_ISig 6000;
BA_REL_ "GenSigFirstTimeoutTime" BU_SG_REL_ VCM SG_ 2566883339 Trailer4TireInfoISO_Active_ISig_ 24000;
BA_REL_ "GenSigTimeoutTime" BU_SG_REL_ VCM SG_ 2566883339 Trailer4TireInfoISO_Active_ISig_ 6000;
BA_REL_ "GenSigFirstTimeoutTime" BU_SG_REL_ VCM SG_ 2566883339 Trailer4TireInfoISO_PresSuff_ISi 24000;
BA_REL_ "GenSigTimeoutTime" BU_SG_REL_ VCM SG_ 2566883339 Trailer4TireInfoISO_PresSuff_ISi 6000;
BA_REL_ "GenSigFirstTimeoutTime" BU_SG_REL_ VCM SG_ 2566883339 Trailer4TireInfoISO_sg_UB_ISig_1 24000;
BA_REL_ "GenSigTimeoutTime" BU_SG_REL_ VCM SG_ 2566883339 Trailer4TireInfoISO_sg_UB_ISig_1 6000;
BA_REL_ "GenSigFirstTimeoutTime" BU_SG_REL_ VCM SG_ 2566878731 Trailer3TireInfoISO_Pressure_ISi 24000;
BA_REL_ "GenSigTimeoutTime" BU_SG_REL_ VCM SG_ 2566878731 Trailer3TireInfoISO_Pressure_ISi 6000;
BA_REL_ "GenSigFirstTimeoutTime" BU_SG_REL_ VCM SG_ 2566878731 Trailer3TireInfoISO_sg_UB_ISig_1 24000;
BA_REL_ "GenSigTimeoutTime" BU_SG_REL_ VCM SG_ 2566878731 Trailer3TireInfoISO_sg_UB_ISig_1 6000;
BA_REL_ "GenSigFirstTimeoutTime" BU_SG_REL_ VCM SG_ 2566878731 Trailer3TireInfoISO_PowerSupply_ 24000;
BA_REL_ "GenSigTimeoutTime" BU_SG_REL_ VCM SG_ 2566878731 Trailer3TireInfoISO_PowerSupply_ 6000;
BA_REL_ "GenSigFirstTimeoutTime" BU_SG_REL_ VCM SG_ 2566878731 Trailer3TireInfoISO_PresSuff_ISi 24000;
BA_REL_ "GenSigTimeoutTime" BU_SG_REL_ VCM SG_ 2566878731 Trailer3TireInfoISO_PresSuff_ISi 6000;
BA_REL_ "GenSigFirstTimeoutTime" BU_SG_REL_ VCM SG_ 2566878731 Trailer3TireInfoISO_Temperature_ 24000;
BA_REL_ "GenSigTimeoutTime" BU_SG_REL_ VCM SG_ 2566878731 Trailer3TireInfoISO_Temperature_ 6000;
BA_REL_ "GenSigFirstTimeoutTime" BU_SG_REL_ VCM SG_ 2566878731 Trailer3TireInfoISO_TireId_ISig_ 24000;
BA_REL_ "GenSigTimeoutTime" BU_SG_REL_ VCM SG_ 2566878731 Trailer3TireInfoISO_TireId_ISig_ 6000;
BA_REL_ "GenSigFirstTimeoutTime" BU_SG_REL_ VCM SG_ 2566878731 Trailer3TireInfoISO_Leakage_ISig 24000;
BA_REL_ "GenSigTimeoutTime" BU_SG_REL_ VCM SG_ 2566878731 Trailer3TireInfoISO_Leakage_ISig 6000;
BA_REL_ "GenSigFirstTimeoutTime" BU_SG_REL_ VCM SG_ 2566878731 Trailer3TireInfoISO_Active_ISig_ 24000;
BA_REL_ "GenSigTimeoutTime" BU_SG_REL_ VCM SG_ 2566878731 Trailer3TireInfoISO_Active_ISig_ 6000;
BA_REL_ "GenSigFirstTimeoutTime" BU_SG_REL_ VCM SG_ 2566878731 Trailer3TireInfoISO_Warning_ISig 24000;
BA_REL_ "GenSigTimeoutTime" BU_SG_REL_ VCM SG_ 2566878731 Trailer3TireInfoISO_Warning_ISig 6000;
BA_REL_ "GenSigFirstTimeoutTime" BU_SG_REL_ VCM SG_ 2566874123 Trailer2TireInfoISO_Warning_ISig 24000;
BA_REL_ "GenSigTimeoutTime" BU_SG_REL_ VCM SG_ 2566874123 Trailer2TireInfoISO_Warning_ISig 6000;
BA_REL_ "GenSigFirstTimeoutTime" BU_SG_REL_ VCM SG_ 2566874123 Trailer2TireInfoISO_sg_UB_ISig_1 24000;
BA_REL_ "GenSigTimeoutTime" BU_SG_REL_ VCM SG_ 2566874123 Trailer2TireInfoISO_sg_UB_ISig_1 6000;
BA_REL_ "GenSigFirstTimeoutTime" BU_SG_REL_ VCM SG_ 2566874123 Trailer2TireInfoISO_Leakage_ISig 24000;
BA_REL_ "GenSigTimeoutTime" BU_SG_REL_ VCM SG_ 2566874123 Trailer2TireInfoISO_Leakage_ISig 6000;
BA_REL_ "GenSigFirstTimeoutTime" BU_SG_REL_ VCM SG_ 2566874123 Trailer2TireInfoISO_PresSuff_ISi 24000;
BA_REL_ "GenSigTimeoutTime" BU_SG_REL_ VCM SG_ 2566874123 Trailer2TireInfoISO_PresSuff_ISi 6000;
BA_REL_ "GenSigFirstTimeoutTime" BU_SG_REL_ VCM SG_ 2566874123 Trailer2TireInfoISO_Pressure_ISi 24000;
BA_REL_ "GenSigTimeoutTime" BU_SG_REL_ VCM SG_ 2566874123 Trailer2TireInfoISO_Pressure_ISi 6000;
BA_REL_ "GenSigFirstTimeoutTime" BU_SG_REL_ VCM SG_ 2566874123 Trailer2TireInfoISO_Temperature_ 24000;
BA_REL_ "GenSigTimeoutTime" BU_SG_REL_ VCM SG_ 2566874123 Trailer2TireInfoISO_Temperature_ 6000;
BA_REL_ "GenSigFirstTimeoutTime" BU_SG_REL_ VCM SG_ 2566874123 Trailer2TireInfoISO_PowerSupply_ 24000;
BA_REL_ "GenSigTimeoutTime" BU_SG_REL_ VCM SG_ 2566874123 Trailer2TireInfoISO_PowerSupply_ 6000;
BA_REL_ "GenSigFirstTimeoutTime" BU_SG_REL_ VCM SG_ 2566874123 Trailer2TireInfoISO_TireId_ISig_ 24000;
BA_REL_ "GenSigTimeoutTime" BU_SG_REL_ VCM SG_ 2566874123 Trailer2TireInfoISO_TireId_ISig_ 6000;
BA_REL_ "GenSigFirstTimeoutTime" BU_SG_REL_ VCM SG_ 2566874123 Trailer2TireInfoISO_Active_ISig_ 24000;
BA_REL_ "GenSigTimeoutTime" BU_SG_REL_ VCM SG_ 2566874123 Trailer2TireInfoISO_Active_ISig_ 6000;
BA_REL_ "GenSigFirstTimeoutTime" BU_SG_REL_ VCM SG_ 2566869259 Trailer1TireInfoISO_Active_ISig_ 24000;
BA_REL_ "GenSigTimeoutTime" BU_SG_REL_ VCM SG_ 2566869259 Trailer1TireInfoISO_Active_ISig_ 6000;
BA_REL_ "GenSigFirstTimeoutTime" BU_SG_REL_ VCM SG_ 2566869259 Trailer1TireInfoISO_PowerSupply_ 24000;
BA_REL_ "GenSigTimeoutTime" BU_SG_REL_ VCM SG_ 2566869259 Trailer1TireInfoISO_PowerSupply_ 6000;
BA_REL_ "GenSigFirstTimeoutTime" BU_SG_REL_ VCM SG_ 2566869259 Trailer1TireInfoISO_PresSuff_ISi 24000;
BA_REL_ "GenSigTimeoutTime" BU_SG_REL_ VCM SG_ 2566869259 Trailer1TireInfoISO_PresSuff_ISi 6000;
BA_REL_ "GenSigFirstTimeoutTime" BU_SG_REL_ VCM SG_ 2566869259 Trailer1TireInfoISO_Warning_ISig 24000;
BA_REL_ "GenSigTimeoutTime" BU_SG_REL_ VCM SG_ 2566869259 Trailer1TireInfoISO_Warning_ISig 6000;
BA_REL_ "GenSigFirstTimeoutTime" BU_SG_REL_ VCM SG_ 2566869259 Trailer1TireInfoISO_TireId_ISig_ 24000;
BA_REL_ "GenSigTimeoutTime" BU_SG_REL_ VCM SG_ 2566869259 Trailer1TireInfoISO_TireId_ISig_ 6000;
BA_REL_ "GenSigFirstTimeoutTime" BU_SG_REL_ VCM SG_ 2566869259 Trailer1TireInfoISO_sg_UB_ISig_1 24000;
BA_REL_ "GenSigTimeoutTime" BU_SG_REL_ VCM SG_ 2566869259 Trailer1TireInfoISO_sg_UB_ISig_1 6000;
BA_REL_ "GenSigFirstTimeoutTime" BU_SG_REL_ VCM SG_ 2566869259 Trailer1TireInfoISO_Pressure_ISi 24000;
BA_REL_ "GenSigTimeoutTime" BU_SG_REL_ VCM SG_ 2566869259 Trailer1TireInfoISO_Pressure_ISi 6000;
BA_REL_ "GenSigFirstTimeoutTime" BU_SG_REL_ VCM SG_ 2566869259 Trailer1TireInfoISO_Leakage_ISig 24000;
BA_REL_ "GenSigTimeoutTime" BU_SG_REL_ VCM SG_ 2566869259 Trailer1TireInfoISO_Leakage_ISig 6000;
BA_REL_ "GenSigFirstTimeoutTime" BU_SG_REL_ VCM SG_ 2566869259 Trailer1TireInfoISO_Temperature_ 24000;
BA_REL_ "GenSigTimeoutTime" BU_SG_REL_ VCM SG_ 2566869259 Trailer1TireInfoISO_Temperature_ 6000;
BA_REL_ "GenSigFirstTimeoutTime" BU_SG_REL_ VCM SG_ 2566864651 Trailer5BrakeTemp_TireId 3000;
BA_REL_ "GenSigTimeoutTime" BU_SG_REL_ VCM SG_ 2566864651 Trailer5BrakeTemp_TireId 600;
BA_REL_ "GenSigFirstTimeoutTime" BU_SG_REL_ VCM SG_ 2566864651 Trailer5BrakeTemp_Temp 3000;
BA_REL_ "GenSigTimeoutTime" BU_SG_REL_ VCM SG_ 2566864651 Trailer5BrakeTemp_Temp 600;
BA_REL_ "GenSigFirstTimeoutTime" BU_SG_REL_ VCM SG_ 2566864651 Trailer4BrakeTemp_Temp 3000;
BA_REL_ "GenSigTimeoutTime" BU_SG_REL_ VCM SG_ 2566864651 Trailer4BrakeTemp_Temp 600;
BA_REL_ "GenSigFirstTimeoutTime" BU_SG_REL_ VCM SG_ 2566864651 Trailer4BrakeTemp_TireId 3000;
BA_REL_ "GenSigTimeoutTime" BU_SG_REL_ VCM SG_ 2566864651 Trailer4BrakeTemp_TireId 600;
BA_REL_ "GenSigFirstTimeoutTime" BU_SG_REL_ VCM SG_ 2566864651 Trailer4BrakeTemp_Status 3000;
BA_REL_ "GenSigTimeoutTime" BU_SG_REL_ VCM SG_ 2566864651 Trailer4BrakeTemp_Status 600;
BA_REL_ "GenSigFirstTimeoutTime" BU_SG_REL_ VCM SG_ 2566864651 Trailer5BrakeTemp_Status 3000;
BA_REL_ "GenSigTimeoutTime" BU_SG_REL_ VCM SG_ 2566864651 Trailer5BrakeTemp_Status 600;
BA_REL_ "GenSigFirstTimeoutTime" BU_SG_REL_ VCM SG_ 2566860043 Trailer2BrakeTemp_Temp 3000;
BA_REL_ "GenSigTimeoutTime" BU_SG_REL_ VCM SG_ 2566860043 Trailer2BrakeTemp_Temp 600;
BA_REL_ "GenSigFirstTimeoutTime" BU_SG_REL_ VCM SG_ 2566860043 Trailer3BrakeTemp_Status 3000;
BA_REL_ "GenSigTimeoutTime" BU_SG_REL_ VCM SG_ 2566860043 Trailer3BrakeTemp_Status 600;
BA_REL_ "GenSigFirstTimeoutTime" BU_SG_REL_ VCM SG_ 2566860043 Trailer3BrakeTemp_Temp 3000;
BA_REL_ "GenSigTimeoutTime" BU_SG_REL_ VCM SG_ 2566860043 Trailer3BrakeTemp_Temp 600;
BA_REL_ "GenSigFirstTimeoutTime" BU_SG_REL_ VCM SG_ 2566860043 Trailer1BrakeTemp_Status 3000;
BA_REL_ "GenSigTimeoutTime" BU_SG_REL_ VCM SG_ 2566860043 Trailer1BrakeTemp_Status 600;
BA_REL_ "GenSigFirstTimeoutTime" BU_SG_REL_ VCM SG_ 2566860043 Trailer2BrakeTemp_TireId 3000;
BA_REL_ "GenSigTimeoutTime" BU_SG_REL_ VCM SG_ 2566860043 Trailer2BrakeTemp_TireId 600;
BA_REL_ "GenSigFirstTimeoutTime" BU_SG_REL_ VCM SG_ 2566860043 Trailer2BrakeTemp_Status 3000;
BA_REL_ "GenSigTimeoutTime" BU_SG_REL_ VCM SG_ 2566860043 Trailer2BrakeTemp_Status 600;
BA_REL_ "GenSigFirstTimeoutTime" BU_SG_REL_ VCM SG_ 2566860043 Trailer3BrakeTemp_TireId 3000;
BA_REL_ "GenSigTimeoutTime" BU_SG_REL_ VCM SG_ 2566860043 Trailer3BrakeTemp_TireId 600;
BA_REL_ "GenSigFirstTimeoutTime" BU_SG_REL_ VCM SG_ 2566860043 Trailer1BrakeTemp_TireId 3000;
BA_REL_ "GenSigTimeoutTime" BU_SG_REL_ VCM SG_ 2566860043 Trailer1BrakeTemp_TireId 600;
BA_REL_ "GenSigFirstTimeoutTime" BU_SG_REL_ VCM SG_ 2566860043 Trailer1BrakeTemp_Temp 3000;
BA_REL_ "GenSigTimeoutTime" BU_SG_REL_ VCM SG_ 2566860043 Trailer1BrakeTemp_Temp 600;
BA_REL_ "GenSigFirstTimeoutTime" BU_SG_REL_ VCM SG_ 2566855435 Trailer1ABSStatus 3000;
BA_REL_ "GenSigTimeoutTime" BU_SG_REL_ VCM SG_ 2566855435 Trailer1ABSStatus 600;
BA_REL_ "GenSigFirstTimeoutTime" BU_SG_REL_ VCM SG_ 2566855435 Trailer4ABSStatus 3000;
BA_REL_ "GenSigTimeoutTime" BU_SG_REL_ VCM SG_ 2566855435 Trailer4ABSStatus 600;
BA_REL_ "GenSigFirstTimeoutTime" BU_SG_REL_ VCM SG_ 2566855435 Trailer1LateralAcceleration 3000;
BA_REL_ "GenSigTimeoutTime" BU_SG_REL_ VCM SG_ 2566855435 Trailer1LateralAcceleration 600;
BA_REL_ "GenSigFirstTimeoutTime" BU_SG_REL_ VCM SG_ 2566855435 Trailer2ABSStatus 3000;
BA_REL_ "GenSigTimeoutTime" BU_SG_REL_ VCM SG_ 2566855435 Trailer2ABSStatus 600;
BA_REL_ "GenSigFirstTimeoutTime" BU_SG_REL_ VCM SG_ 2566855435 Trailer5ABSStatus 3000;
BA_REL_ "GenSigTimeoutTime" BU_SG_REL_ VCM SG_ 2566855435 Trailer5ABSStatus 600;
BA_REL_ "GenSigFirstTimeoutTime" BU_SG_REL_ VCM SG_ 2566855435 Trailer1WheelSpdDiffMainAxle 3000;
BA_REL_ "GenSigTimeoutTime" BU_SG_REL_ VCM SG_ 2566855435 Trailer1WheelSpdDiffMainAxle 600;
BA_REL_ "GenSigFirstTimeoutTime" BU_SG_REL_ VCM SG_ 2566855435 Trailer3ABSStatus 3000;
BA_REL_ "GenSigTimeoutTime" BU_SG_REL_ VCM SG_ 2566855435 Trailer3ABSStatus 600;
BA_REL_ "GenSigFirstTimeoutTime" BU_SG_REL_ VCM SG_ 2566850827 Trailer4StopLevelChangeAck 3000;
BA_REL_ "GenSigTimeoutTime" BU_SG_REL_ VCM SG_ 2566850827 Trailer4StopLevelChangeAck 600;
BA_REL_ "GenSigFirstTimeoutTime" BU_SG_REL_ VCM SG_ 2566850827 Trailer4NormalLevelStorStat 3000;
BA_REL_ "GenSigTimeoutTime" BU_SG_REL_ VCM SG_ 2566850827 Trailer4NormalLevelStorStat 600;
BA_REL_ "GenSigFirstTimeoutTime" BU_SG_REL_ VCM SG_ 2566850827 Trailer2StopLevelChangeAck 3000;
BA_REL_ "GenSigTimeoutTime" BU_SG_REL_ VCM SG_ 2566850827 Trailer2StopLevelChangeAck 600;
BA_REL_ "GenSigFirstTimeoutTime" BU_SG_REL_ VCM SG_ 2566850827 Trailer4RampLevelStorStat 3000;
BA_REL_ "GenSigTimeoutTime" BU_SG_REL_ VCM SG_ 2566850827 Trailer4RampLevelStorStat 600;
BA_REL_ "GenSigFirstTimeoutTime" BU_SG_REL_ VCM SG_ 2566850827 Trailer5NormalLevelStorStat 3000;
BA_REL_ "GenSigTimeoutTime" BU_SG_REL_ VCM SG_ 2566850827 Trailer5NormalLevelStorStat 600;
BA_REL_ "GenSigFirstTimeoutTime" BU_SG_REL_ VCM SG_ 2566850827 Trailer5LevelChangeFrontAxle 3000;
BA_REL_ "GenSigTimeoutTime" BU_SG_REL_ VCM SG_ 2566850827 Trailer5LevelChangeFrontAxle 600;
BA_REL_ "GenSigFirstTimeoutTime" BU_SG_REL_ VCM SG_ 2566850827 Trailer3NormalLevelStorStat 3000;
BA_REL_ "GenSigTimeoutTime" BU_SG_REL_ VCM SG_ 2566850827 Trailer3NormalLevelStorStat 600;
BA_REL_ "GenSigFirstTimeoutTime" BU_SG_REL_ VCM SG_ 2566850827 Trailer2NormalLevelStorStat 3000;
BA_REL_ "GenSigTimeoutTime" BU_SG_REL_ VCM SG_ 2566850827 Trailer2NormalLevelStorStat 600;
BA_REL_ "GenSigFirstTimeoutTime" BU_SG_REL_ VCM SG_ 2566850827 Trailer4TractionHelp 3000;
BA_REL_ "GenSigTimeoutTime" BU_SG_REL_ VCM SG_ 2566850827 Trailer4TractionHelp 600;
BA_REL_ "GenSigFirstTimeoutTime" BU_SG_REL_ VCM SG_ 2566850827 Trailer5StopLevelChangeAck 3000;
BA_REL_ "GenSigTimeoutTime" BU_SG_REL_ VCM SG_ 2566850827 Trailer5StopLevelChangeAck 600;
BA_REL_ "GenSigFirstTimeoutTime" BU_SG_REL_ VCM SG_ 2566850827 Trailer1LevelChangeRearAxle 3000;
BA_REL_ "GenSigTimeoutTime" BU_SG_REL_ VCM SG_ 2566850827 Trailer1LevelChangeRearAxle 600;
BA_REL_ "GenSigFirstTimeoutTime" BU_SG_REL_ VCM SG_ 2566850827 Trailer4LevelChangeRearAxle 3000;
BA_REL_ "GenSigTimeoutTime" BU_SG_REL_ VCM SG_ 2566850827 Trailer4LevelChangeRearAxle 600;
BA_REL_ "GenSigFirstTimeoutTime" BU_SG_REL_ VCM SG_ 2566850827 Trailer3LevelChangeRearAxle 3000;
BA_REL_ "GenSigTimeoutTime" BU_SG_REL_ VCM SG_ 2566850827 Trailer3LevelChangeRearAxle 600;
BA_REL_ "GenSigFirstTimeoutTime" BU_SG_REL_ VCM SG_ 2566850827 Trailer3TractionHelp 3000;
BA_REL_ "GenSigTimeoutTime" BU_SG_REL_ VCM SG_ 2566850827 Trailer3TractionHelp 600;
BA_REL_ "GenSigFirstTimeoutTime" BU_SG_REL_ VCM SG_ 2566850827 Trailer2LevelChangeRearAxle 3000;
BA_REL_ "GenSigTimeoutTime" BU_SG_REL_ VCM SG_ 2566850827 Trailer2LevelChangeRearAxle 600;
BA_REL_ "GenSigFirstTimeoutTime" BU_SG_REL_ VCM SG_ 2566850827 Trailer2RampLevelStorStat 3000;
BA_REL_ "GenSigTimeoutTime" BU_SG_REL_ VCM SG_ 2566850827 Trailer2RampLevelStorStat 600;
BA_REL_ "GenSigFirstTimeoutTime" BU_SG_REL_ VCM SG_ 2566850827 Trailer3StopLevelChangeAck 3000;
BA_REL_ "GenSigTimeoutTime" BU_SG_REL_ VCM SG_ 2566850827 Trailer3StopLevelChangeAck 600;
BA_REL_ "GenSigFirstTimeoutTime" BU_SG_REL_ VCM SG_ 2566850827 Trailer5LevelChangeRearAxle 3000;
BA_REL_ "GenSigTimeoutTime" BU_SG_REL_ VCM SG_ 2566850827 Trailer5LevelChangeRearAxle 600;
BA_REL_ "GenSigFirstTimeoutTime" BU_SG_REL_ VCM SG_ 2566850827 Trailer4LevelChangeFrontAxle 3000;
BA_REL_ "GenSigTimeoutTime" BU_SG_REL_ VCM SG_ 2566850827 Trailer4LevelChangeFrontAxle 600;
BA_REL_ "GenSigFirstTimeoutTime" BU_SG_REL_ VCM SG_ 2566850827 Trailer2TractionHelp 3000;
BA_REL_ "GenSigTimeoutTime" BU_SG_REL_ VCM SG_ 2566850827 Trailer2TractionHelp 600;
BA_REL_ "GenSigFirstTimeoutTime" BU_SG_REL_ VCM SG_ 2566850827 Trailer1RampLevelStorStat 3000;
BA_REL_ "GenSigTimeoutTime" BU_SG_REL_ VCM SG_ 2566850827 Trailer1RampLevelStorStat 600;
BA_REL_ "GenSigFirstTimeoutTime" BU_SG_REL_ VCM SG_ 2566850827 Trailer5RampLevelStorStat 3000;
BA_REL_ "GenSigTimeoutTime" BU_SG_REL_ VCM SG_ 2566850827 Trailer5RampLevelStorStat 600;
BA_REL_ "GenSigFirstTimeoutTime" BU_SG_REL_ VCM SG_ 2566850827 Trailer3LevelChangeFrontAxle 3000;
BA_REL_ "GenSigTimeoutTime" BU_SG_REL_ VCM SG_ 2566850827 Trailer3LevelChangeFrontAxle 600;
BA_REL_ "GenSigFirstTimeoutTime" BU_SG_REL_ VCM SG_ 2566850827 Trailer1StopLevelChangeAck 3000;
BA_REL_ "GenSigTimeoutTime" BU_SG_REL_ VCM SG_ 2566850827 Trailer1StopLevelChangeAck 600;
BA_REL_ "GenSigFirstTimeoutTime" BU_SG_REL_ VCM SG_ 2566850827 Trailer2LevelChangeFrontAxle 3000;
BA_REL_ "GenSigTimeoutTime" BU_SG_REL_ VCM SG_ 2566850827 Trailer2LevelChangeFrontAxle 600;
BA_REL_ "GenSigFirstTimeoutTime" BU_SG_REL_ VCM SG_ 2566850827 Trailer5TractionHelp 3000;
BA_REL_ "GenSigTimeoutTime" BU_SG_REL_ VCM SG_ 2566850827 Trailer5TractionHelp 600;
BA_REL_ "GenSigFirstTimeoutTime" BU_SG_REL_ VCM SG_ 2566850827 Trailer1LevelChangeFrontAxle 3000;
BA_REL_ "GenSigTimeoutTime" BU_SG_REL_ VCM SG_ 2566850827 Trailer1LevelChangeFrontAxle 600;
BA_REL_ "GenSigFirstTimeoutTime" BU_SG_REL_ VCM SG_ 2566850827 Trailer3RampLevelStorStat 3000;
BA_REL_ "GenSigTimeoutTime" BU_SG_REL_ VCM SG_ 2566850827 Trailer3RampLevelStorStat 600;
BA_REL_ "GenSigFirstTimeoutTime" BU_SG_REL_ VCM SG_ 2566850827 Trailer1NormalLevelStorStat 3000;
BA_REL_ "GenSigTimeoutTime" BU_SG_REL_ VCM SG_ 2566850827 Trailer1NormalLevelStorStat 600;
BA_REL_ "GenSigFirstTimeoutTime" BU_SG_REL_ VCM SG_ 2566899211 Trailer5TowedVehStat_BrakeSystem 24000;
BA_REL_ "GenSigTimeoutTime" BU_SG_REL_ VCM SG_ 2566899211 Trailer5TowedVehStat_BrakeSystem 6000;
BA_REL_ "GenSigFirstTimeoutTime" BU_SG_REL_ VCM SG_ 2566899211 Trailer4TowedVehStat_DetectSupp 24000;
BA_REL_ "GenSigTimeoutTime" BU_SG_REL_ VCM SG_ 2566899211 Trailer4TowedVehStat_DetectSupp 6000;
BA_REL_ "GenSigFirstTimeoutTime" BU_SG_REL_ VCM SG_ 2566899211 Trailer4TowedVehStat_CANAvail 24000;
BA_REL_ "GenSigTimeoutTime" BU_SG_REL_ VCM SG_ 2566899211 Trailer4TowedVehStat_CANAvail 6000;
BA_REL_ "GenSigFirstTimeoutTime" BU_SG_REL_ VCM SG_ 2566899211 Trailer3TowedVehStat_DetectStat 24000;
BA_REL_ "GenSigTimeoutTime" BU_SG_REL_ VCM SG_ 2566899211 Trailer3TowedVehStat_DetectStat 6000;
BA_REL_ "GenSigFirstTimeoutTime" BU_SG_REL_ VCM SG_ 2566899211 Trailer1TowedVehStat_DetectSupp 24000;
BA_REL_ "GenSigTimeoutTime" BU_SG_REL_ VCM SG_ 2566899211 Trailer1TowedVehStat_DetectSupp 6000;
BA_REL_ "GenSigFirstTimeoutTime" BU_SG_REL_ VCM SG_ 2566899211 Trailer2TowedVehStat_CANAvail 24000;
BA_REL_ "GenSigTimeoutTime" BU_SG_REL_ VCM SG_ 2566899211 Trailer2TowedVehStat_CANAvail 6000;
BA_REL_ "GenSigFirstTimeoutTime" BU_SG_REL_ VCM SG_ 2566899211 Trailer1TowedVehStat_CANAvail 24000;
BA_REL_ "GenSigTimeoutTime" BU_SG_REL_ VCM SG_ 2566899211 Trailer1TowedVehStat_CANAvail 6000;
BA_REL_ "GenSigFirstTimeoutTime" BU_SG_REL_ VCM SG_ 2566899211 Trailer3TowedVehStat_DetectSupp 24000;
BA_REL_ "GenSigTimeoutTime" BU_SG_REL_ VCM SG_ 2566899211 Trailer3TowedVehStat_DetectSupp 6000;
BA_REL_ "GenSigFirstTimeoutTime" BU_SG_REL_ VCM SG_ 2566899211 Trailer3TowedVehStat_CANAvail 24000;
BA_REL_ "GenSigTimeoutTime" BU_SG_REL_ VCM SG_ 2566899211 Trailer3TowedVehStat_CANAvail 6000;
BA_REL_ "GenSigFirstTimeoutTime" BU_SG_REL_ VCM SG_ 2566899211 Trailer1TowedVehStat_DetectStat 24000;
BA_REL_ "GenSigTimeoutTime" BU_SG_REL_ VCM SG_ 2566899211 Trailer1TowedVehStat_DetectStat 6000;
BA_REL_ "GenSigFirstTimeoutTime" BU_SG_REL_ VCM SG_ 2566899211 Trailer5TowedVehStat_DetectSupp 24000;
BA_REL_ "GenSigTimeoutTime" BU_SG_REL_ VCM SG_ 2566899211 Trailer5TowedVehStat_DetectSupp 6000;
BA_REL_ "GenSigFirstTimeoutTime" BU_SG_REL_ VCM SG_ 2566899211 Trailer4TowedVehStat_DetectStat 24000;
BA_REL_ "GenSigTimeoutTime" BU_SG_REL_ VCM SG_ 2566899211 Trailer4TowedVehStat_DetectStat 6000;
BA_REL_ "GenSigFirstTimeoutTime" BU_SG_REL_ VCM SG_ 2566899211 Trailer4TowedVehStat_BrakeSystem 24000;
BA_REL_ "GenSigTimeoutTime" BU_SG_REL_ VCM SG_ 2566899211 Trailer4TowedVehStat_BrakeSystem 6000;
BA_REL_ "GenSigFirstTimeoutTime" BU_SG_REL_ VCM SG_ 2566899211 Trailer5TowedVehStat_DetectStat 24000;
BA_REL_ "GenSigTimeoutTime" BU_SG_REL_ VCM SG_ 2566899211 Trailer5TowedVehStat_DetectStat 6000;
BA_REL_ "GenSigFirstTimeoutTime" BU_SG_REL_ VCM SG_ 2566899211 Trailer3TowedVehStat_BrakeSystem 24000;
BA_REL_ "GenSigTimeoutTime" BU_SG_REL_ VCM SG_ 2566899211 Trailer3TowedVehStat_BrakeSystem 6000;
BA_REL_ "GenSigFirstTimeoutTime" BU_SG_REL_ VCM SG_ 2566899211 Trailer1TowedVehStat_BrakeSystem 24000;
BA_REL_ "GenSigTimeoutTime" BU_SG_REL_ VCM SG_ 2566899211 Trailer1TowedVehStat_BrakeSystem 6000;
BA_REL_ "GenSigFirstTimeoutTime" BU_SG_REL_ VCM SG_ 2566899211 Trailer5TowedVehStat_CANAvail 24000;
BA_REL_ "GenSigTimeoutTime" BU_SG_REL_ VCM SG_ 2566899211 Trailer5TowedVehStat_CANAvail 6000;
BA_REL_ "GenSigFirstTimeoutTime" BU_SG_REL_ VCM SG_ 2566899211 Trailer2TowedVehStat_DetectStat 24000;
BA_REL_ "GenSigTimeoutTime" BU_SG_REL_ VCM SG_ 2566899211 Trailer2TowedVehStat_DetectStat 6000;
BA_REL_ "GenSigFirstTimeoutTime" BU_SG_REL_ VCM SG_ 2566899211 Trailer2TowedVehStat_BrakeSystem 24000;
BA_REL_ "GenSigTimeoutTime" BU_SG_REL_ VCM SG_ 2566899211 Trailer2TowedVehStat_BrakeSystem 6000;
BA_REL_ "GenSigFirstTimeoutTime" BU_SG_REL_ VCM SG_ 2566899211 Trailer2TowedVehStat_DetectSupp 24000;
BA_REL_ "GenSigTimeoutTime" BU_SG_REL_ VCM SG_ 2566899211 Trailer2TowedVehStat_DetectSupp 6000;
BA_REL_ "GenSigFirstTimeoutTime" BU_SG_REL_ VCM SG_ 2566898955 Trailer5CalibInfo_LoadRange 24000;
BA_REL_ "GenSigTimeoutTime" BU_SG_REL_ VCM SG_ 2566898955 Trailer5CalibInfo_LoadRange 6000;
BA_REL_ "GenSigFirstTimeoutTime" BU_SG_REL_ VCM SG_ 2566898955 Trailer5CalibInfo_AxleId 24000;
BA_REL_ "GenSigTimeoutTime" BU_SG_REL_ VCM SG_ 2566898955 Trailer5CalibInfo_AxleId 6000;
BA_REL_ "GenSigFirstTimeoutTime" BU_SG_REL_ VCM SG_ 2566898955 Trailer5CalibInfo_Year 24000;
BA_REL_ "GenSigTimeoutTime" BU_SG_REL_ VCM SG_ 2566898955 Trailer5CalibInfo_Year 6000;
BA_REL_ "GenSigFirstTimeoutTime" BU_SG_REL_ VCM SG_ 2566898955 Trailer5CalibInfo_ScaleLoad 24000;
BA_REL_ "GenSigTimeoutTime" BU_SG_REL_ VCM SG_ 2566898955 Trailer5CalibInfo_ScaleLoad 6000;
BA_REL_ "GenSigFirstTimeoutTime" BU_SG_REL_ VCM SG_ 2566898955 Trailer5CalibInfo_CalibUsage 24000;
BA_REL_ "GenSigTimeoutTime" BU_SG_REL_ VCM SG_ 2566898955 Trailer5CalibInfo_CalibUsage 6000;
BA_REL_ "GenSigFirstTimeoutTime" BU_SG_REL_ VCM SG_ 2566898955 Trailer5CalibInfo_DataStorage 24000;
BA_REL_ "GenSigTimeoutTime" BU_SG_REL_ VCM SG_ 2566898955 Trailer5CalibInfo_DataStorage 6000;
BA_REL_ "GenSigFirstTimeoutTime" BU_SG_REL_ VCM SG_ 2566898955 Trailer5CalibInfo_UncalibLoad 24000;
BA_REL_ "GenSigTimeoutTime" BU_SG_REL_ VCM SG_ 2566898955 Trailer5CalibInfo_UncalibLoad 6000;
BA_REL_ "GenSigFirstTimeoutTime" BU_SG_REL_ VCM SG_ 2566898955 Trailer5CalibInfo_Month 24000;
BA_REL_ "GenSigTimeoutTime" BU_SG_REL_ VCM SG_ 2566898955 Trailer5CalibInfo_Month 6000;
BA_REL_ "GenSigFirstTimeoutTime" BU_SG_REL_ VCM SG_ 2566898699 Trailer4CalibInfo_AxleId 24000;
BA_REL_ "GenSigTimeoutTime" BU_SG_REL_ VCM SG_ 2566898699 Trailer4CalibInfo_AxleId 6000;
BA_REL_ "GenSigFirstTimeoutTime" BU_SG_REL_ VCM SG_ 2566898699 Trailer4CalibInfo_LoadRange 24000;
BA_REL_ "GenSigTimeoutTime" BU_SG_REL_ VCM SG_ 2566898699 Trailer4CalibInfo_LoadRange 6000;
BA_REL_ "GenSigFirstTimeoutTime" BU_SG_REL_ VCM SG_ 2566898699 Trailer4CalibInfo_CalibUsage 24000;
BA_REL_ "GenSigTimeoutTime" BU_SG_REL_ VCM SG_ 2566898699 Trailer4CalibInfo_CalibUsage 6000;
BA_REL_ "GenSigFirstTimeoutTime" BU_SG_REL_ VCM SG_ 2566898699 Trailer4CalibInfo_UncalibLoad 24000;
BA_REL_ "GenSigTimeoutTime" BU_SG_REL_ VCM SG_ 2566898699 Trailer4CalibInfo_UncalibLoad 6000;
BA_REL_ "GenSigFirstTimeoutTime" BU_SG_REL_ VCM SG_ 2566898699 Trailer4CalibInfo_DataStorage 24000;
BA_REL_ "GenSigTimeoutTime" BU_SG_REL_ VCM SG_ 2566898699 Trailer4CalibInfo_DataStorage 6000;
BA_REL_ "GenSigFirstTimeoutTime" BU_SG_REL_ VCM SG_ 2566898699 Trailer4CalibInfo_ScaleLoad 24000;
BA_REL_ "GenSigTimeoutTime" BU_SG_REL_ VCM SG_ 2566898699 Trailer4CalibInfo_ScaleLoad 6000;
BA_REL_ "GenSigFirstTimeoutTime" BU_SG_REL_ VCM SG_ 2566898699 Trailer4CalibInfo_Year 24000;
BA_REL_ "GenSigTimeoutTime" BU_SG_REL_ VCM SG_ 2566898699 Trailer4CalibInfo_Year 6000;
BA_REL_ "GenSigFirstTimeoutTime" BU_SG_REL_ VCM SG_ 2566898699 Trailer4CalibInfo_Month 24000;
BA_REL_ "GenSigTimeoutTime" BU_SG_REL_ VCM SG_ 2566898699 Trailer4CalibInfo_Month 6000;
BA_REL_ "GenSigFirstTimeoutTime" BU_SG_REL_ VCM SG_ 2566898443 Trailer3CalibInfo_CalibUsage 24000;
BA_REL_ "GenSigTimeoutTime" BU_SG_REL_ VCM SG_ 2566898443 Trailer3CalibInfo_CalibUsage 6000;
BA_REL_ "GenSigFirstTimeoutTime" BU_SG_REL_ VCM SG_ 2566898443 Trailer3CalibInfo_LoadRange 24000;
BA_REL_ "GenSigTimeoutTime" BU_SG_REL_ VCM SG_ 2566898443 Trailer3CalibInfo_LoadRange 6000;
BA_REL_ "GenSigFirstTimeoutTime" BU_SG_REL_ VCM SG_ 2566898443 Trailer3CalibInfo_Month 24000;
BA_REL_ "GenSigTimeoutTime" BU_SG_REL_ VCM SG_ 2566898443 Trailer3CalibInfo_Month 6000;
BA_REL_ "GenSigFirstTimeoutTime" BU_SG_REL_ VCM SG_ 2566898443 Trailer3CalibInfo_ScaleLoad 24000;
BA_REL_ "GenSigTimeoutTime" BU_SG_REL_ VCM SG_ 2566898443 Trailer3CalibInfo_ScaleLoad 6000;
BA_REL_ "GenSigFirstTimeoutTime" BU_SG_REL_ VCM SG_ 2566898443 Trailer3CalibInfo_UncalibLoad 24000;
BA_REL_ "GenSigTimeoutTime" BU_SG_REL_ VCM SG_ 2566898443 Trailer3CalibInfo_UncalibLoad 6000;
BA_REL_ "GenSigFirstTimeoutTime" BU_SG_REL_ VCM SG_ 2566898443 Trailer3CalibInfo_AxleId 24000;
BA_REL_ "GenSigTimeoutTime" BU_SG_REL_ VCM SG_ 2566898443 Trailer3CalibInfo_AxleId 6000;
BA_REL_ "GenSigFirstTimeoutTime" BU_SG_REL_ VCM SG_ 2566898443 Trailer3CalibInfo_Year 24000;
BA_REL_ "GenSigTimeoutTime" BU_SG_REL_ VCM SG_ 2566898443 Trailer3CalibInfo_Year 6000;
BA_REL_ "GenSigFirstTimeoutTime" BU_SG_REL_ VCM SG_ 2566898443 Trailer3CalibInfo_DataStorage 24000;
BA_REL_ "GenSigTimeoutTime" BU_SG_REL_ VCM SG_ 2566898443 Trailer3CalibInfo_DataStorage 6000;
BA_REL_ "GenSigFirstTimeoutTime" BU_SG_REL_ VCM SG_ 2566898187 Trailer2CalibInfo_LoadRange 24000;
BA_REL_ "GenSigTimeoutTime" BU_SG_REL_ VCM SG_ 2566898187 Trailer2CalibInfo_LoadRange 6000;
BA_REL_ "GenSigFirstTimeoutTime" BU_SG_REL_ VCM SG_ 2566898187 Trailer2CalibInfo_DataStorage 24000;
BA_REL_ "GenSigTimeoutTime" BU_SG_REL_ VCM SG_ 2566898187 Trailer2CalibInfo_DataStorage 6000;
BA_REL_ "GenSigFirstTimeoutTime" BU_SG_REL_ VCM SG_ 2566898187 Trailer2CalibInfo_Year 24000;
BA_REL_ "GenSigTimeoutTime" BU_SG_REL_ VCM SG_ 2566898187 Trailer2CalibInfo_Year 6000;
BA_REL_ "GenSigFirstTimeoutTime" BU_SG_REL_ VCM SG_ 2566898187 Trailer2CalibInfo_AxleId 24000;
BA_REL_ "GenSigTimeoutTime" BU_SG_REL_ VCM SG_ 2566898187 Trailer2CalibInfo_AxleId 6000;
BA_REL_ "GenSigFirstTimeoutTime" BU_SG_REL_ VCM SG_ 2566898187 Trailer2CalibInfo_CalibUsage 24000;
BA_REL_ "GenSigTimeoutTime" BU_SG_REL_ VCM SG_ 2566898187 Trailer2CalibInfo_CalibUsage 6000;
BA_REL_ "GenSigFirstTimeoutTime" BU_SG_REL_ VCM SG_ 2566898187 Trailer2CalibInfo_Month 24000;
BA_REL_ "GenSigTimeoutTime" BU_SG_REL_ VCM SG_ 2566898187 Trailer2CalibInfo_Month 6000;
BA_REL_ "GenSigFirstTimeoutTime" BU_SG_REL_ VCM SG_ 2566898187 Trailer2CalibInfo_ScaleLoad 24000;
BA_REL_ "GenSigTimeoutTime" BU_SG_REL_ VCM SG_ 2566898187 Trailer2CalibInfo_ScaleLoad 6000;
BA_REL_ "GenSigFirstTimeoutTime" BU_SG_REL_ VCM SG_ 2566898187 Trailer2CalibInfo_UncalibLoad 24000;
BA_REL_ "GenSigTimeoutTime" BU_SG_REL_ VCM SG_ 2566898187 Trailer2CalibInfo_UncalibLoad 6000;
BA_REL_ "GenSigFirstTimeoutTime" BU_SG_REL_ VCM SG_ 2566897931 Trailer1CalibInfo_Year 24000;
BA_REL_ "GenSigTimeoutTime" BU_SG_REL_ VCM SG_ 2566897931 Trailer1CalibInfo_Year 6000;
BA_REL_ "GenSigFirstTimeoutTime" BU_SG_REL_ VCM SG_ 2566897931 Trailer1CalibInfo_LoadRange 24000;
BA_REL_ "GenSigTimeoutTime" BU_SG_REL_ VCM SG_ 2566897931 Trailer1CalibInfo_LoadRange 6000;
BA_REL_ "GenSigFirstTimeoutTime" BU_SG_REL_ VCM SG_ 2566897931 Trailer1CalibInfo_AxleId 24000;
BA_REL_ "GenSigTimeoutTime" BU_SG_REL_ VCM SG_ 2566897931 Trailer1CalibInfo_AxleId 6000;
BA_REL_ "GenSigFirstTimeoutTime" BU_SG_REL_ VCM SG_ 2566897931 Trailer1CalibInfo_CalibUsage 24000;
BA_REL_ "GenSigTimeoutTime" BU_SG_REL_ VCM SG_ 2566897931 Trailer1CalibInfo_CalibUsage 6000;
BA_REL_ "GenSigFirstTimeoutTime" BU_SG_REL_ VCM SG_ 2566897931 Trailer1CalibInfo_UncalibLoad 24000;
BA_REL_ "GenSigTimeoutTime" BU_SG_REL_ VCM SG_ 2566897931 Trailer1CalibInfo_UncalibLoad 6000;
BA_REL_ "GenSigFirstTimeoutTime" BU_SG_REL_ VCM SG_ 2566897931 Trailer1CalibInfo_Month 24000;
BA_REL_ "GenSigTimeoutTime" BU_SG_REL_ VCM SG_ 2566897931 Trailer1CalibInfo_Month 6000;
BA_REL_ "GenSigFirstTimeoutTime" BU_SG_REL_ VCM SG_ 2566897931 Trailer1CalibInfo_DataStorage 24000;
BA_REL_ "GenSigTimeoutTime" BU_SG_REL_ VCM SG_ 2566897931 Trailer1CalibInfo_DataStorage 6000;
BA_REL_ "GenSigFirstTimeoutTime" BU_SG_REL_ VCM SG_ 2566897931 Trailer1CalibInfo_ScaleLoad 24000;
BA_REL_ "GenSigTimeoutTime" BU_SG_REL_ VCM SG_ 2566897931 Trailer1CalibInfo_ScaleLoad 6000;
BA_REL_ "GenSigFirstTimeoutTime" BU_SG_REL_ VCM SG_ 2566878475 Trailer5BrkLining_Wear 3000;
BA_REL_ "GenSigTimeoutTime" BU_SG_REL_ VCM SG_ 2566878475 Trailer5BrkLining_Wear 600;
BA_REL_ "GenSigFirstTimeoutTime" BU_SG_REL_ VCM SG_ 2566878475 Trailer5BrkLining_BrkLnTireId 3000;
BA_REL_ "GenSigTimeoutTime" BU_SG_REL_ VCM SG_ 2566878475 Trailer5BrkLining_BrkLnTireId 600;
BA_REL_ "GenSigFirstTimeoutTime" BU_SG_REL_ VCM SG_ 2566878475 Trailer5NormalLevel_LvlPos 3000;
BA_REL_ "GenSigTimeoutTime" BU_SG_REL_ VCM SG_ 2566878475 Trailer5NormalLevel_LvlPos 600;
BA_REL_ "GenSigFirstTimeoutTime" BU_SG_REL_ VCM SG_ 2566878475 Trailer5NormalLevel_LvlStatus 3000;
BA_REL_ "GenSigTimeoutTime" BU_SG_REL_ VCM SG_ 2566878475 Trailer5NormalLevel_LvlStatus 600;
BA_REL_ "GenSigFirstTimeoutTime" BU_SG_REL_ VCM SG_ 2566878475 Trailer5RampLevel_LvlStatus 3000;
BA_REL_ "GenSigTimeoutTime" BU_SG_REL_ VCM SG_ 2566878475 Trailer5RampLevel_LvlStatus 600;
BA_REL_ "GenSigFirstTimeoutTime" BU_SG_REL_ VCM SG_ 2566878475 Trailer5BrkLining_Warning 3000;
BA_REL_ "GenSigTimeoutTime" BU_SG_REL_ VCM SG_ 2566878475 Trailer5BrkLining_Warning 600;
BA_REL_ "GenSigFirstTimeoutTime" BU_SG_REL_ VCM SG_ 2566878475 Trailer5RelBodyLevel_RearLevel 3000;
BA_REL_ "GenSigTimeoutTime" BU_SG_REL_ VCM SG_ 2566878475 Trailer5RelBodyLevel_RearLevel 600;
BA_REL_ "GenSigFirstTimeoutTime" BU_SG_REL_ VCM SG_ 2566878475 Trailer5RelBodyLevel_FrontLevel 3000;
BA_REL_ "GenSigTimeoutTime" BU_SG_REL_ VCM SG_ 2566878475 Trailer5RelBodyLevel_FrontLevel 600;
BA_REL_ "GenSigFirstTimeoutTime" BU_SG_REL_ VCM SG_ 2566878475 Trailer5RampLevel_LvlPos 3000;
BA_REL_ "GenSigTimeoutTime" BU_SG_REL_ VCM SG_ 2566878475 Trailer5RampLevel_LvlPos 600;
BA_REL_ "GenSigFirstTimeoutTime" BU_SG_REL_ VCM SG_ 2566878219 Trailer4RampLevel_LvlStatus 3000;
BA_REL_ "GenSigTimeoutTime" BU_SG_REL_ VCM SG_ 2566878219 Trailer4RampLevel_LvlStatus 600;
BA_REL_ "GenSigFirstTimeoutTime" BU_SG_REL_ VCM SG_ 2566878219 Trailer4BrkLining_BrkLnTireId 3000;
BA_REL_ "GenSigTimeoutTime" BU_SG_REL_ VCM SG_ 2566878219 Trailer4BrkLining_BrkLnTireId 600;
BA_REL_ "GenSigFirstTimeoutTime" BU_SG_REL_ VCM SG_ 2566878219 Trailer4BrkLining_Wear 3000;
BA_REL_ "GenSigTimeoutTime" BU_SG_REL_ VCM SG_ 2566878219 Trailer4BrkLining_Wear 600;
BA_REL_ "GenSigFirstTimeoutTime" BU_SG_REL_ VCM SG_ 2566878219 Trailer4NormalLevel_LvlStatus 3000;
BA_REL_ "GenSigTimeoutTime" BU_SG_REL_ VCM SG_ 2566878219 Trailer4NormalLevel_LvlStatus 600;
BA_REL_ "GenSigFirstTimeoutTime" BU_SG_REL_ VCM SG_ 2566878219 Trailer4RelBodyLevel_FrontLevel 3000;
BA_REL_ "GenSigTimeoutTime" BU_SG_REL_ VCM SG_ 2566878219 Trailer4RelBodyLevel_FrontLevel 600;
BA_REL_ "GenSigFirstTimeoutTime" BU_SG_REL_ VCM SG_ 2566878219 Trailer4BrkLining_Warning 3000;
BA_REL_ "GenSigTimeoutTime" BU_SG_REL_ VCM SG_ 2566878219 Trailer4BrkLining_Warning 600;
BA_REL_ "GenSigFirstTimeoutTime" BU_SG_REL_ VCM SG_ 2566878219 Trailer4NormalLevel_LvlPos 3000;
BA_REL_ "GenSigTimeoutTime" BU_SG_REL_ VCM SG_ 2566878219 Trailer4NormalLevel_LvlPos 600;
BA_REL_ "GenSigFirstTimeoutTime" BU_SG_REL_ VCM SG_ 2566878219 Trailer4RampLevel_LvlPos 3000;
BA_REL_ "GenSigTimeoutTime" BU_SG_REL_ VCM SG_ 2566878219 Trailer4RampLevel_LvlPos 600;
BA_REL_ "GenSigFirstTimeoutTime" BU_SG_REL_ VCM SG_ 2566878219 Trailer4RelBodyLevel_RearLevel 3000;
BA_REL_ "GenSigTimeoutTime" BU_SG_REL_ VCM SG_ 2566878219 Trailer4RelBodyLevel_RearLevel 600;
BA_REL_ "GenSigFirstTimeoutTime" BU_SG_REL_ VCM SG_ 2566877963 Trailer3RampLevel_LvlStatus 3000;
BA_REL_ "GenSigTimeoutTime" BU_SG_REL_ VCM SG_ 2566877963 Trailer3RampLevel_LvlStatus 600;
BA_REL_ "GenSigFirstTimeoutTime" BU_SG_REL_ VCM SG_ 2566877963 Trailer3RampLevel_LvlPos 3000;
BA_REL_ "GenSigTimeoutTime" BU_SG_REL_ VCM SG_ 2566877963 Trailer3RampLevel_LvlPos 600;
BA_REL_ "GenSigFirstTimeoutTime" BU_SG_REL_ VCM SG_ 2566877963 Trailer3NormalLevel_LvlPos 3000;
BA_REL_ "GenSigTimeoutTime" BU_SG_REL_ VCM SG_ 2566877963 Trailer3NormalLevel_LvlPos 600;
BA_REL_ "GenSigFirstTimeoutTime" BU_SG_REL_ VCM SG_ 2566877963 Trailer3BrkLining_BrkLnTireId 3000;
BA_REL_ "GenSigTimeoutTime" BU_SG_REL_ VCM SG_ 2566877963 Trailer3BrkLining_BrkLnTireId 600;
BA_REL_ "GenSigFirstTimeoutTime" BU_SG_REL_ VCM SG_ 2566877963 Trailer3BrkLining_Wear 3000;
BA_REL_ "GenSigTimeoutTime" BU_SG_REL_ VCM SG_ 2566877963 Trailer3BrkLining_Wear 600;
BA_REL_ "GenSigFirstTimeoutTime" BU_SG_REL_ VCM SG_ 2566877963 Trailer3RelBodyLevel_RearLevel 3000;
BA_REL_ "GenSigTimeoutTime" BU_SG_REL_ VCM SG_ 2566877963 Trailer3RelBodyLevel_RearLevel 600;
BA_REL_ "GenSigFirstTimeoutTime" BU_SG_REL_ VCM SG_ 2566877963 Trailer3NormalLevel_LvlStatus 3000;
BA_REL_ "GenSigTimeoutTime" BU_SG_REL_ VCM SG_ 2566877963 Trailer3NormalLevel_LvlStatus 600;
BA_REL_ "GenSigFirstTimeoutTime" BU_SG_REL_ VCM SG_ 2566877963 Trailer3BrkLining_Warning 3000;
BA_REL_ "GenSigTimeoutTime" BU_SG_REL_ VCM SG_ 2566877963 Trailer3BrkLining_Warning 600;
BA_REL_ "GenSigFirstTimeoutTime" BU_SG_REL_ VCM SG_ 2566877963 Trailer3RelBodyLevel_FrontLevel 3000;
BA_REL_ "GenSigTimeoutTime" BU_SG_REL_ VCM SG_ 2566877963 Trailer3RelBodyLevel_FrontLevel 600;
BA_REL_ "GenSigFirstTimeoutTime" BU_SG_REL_ VCM SG_ 2566877707 Trailer2BrkLining_Warning 3000;
BA_REL_ "GenSigTimeoutTime" BU_SG_REL_ VCM SG_ 2566877707 Trailer2BrkLining_Warning 600;
BA_REL_ "GenSigFirstTimeoutTime" BU_SG_REL_ VCM SG_ 2566877707 Trailer2RampLevel_LvlPos 3000;
BA_REL_ "GenSigTimeoutTime" BU_SG_REL_ VCM SG_ 2566877707 Trailer2RampLevel_LvlPos 600;
BA_REL_ "GenSigFirstTimeoutTime" BU_SG_REL_ VCM SG_ 2566877707 Trailer2BrkLining_Wear 3000;
BA_REL_ "GenSigTimeoutTime" BU_SG_REL_ VCM SG_ 2566877707 Trailer2BrkLining_Wear 600;
BA_REL_ "GenSigFirstTimeoutTime" BU_SG_REL_ VCM SG_ 2566877707 Trailer2BrkLining_BrkLnTireId 3000;
BA_REL_ "GenSigTimeoutTime" BU_SG_REL_ VCM SG_ 2566877707 Trailer2BrkLining_BrkLnTireId 600;
BA_REL_ "GenSigFirstTimeoutTime" BU_SG_REL_ VCM SG_ 2566877707 Trailer2RampLevel_LvlStatus 3000;
BA_REL_ "GenSigTimeoutTime" BU_SG_REL_ VCM SG_ 2566877707 Trailer2RampLevel_LvlStatus 600;
BA_REL_ "GenSigFirstTimeoutTime" BU_SG_REL_ VCM SG_ 2566877707 Trailer2RelBodyLevel_RearLevel 3000;
BA_REL_ "GenSigTimeoutTime" BU_SG_REL_ VCM SG_ 2566877707 Trailer2RelBodyLevel_RearLevel 600;
BA_REL_ "GenSigFirstTimeoutTime" BU_SG_REL_ VCM SG_ 2566877707 Trailer2NormalLevel_LvlPos 3000;
BA_REL_ "GenSigTimeoutTime" BU_SG_REL_ VCM SG_ 2566877707 Trailer2NormalLevel_LvlPos 600;
BA_REL_ "GenSigFirstTimeoutTime" BU_SG_REL_ VCM SG_ 2566877707 Trailer2RelBodyLevel_FrontLevel 3000;
BA_REL_ "GenSigTimeoutTime" BU_SG_REL_ VCM SG_ 2566877707 Trailer2RelBodyLevel_FrontLevel 600;
BA_REL_ "GenSigFirstTimeoutTime" BU_SG_REL_ VCM SG_ 2566877707 Trailer2NormalLevel_LvlStatus 3000;
BA_REL_ "GenSigTimeoutTime" BU_SG_REL_ VCM SG_ 2566877707 Trailer2NormalLevel_LvlStatus 600;
BA_REL_ "GenSigFirstTimeoutTime" BU_SG_REL_ VCM SG_ 2566877451 Trailer1RelBodyLevel_FrontLevel 3000;
BA_REL_ "GenSigTimeoutTime" BU_SG_REL_ VCM SG_ 2566877451 Trailer1RelBodyLevel_FrontLevel 600;
BA_REL_ "GenSigFirstTimeoutTime" BU_SG_REL_ VCM SG_ 2566877451 Trailer1BrkLining_BrkLnTireId 3000;
BA_REL_ "GenSigTimeoutTime" BU_SG_REL_ VCM SG_ 2566877451 Trailer1BrkLining_BrkLnTireId 600;
BA_REL_ "GenSigFirstTimeoutTime" BU_SG_REL_ VCM SG_ 2566877451 Trailer1BrkLining_Wear 3000;
BA_REL_ "GenSigTimeoutTime" BU_SG_REL_ VCM SG_ 2566877451 Trailer1BrkLining_Wear 600;
BA_REL_ "GenSigFirstTimeoutTime" BU_SG_REL_ VCM SG_ 2566877451 Trailer1NormalLevel_LvlPos 3000;
BA_REL_ "GenSigTimeoutTime" BU_SG_REL_ VCM SG_ 2566877451 Trailer1NormalLevel_LvlPos 600;
BA_REL_ "GenSigFirstTimeoutTime" BU_SG_REL_ VCM SG_ 2566877451 Trailer1BrkLining_Warning 3000;
BA_REL_ "GenSigTimeoutTime" BU_SG_REL_ VCM SG_ 2566877451 Trailer1BrkLining_Warning 600;
BA_REL_ "GenSigFirstTimeoutTime" BU_SG_REL_ VCM SG_ 2566877451 Trailer1RampLevel_LvlPos 3000;
BA_REL_ "GenSigTimeoutTime" BU_SG_REL_ VCM SG_ 2566877451 Trailer1RampLevel_LvlPos 600;
BA_REL_ "GenSigFirstTimeoutTime" BU_SG_REL_ VCM SG_ 2566877451 Trailer1NormalLevel_LvlStatus 3000;
BA_REL_ "GenSigTimeoutTime" BU_SG_REL_ VCM SG_ 2566877451 Trailer1NormalLevel_LvlStatus 600;
BA_REL_ "GenSigFirstTimeoutTime" BU_SG_REL_ VCM SG_ 2566877451 Trailer1RampLevel_LvlStatus 3000;
BA_REL_ "GenSigTimeoutTime" BU_SG_REL_ VCM SG_ 2566877451 Trailer1RampLevel_LvlStatus 600;
BA_REL_ "GenSigFirstTimeoutTime" BU_SG_REL_ VCM SG_ 2566877451 Trailer1RelBodyLevel_RearLevel 3000;
BA_REL_ "GenSigTimeoutTime" BU_SG_REL_ VCM SG_ 2566877451 Trailer1RelBodyLevel_RearLevel 600;
BA_REL_ "GenSigFirstTimeoutTime" BU_SG_REL_ VCM SG_ 2566894859 Trailer5VIN 60000;
BA_REL_ "GenSigTimeoutTime" BU_SG_REL_ VCM SG_ 2566894859 Trailer5VIN 60000;
BA_REL_ "GenSigFirstTimeoutTime" BU_SG_REL_ VCM SG_ 2566894603 Trailer4VIN 60000;
BA_REL_ "GenSigTimeoutTime" BU_SG_REL_ VCM SG_ 2566894603 Trailer4VIN 60000;
BA_REL_ "GenSigFirstTimeoutTime" BU_SG_REL_ VCM SG_ 2566894347 Trailer3VIN 60000;
BA_REL_ "GenSigTimeoutTime" BU_SG_REL_ VCM SG_ 2566894347 Trailer3VIN 60000;
BA_REL_ "GenSigFirstTimeoutTime" BU_SG_REL_ VCM SG_ 2566894091 Trailer2VIN 60000;
BA_REL_ "GenSigTimeoutTime" BU_SG_REL_ VCM SG_ 2566894091 Trailer2VIN 60000;
BA_REL_ "GenSigFirstTimeoutTime" BU_SG_REL_ VCM SG_ 2566893835 Trailer1VIN 60000;
BA_REL_ "GenSigTimeoutTime" BU_SG_REL_ VCM SG_ 2566893835 Trailer1VIN 60000;
VAL_ 2566897419 Trailer2LevelControlStatus 3 "DisableEnable_NotAvailable" 2 "DisableEnable_Error" 1 "DisableEnable_Enable" 0 "DisableEnable_Disable" ;
VAL_ 2566897419 Trailer2VehicleType 3 "TrailerVehicleType_NotAvailable" 2 "TrailerVehicleType_Error" 1 "TrailerVehicleType_ConverterDollyAxle" 0 "TrailerVehicleType_TowingOrTowedVehicle" ;
VAL_ 2566897419 Trailer2EBSAmberWarning 3 "WarningIndicator_NotAvailable" 2 "WarningIndicator_Flashing" 1 "WarningIndicator_OnContinuously" 0 "WarningIndicator_Off" ;
VAL_ 2566897419 Trailer2EBSRedWarning 3 "OffOn_NotAvailable" 2 "OffOn_Error" 1 "OffOn_On" 0 "OffOn_Off" ;
VAL_ 2566897419 Trailer2LoadRampApprAssistStat 3 "ActiveStatus_NotAvailable" 2 "ActiveStatus_Error" 1 "ActiveStatus_Active" 0 "ActiveStatus_NotActive" ;
VAL_ 2566897419 Trailer2PneumSupply_Status 3 "InsufficientSufficient_NotAvailable" 2 "InsufficientSufficient_Error" 1 "InsufficientSufficient_Sufficient" 0 "InsufficientSufficient_Insufficient" ;
VAL_ 2566897419 Trailer2YCSystemStatus 3 "DisableEnable_NotAvailable" 2 "DisableEnable_Error" 1 "DisableEnable_Enable" 0 "DisableEnable_Disable" ;
VAL_ 2566897419 Trailer2ElectricalSupplyStat 3 "InsufficientSufficient_NotAvailable" 2 "InsufficientSufficient_Error" 1 "InsufficientSufficient_Sufficient" 0 "InsufficientSufficient_Insufficient" ;
VAL_ 2566897419 Trailer2ROPSystemStatus 3 "DisableEnable_NotAvailable" 2 "DisableEnable_Error" 1 "DisableEnable_Enable" 0 "DisableEnable_Disable" ;
VAL_ 2566897419 Trailer2ExtLvlStorageSupport 3 "TrailerExtLvlStorageSupport_NotSupported" 2 "TrailerExtLvlStorageSupport_Error" 1 "TrailerExtLvlStorageSupport_SupportedIn2ExtendedSets" 0 "TrailerExtLvlStorageSupport_SupportedInAll3Sets" ;
VAL_ 2566892811 Trailer1EBSRedWarning 3 "OffOn_NotAvailable" 2 "OffOn_Error" 1 "OffOn_On" 0 "OffOn_Off" ;
VAL_ 2566892811 Trailer1VehicleType 3 "TrailerVehicleType_NotAvailable" 2 "TrailerVehicleType_Error" 1 "TrailerVehicleType_ConverterDollyAxle" 0 "TrailerVehicleType_TowingOrTowedVehicle" ;
VAL_ 2566892811 Trailer1LoadRampApprAssistStat 3 "ActiveStatus_NotAvailable" 2 "ActiveStatus_Error" 1 "ActiveStatus_Active" 0 "ActiveStatus_NotActive" ;
VAL_ 2566892811 Trailer1YCSystemStatus 3 "DisableEnable_NotAvailable" 2 "DisableEnable_Error" 1 "DisableEnable_Enable" 0 "DisableEnable_Disable" ;
VAL_ 2566892811 Trailer1EBSAmberWarning 3 "WarningIndicator_NotAvailable" 2 "WarningIndicator_Flashing" 1 "WarningIndicator_OnContinuously" 0 "WarningIndicator_Off" ;
VAL_ 2566892811 Trailer1ElectricalSupplyStat 3 "InsufficientSufficient_NotAvailable" 2 "InsufficientSufficient_Error" 1 "InsufficientSufficient_Sufficient" 0 "InsufficientSufficient_Insufficient" ;
VAL_ 2566892811 Trailer1ROPSystemStatus 3 "DisableEnable_NotAvailable" 2 "DisableEnable_Error" 1 "DisableEnable_Enable" 0 "DisableEnable_Disable" ;
VAL_ 2566892811 Trailer1PneumSupply_Status 3 "InsufficientSufficient_NotAvailable" 2 "InsufficientSufficient_Error" 1 "InsufficientSufficient_Sufficient" 0 "InsufficientSufficient_Insufficient" ;
VAL_ 2566892811 Trailer1ExtLvlStorageSupport 3 "TrailerExtLvlStorageSupport_NotSupported" 2 "TrailerExtLvlStorageSupport_Error" 1 "TrailerExtLvlStorageSupport_SupportedIn2ExtendedSets" 0 "TrailerExtLvlStorageSupport_SupportedInAll3Sets" ;
VAL_ 2566892811 Trailer1LevelControlStatus 3 "DisableEnable_NotAvailable" 2 "DisableEnable_Error" 1 "DisableEnable_Enable" 0 "DisableEnable_Disable" ;
VAL_ 2566887947 Trailer5TireInfoISO_PowerSupply_ 3 "TPMISOPowerSupply_NotAvailable" 2 "TPMISOPowerSupply_Error" 1 "TPMISOPowerSupply_SufficientPowerSupply" 0 "TPMISOPowerSupply_InsufficientPowerSupply" ;
VAL_ 2566887947 Trailer5TireInfoISO_PresSuff_ISi 3 "TPMISOPresSuff_NotAvailable" 2 "TPMISOPresSuff_Error" 1 "TPMISOPresSuff_TirePressureSufficient" 0 "TPMISOPresSuff_TirePressureInsufficient" ;
VAL_ 2566887947 Trailer5TireInfoISO_Warning_ISig 7 "TPMPressureWarning_NotAvailable" 6 "TPMPressureWarning_Error" 5 "TPMPressureWarning_Spare" 4 "TPMPressureWarning_ExtremeUnderPressure" 3 "TPMPressureWarning_UnderPressure" 2 "TPMPressureWarning_NoWarningPressure" 1 "TPMPressureWarning_OverPressure" 0 "TPMPressureWarning_ExtremeOverPressure" ;
VAL_ 2566887947 Trailer5TireInfoISO_Active_ISig_ 3 "TPMTireActive_NotAvailable" 2 "TPMTireActive_Error" 1 "TPMTireActive_TireActivePositioned" 0 "TPMTireActive_TireNotActive" ;
VAL_ 2566883339 Trailer4TireInfoISO_PowerSupply_ 3 "TPMISOPowerSupply_NotAvailable" 2 "TPMISOPowerSupply_Error" 1 "TPMISOPowerSupply_SufficientPowerSupply" 0 "TPMISOPowerSupply_InsufficientPowerSupply" ;
VAL_ 2566883339 Trailer4TireInfoISO_Warning_ISig 7 "TPMPressureWarning_NotAvailable" 6 "TPMPressureWarning_Error" 5 "TPMPressureWarning_Spare" 4 "TPMPressureWarning_ExtremeUnderPressure" 3 "TPMPressureWarning_UnderPressure" 2 "TPMPressureWarning_NoWarningPressure" 1 "TPMPressureWarning_OverPressure" 0 "TPMPressureWarning_ExtremeOverPressure" ;
VAL_ 2566883339 Trailer4TireInfoISO_Active_ISig_ 3 "TPMTireActive_NotAvailable" 2 "TPMTireActive_Error" 1 "TPMTireActive_TireActivePositioned" 0 "TPMTireActive_TireNotActive" ;
VAL_ 2566883339 Trailer4TireInfoISO_PresSuff_ISi 3 "TPMISOPresSuff_NotAvailable" 2 "TPMISOPresSuff_Error" 1 "TPMISOPresSuff_TirePressureSufficient" 0 "TPMISOPresSuff_TirePressureInsufficient" ;
VAL_ 2566878731 Trailer3TireInfoISO_PowerSupply_ 3 "TPMISOPowerSupply_NotAvailable" 2 "TPMISOPowerSupply_Error" 1 "TPMISOPowerSupply_SufficientPowerSupply" 0 "TPMISOPowerSupply_InsufficientPowerSupply" ;
VAL_ 2566878731 Trailer3TireInfoISO_PresSuff_ISi 3 "TPMISOPresSuff_NotAvailable" 2 "TPMISOPresSuff_Error" 1 "TPMISOPresSuff_TirePressureSufficient" 0 "TPMISOPresSuff_TirePressureInsufficient" ;
VAL_ 2566878731 Trailer3TireInfoISO_Active_ISig_ 3 "TPMTireActive_NotAvailable" 2 "TPMTireActive_Error" 1 "TPMTireActive_TireActivePositioned" 0 "TPMTireActive_TireNotActive" ;
VAL_ 2566878731 Trailer3TireInfoISO_Warning_ISig 7 "TPMPressureWarning_NotAvailable" 6 "TPMPressureWarning_Error" 5 "TPMPressureWarning_Spare" 4 "TPMPressureWarning_ExtremeUnderPressure" 3 "TPMPressureWarning_UnderPressure" 2 "TPMPressureWarning_NoWarningPressure" 1 "TPMPressureWarning_OverPressure" 0 "TPMPressureWarning_ExtremeOverPressure" ;
VAL_ 2566874123 Trailer2TireInfoISO_Warning_ISig 7 "TPMPressureWarning_NotAvailable" 6 "TPMPressureWarning_Error" 5 "TPMPressureWarning_Spare" 4 "TPMPressureWarning_ExtremeUnderPressure" 3 "TPMPressureWarning_UnderPressure" 2 "TPMPressureWarning_NoWarningPressure" 1 "TPMPressureWarning_OverPressure" 0 "TPMPressureWarning_ExtremeOverPressure" ;
VAL_ 2566874123 Trailer2TireInfoISO_PresSuff_ISi 3 "TPMISOPresSuff_NotAvailable" 2 "TPMISOPresSuff_Error" 1 "TPMISOPresSuff_TirePressureSufficient" 0 "TPMISOPresSuff_TirePressureInsufficient" ;
VAL_ 2566874123 Trailer2TireInfoISO_PowerSupply_ 3 "TPMISOPowerSupply_NotAvailable" 2 "TPMISOPowerSupply_Error" 1 "TPMISOPowerSupply_SufficientPowerSupply" 0 "TPMISOPowerSupply_InsufficientPowerSupply" ;
VAL_ 2566874123 Trailer2TireInfoISO_Active_ISig_ 3 "TPMTireActive_NotAvailable" 2 "TPMTireActive_Error" 1 "TPMTireActive_TireActivePositioned" 0 "TPMTireActive_TireNotActive" ;
VAL_ 2566869259 Trailer1TireInfoISO_Active_ISig_ 3 "TPMTireActive_NotAvailable" 2 "TPMTireActive_Error" 1 "TPMTireActive_TireActivePositioned" 0 "TPMTireActive_TireNotActive" ;
VAL_ 2566869259 Trailer1TireInfoISO_PowerSupply_ 3 "TPMISOPowerSupply_NotAvailable" 2 "TPMISOPowerSupply_Error" 1 "TPMISOPowerSupply_SufficientPowerSupply" 0 "TPMISOPowerSupply_InsufficientPowerSupply" ;
VAL_ 2566869259 Trailer1TireInfoISO_PresSuff_ISi 3 "TPMISOPresSuff_NotAvailable" 2 "TPMISOPresSuff_Error" 1 "TPMISOPresSuff_TirePressureSufficient" 0 "TPMISOPresSuff_TirePressureInsufficient" ;
VAL_ 2566869259 Trailer1TireInfoISO_Warning_ISig 7 "TPMPressureWarning_NotAvailable" 6 "TPMPressureWarning_Error" 5 "TPMPressureWarning_Spare" 4 "TPMPressureWarning_ExtremeUnderPressure" 3 "TPMPressureWarning_UnderPressure" 2 "TPMPressureWarning_NoWarningPressure" 1 "TPMPressureWarning_OverPressure" 0 "TPMPressureWarning_ExtremeOverPressure" ;
VAL_ 2566864651 Trailer4BrakeTemp_Status 3 "BrakeTempStatus_NotAvailable" 2 "BrakeTempStatus_Error" 1 "BrakeTempStatus_BrakeTempInsideNormalRange" 0 "BrakeTempStatus_BrakeTempOutOfRange" ;
VAL_ 2566864651 Trailer5BrakeTemp_Status 3 "BrakeTempStatus_NotAvailable" 2 "BrakeTempStatus_Error" 1 "BrakeTempStatus_BrakeTempInsideNormalRange" 0 "BrakeTempStatus_BrakeTempOutOfRange" ;
VAL_ 2566860043 Trailer3BrakeTemp_Status 3 "BrakeTempStatus_NotAvailable" 2 "BrakeTempStatus_Error" 1 "BrakeTempStatus_BrakeTempInsideNormalRange" 0 "BrakeTempStatus_BrakeTempOutOfRange" ;
VAL_ 2566860043 Trailer1BrakeTemp_Status 3 "BrakeTempStatus_NotAvailable" 2 "BrakeTempStatus_Error" 1 "BrakeTempStatus_BrakeTempInsideNormalRange" 0 "BrakeTempStatus_BrakeTempOutOfRange" ;
VAL_ 2566860043 Trailer2BrakeTemp_Status 3 "BrakeTempStatus_NotAvailable" 2 "BrakeTempStatus_Error" 1 "BrakeTempStatus_BrakeTempInsideNormalRange" 0 "BrakeTempStatus_BrakeTempOutOfRange" ;
VAL_ 2566855435 Trailer1ABSStatus 3 "PassiveActive_NotAvailable" 2 "PassiveActive_Error" 1 "PassiveActive_Active" 0 "PassiveActive_Passive" ;
VAL_ 2566855435 Trailer4ABSStatus 3 "PassiveActive_NotAvailable" 2 "PassiveActive_Error" 1 "PassiveActive_Active" 0 "PassiveActive_Passive" ;
VAL_ 2566855435 Trailer2ABSStatus 3 "PassiveActive_NotAvailable" 2 "PassiveActive_Error" 1 "PassiveActive_Active" 0 "PassiveActive_Passive" ;
VAL_ 2566855435 Trailer5ABSStatus 3 "PassiveActive_NotAvailable" 2 "PassiveActive_Error" 1 "PassiveActive_Active" 0 "PassiveActive_Passive" ;
VAL_ 2566855435 Trailer3ABSStatus 3 "PassiveActive_NotAvailable" 2 "PassiveActive_Error" 1 "PassiveActive_Active" 0 "PassiveActive_Passive" ;
VAL_ 2566850827 Trailer4StopLevelChangeAck 3 "StopLevelChangeStatus_NotAvailable" 2 "StopLevelChangeStatus_ErrorIndicator" 1 "StopLevelChangeStatus_LevelChangedStopped" 0 "StopLevelChangeStatus_NoStopRequest" ;
VAL_ 2566850827 Trailer4NormalLevelStorStat 3 "TrailerNormalLevelStorStat_NotAvailable" 2 "TrailerNormalLevelStorStat_RideHeightNotStoredInReqSet" 1 "TrailerNormalLevelStorStat_NewRideHeightStored" 0 "TrailerNormalLevelStorStat_NoNewRideHeightStorageRequest" ;
VAL_ 2566850827 Trailer2StopLevelChangeAck 3 "StopLevelChangeStatus_NotAvailable" 2 "StopLevelChangeStatus_ErrorIndicator" 1 "StopLevelChangeStatus_LevelChangedStopped" 0 "StopLevelChangeStatus_NoStopRequest" ;
VAL_ 2566850827 Trailer4RampLevelStorStat 3 "TrailerRampLevelStorStat_NotAvailable" 2 "TrailerRampLevelStorStat_Error" 1 "TrailerRampLevelStorStat_NewRampLevelStored" 0 "TrailerRampLevelStorStat_NoNewRampLevelStored" ;
VAL_ 2566850827 Trailer5NormalLevelStorStat 3 "TrailerNormalLevelStorStat_NotAvailable" 2 "TrailerNormalLevelStorStat_RideHeightNotStoredInReqSet" 1 "TrailerNormalLevelStorStat_NewRideHeightStored" 0 "TrailerNormalLevelStorStat_NoNewRideHeightStorageRequest" ;
VAL_ 2566850827 Trailer5LevelChangeFrontAxle 3 "ActiveStatus_NotAvailable" 2 "ActiveStatus_Error" 1 "ActiveStatus_Active" 0 "ActiveStatus_NotActive" ;
VAL_ 2566850827 Trailer3NormalLevelStorStat 3 "TrailerNormalLevelStorStat_NotAvailable" 2 "TrailerNormalLevelStorStat_RideHeightNotStoredInReqSet" 1 "TrailerNormalLevelStorStat_NewRideHeightStored" 0 "TrailerNormalLevelStorStat_NoNewRideHeightStorageRequest" ;
VAL_ 2566850827 Trailer2NormalLevelStorStat 3 "TrailerNormalLevelStorStat_NotAvailable" 2 "TrailerNormalLevelStorStat_RideHeightNotStoredInReqSet" 1 "TrailerNormalLevelStorStat_NewRideHeightStored" 0 "TrailerNormalLevelStorStat_NoNewRideHeightStorageRequest" ;
VAL_ 2566850827 Trailer4TractionHelp 3 "InactiveActive_NotAvailable" 2 "InactiveActive_Error" 1 "InactiveActive_Active" 0 "InactiveActive_Inactive" ;
VAL_ 2566850827 Trailer5StopLevelChangeAck 3 "StopLevelChangeStatus_NotAvailable" 2 "StopLevelChangeStatus_ErrorIndicator" 1 "StopLevelChangeStatus_LevelChangedStopped" 0 "StopLevelChangeStatus_NoStopRequest" ;
VAL_ 2566850827 Trailer1LevelChangeRearAxle 3 "ActiveStatus_NotAvailable" 2 "ActiveStatus_Error" 1 "ActiveStatus_Active" 0 "ActiveStatus_NotActive" ;
VAL_ 2566850827 Trailer4LevelChangeRearAxle 3 "ActiveStatus_NotAvailable" 2 "ActiveStatus_Error" 1 "ActiveStatus_Active" 0 "ActiveStatus_NotActive" ;
VAL_ 2566850827 Trailer3LevelChangeRearAxle 3 "ActiveStatus_NotAvailable" 2 "ActiveStatus_Error" 1 "ActiveStatus_Active" 0 "ActiveStatus_NotActive" ;
VAL_ 2566850827 Trailer3TractionHelp 3 "InactiveActive_NotAvailable" 2 "InactiveActive_Error" 1 "InactiveActive_Active" 0 "InactiveActive_Inactive" ;
VAL_ 2566850827 Trailer2LevelChangeRearAxle 3 "ActiveStatus_NotAvailable" 2 "ActiveStatus_Error" 1 "ActiveStatus_Active" 0 "ActiveStatus_NotActive" ;
VAL_ 2566850827 Trailer2RampLevelStorStat 3 "TrailerRampLevelStorStat_NotAvailable" 2 "TrailerRampLevelStorStat_Error" 1 "TrailerRampLevelStorStat_NewRampLevelStored" 0 "TrailerRampLevelStorStat_NoNewRampLevelStored" ;
VAL_ 2566850827 Trailer3StopLevelChangeAck 3 "StopLevelChangeStatus_NotAvailable" 2 "StopLevelChangeStatus_ErrorIndicator" 1 "StopLevelChangeStatus_LevelChangedStopped" 0 "StopLevelChangeStatus_NoStopRequest" ;
VAL_ 2566850827 Trailer5LevelChangeRearAxle 3 "ActiveStatus_NotAvailable" 2 "ActiveStatus_Error" 1 "ActiveStatus_Active" 0 "ActiveStatus_NotActive" ;
VAL_ 2566850827 Trailer4LevelChangeFrontAxle 3 "ActiveStatus_NotAvailable" 2 "ActiveStatus_Error" 1 "ActiveStatus_Active" 0 "ActiveStatus_NotActive" ;
VAL_ 2566850827 Trailer2TractionHelp 3 "InactiveActive_NotAvailable" 2 "InactiveActive_Error" 1 "InactiveActive_Active" 0 "InactiveActive_Inactive" ;
VAL_ 2566850827 Trailer1RampLevelStorStat 3 "TrailerRampLevelStorStat_NotAvailable" 2 "TrailerRampLevelStorStat_Error" 1 "TrailerRampLevelStorStat_NewRampLevelStored" 0 "TrailerRampLevelStorStat_NoNewRampLevelStored" ;
VAL_ 2566850827 Trailer5RampLevelStorStat 3 "TrailerRampLevelStorStat_NotAvailable" 2 "TrailerRampLevelStorStat_Error" 1 "TrailerRampLevelStorStat_NewRampLevelStored" 0 "TrailerRampLevelStorStat_NoNewRampLevelStored" ;
VAL_ 2566850827 Trailer3LevelChangeFrontAxle 3 "ActiveStatus_NotAvailable" 2 "ActiveStatus_Error" 1 "ActiveStatus_Active" 0 "ActiveStatus_NotActive" ;
VAL_ 2566850827 Trailer1StopLevelChangeAck 3 "StopLevelChangeStatus_NotAvailable" 2 "StopLevelChangeStatus_ErrorIndicator" 1 "StopLevelChangeStatus_LevelChangedStopped" 0 "StopLevelChangeStatus_NoStopRequest" ;
VAL_ 2566850827 Trailer2LevelChangeFrontAxle 3 "ActiveStatus_NotAvailable" 2 "ActiveStatus_Error" 1 "ActiveStatus_Active" 0 "ActiveStatus_NotActive" ;
VAL_ 2566850827 Trailer5TractionHelp 3 "InactiveActive_NotAvailable" 2 "InactiveActive_Error" 1 "InactiveActive_Active" 0 "InactiveActive_Inactive" ;
VAL_ 2566850827 Trailer1LevelChangeFrontAxle 3 "ActiveStatus_NotAvailable" 2 "ActiveStatus_Error" 1 "ActiveStatus_Active" 0 "ActiveStatus_NotActive" ;
VAL_ 2566850827 Trailer3RampLevelStorStat 3 "TrailerRampLevelStorStat_NotAvailable" 2 "TrailerRampLevelStorStat_Error" 1 "TrailerRampLevelStorStat_NewRampLevelStored" 0 "TrailerRampLevelStorStat_NoNewRampLevelStored" ;
VAL_ 2566850827 Trailer1NormalLevelStorStat 3 "TrailerNormalLevelStorStat_NotAvailable" 2 "TrailerNormalLevelStorStat_RideHeightNotStoredInReqSet" 1 "TrailerNormalLevelStorStat_NewRideHeightStored" 0 "TrailerNormalLevelStorStat_NoNewRideHeightStorageRequest" ;
VAL_ 2566899211 Trailer5TowedVehStat_BrakeSystem 3 "BrakeSystem_NotAvailable" 2 "BrakeSystem_EBS" 1 "BrakeSystem_ABS" 0 "BrakeSystem_None" ;
VAL_ 2566899211 Trailer4TowedVehStat_DetectSupp 3 "TrailerDetectSupp_NotAvailable" 2 "TrailerDetectSupp_Error" 1 "TrailerDetectSupp_TrailerDetectionSupport" 0 "TrailerDetectSupp_NoTrailerDetectionSupport" ;
VAL_ 2566899211 Trailer4TowedVehStat_CANAvail 3 "CANAvail_NotAvailable" 2 "CANAvail_Error" 1 "CANAvail_CANInterfaceAvailable" 0 "CANAvail_NoCANInterfaceAvailable" ;
VAL_ 2566899211 Trailer3TowedVehStat_DetectStat 3 "TrailerDetectStat_NotAvailable" 2 "TrailerDetectStat_ErrorTrailerDetectionNotPossible" 1 "TrailerDetectStat_NoTowedVehicleDetected" 0 "TrailerDetectStat_TowedVehicleDeteted" ;
VAL_ 2566899211 Trailer1TowedVehStat_DetectSupp 3 "TrailerDetectSupp_NotAvailable" 2 "TrailerDetectSupp_Error" 1 "TrailerDetectSupp_TrailerDetectionSupport" 0 "TrailerDetectSupp_NoTrailerDetectionSupport" ;
VAL_ 2566899211 Trailer2TowedVehStat_CANAvail 3 "CANAvail_NotAvailable" 2 "CANAvail_Error" 1 "CANAvail_CANInterfaceAvailable" 0 "CANAvail_NoCANInterfaceAvailable" ;
VAL_ 2566899211 Trailer1TowedVehStat_CANAvail 3 "CANAvail_NotAvailable" 2 "CANAvail_Error" 1 "CANAvail_CANInterfaceAvailable" 0 "CANAvail_NoCANInterfaceAvailable" ;
VAL_ 2566899211 Trailer3TowedVehStat_DetectSupp 3 "TrailerDetectSupp_NotAvailable" 2 "TrailerDetectSupp_Error" 1 "TrailerDetectSupp_TrailerDetectionSupport" 0 "TrailerDetectSupp_NoTrailerDetectionSupport" ;
VAL_ 2566899211 Trailer3TowedVehStat_CANAvail 3 "CANAvail_NotAvailable" 2 "CANAvail_Error" 1 "CANAvail_CANInterfaceAvailable" 0 "CANAvail_NoCANInterfaceAvailable" ;
VAL_ 2566899211 Trailer1TowedVehStat_DetectStat 3 "TrailerDetectStat_NotAvailable" 2 "TrailerDetectStat_ErrorTrailerDetectionNotPossible" 1 "TrailerDetectStat_NoTowedVehicleDetected" 0 "TrailerDetectStat_TowedVehicleDeteted" ;
VAL_ 2566899211 Trailer5TowedVehStat_DetectSupp 3 "TrailerDetectSupp_NotAvailable" 2 "TrailerDetectSupp_Error" 1 "TrailerDetectSupp_TrailerDetectionSupport" 0 "TrailerDetectSupp_NoTrailerDetectionSupport" ;
VAL_ 2566899211 Trailer4TowedVehStat_DetectStat 3 "TrailerDetectStat_NotAvailable" 2 "TrailerDetectStat_ErrorTrailerDetectionNotPossible" 1 "TrailerDetectStat_NoTowedVehicleDetected" 0 "TrailerDetectStat_TowedVehicleDeteted" ;
VAL_ 2566899211 Trailer4TowedVehStat_BrakeSystem 3 "BrakeSystem_NotAvailable" 2 "BrakeSystem_EBS" 1 "BrakeSystem_ABS" 0 "BrakeSystem_None" ;
VAL_ 2566899211 Trailer5TowedVehStat_DetectStat 3 "TrailerDetectStat_NotAvailable" 2 "TrailerDetectStat_ErrorTrailerDetectionNotPossible" 1 "TrailerDetectStat_NoTowedVehicleDetected" 0 "TrailerDetectStat_TowedVehicleDeteted" ;
VAL_ 2566899211 Trailer3TowedVehStat_BrakeSystem 3 "BrakeSystem_NotAvailable" 2 "BrakeSystem_EBS" 1 "BrakeSystem_ABS" 0 "BrakeSystem_None" ;
VAL_ 2566899211 Trailer1TowedVehStat_BrakeSystem 3 "BrakeSystem_NotAvailable" 2 "BrakeSystem_EBS" 1 "BrakeSystem_ABS" 0 "BrakeSystem_None" ;
VAL_ 2566899211 Trailer5TowedVehStat_CANAvail 3 "CANAvail_NotAvailable" 2 "CANAvail_Error" 1 "CANAvail_CANInterfaceAvailable" 0 "CANAvail_NoCANInterfaceAvailable" ;
VAL_ 2566899211 Trailer2TowedVehStat_DetectStat 3 "TrailerDetectStat_NotAvailable" 2 "TrailerDetectStat_ErrorTrailerDetectionNotPossible" 1 "TrailerDetectStat_NoTowedVehicleDetected" 0 "TrailerDetectStat_TowedVehicleDeteted" ;
VAL_ 2566899211 Trailer2TowedVehStat_BrakeSystem 3 "BrakeSystem_NotAvailable" 2 "BrakeSystem_EBS" 1 "BrakeSystem_ABS" 0 "BrakeSystem_None" ;
VAL_ 2566899211 Trailer2TowedVehStat_DetectSupp 3 "TrailerDetectSupp_NotAvailable" 2 "TrailerDetectSupp_Error" 1 "TrailerDetectSupp_TrailerDetectionSupport" 0 "TrailerDetectSupp_NoTrailerDetectionSupport" ;
VAL_ 2566898955 Trailer5CalibInfo_LoadRange 3 "LoadRange_AxleLoadCalibrationNotSupported" 2 "LoadRange_AxleLoadCalibrationDataForMediumLoad" 1 "LoadRange_AxleLoadCalibrationDataForHeavyLoad" 0 "LoadRange_AxleLoadCalibrationDataForLowLoad" ;
VAL_ 2566898955 Trailer5CalibInfo_CalibUsage 3 "CalibUsage_StoredCalibrationData_NOT_UsedForAxleLoadOutput" 2 "CalibUsage_spare2" 1 "CalibUsage_spare1" 0 "CalibUsage_StoredCalibrationDataUsedForAxleLoadOutput" ;
VAL_ 2566898955 Trailer5CalibInfo_DataStorage 3 "TrailerCalibDataStore_AxleLoadCalibrationNotSupported" 2 "TrailerCalibDataStore_CalibrationAbortedTimeoutOrError" 1 "TrailerCalibDataStore_NewAxleLoadCalibDataStored" 0 "TrailerCalibDataStore_NoAxleLoadCalibrationDataStorageReq" ;
VAL_ 2566898699 Trailer4CalibInfo_LoadRange 3 "LoadRange_AxleLoadCalibrationNotSupported" 2 "LoadRange_AxleLoadCalibrationDataForMediumLoad" 1 "LoadRange_AxleLoadCalibrationDataForHeavyLoad" 0 "LoadRange_AxleLoadCalibrationDataForLowLoad" ;
VAL_ 2566898699 Trailer4CalibInfo_CalibUsage 3 "CalibUsage_StoredCalibrationData_NOT_UsedForAxleLoadOutput" 2 "CalibUsage_spare2" 1 "CalibUsage_spare1" 0 "CalibUsage_StoredCalibrationDataUsedForAxleLoadOutput" ;
VAL_ 2566898699 Trailer4CalibInfo_DataStorage 3 "TrailerCalibDataStore_AxleLoadCalibrationNotSupported" 2 "TrailerCalibDataStore_CalibrationAbortedTimeoutOrError" 1 "TrailerCalibDataStore_NewAxleLoadCalibDataStored" 0 "TrailerCalibDataStore_NoAxleLoadCalibrationDataStorageReq" ;
VAL_ 2566898443 Trailer3CalibInfo_CalibUsage 3 "CalibUsage_StoredCalibrationData_NOT_UsedForAxleLoadOutput" 2 "CalibUsage_spare2" 1 "CalibUsage_spare1" 0 "CalibUsage_StoredCalibrationDataUsedForAxleLoadOutput" ;
VAL_ 2566898443 Trailer3CalibInfo_LoadRange 3 "LoadRange_AxleLoadCalibrationNotSupported" 2 "LoadRange_AxleLoadCalibrationDataForMediumLoad" 1 "LoadRange_AxleLoadCalibrationDataForHeavyLoad" 0 "LoadRange_AxleLoadCalibrationDataForLowLoad" ;
VAL_ 2566898443 Trailer3CalibInfo_DataStorage 3 "TrailerCalibDataStore_AxleLoadCalibrationNotSupported" 2 "TrailerCalibDataStore_CalibrationAbortedTimeoutOrError" 1 "TrailerCalibDataStore_NewAxleLoadCalibDataStored" 0 "TrailerCalibDataStore_NoAxleLoadCalibrationDataStorageReq" ;
VAL_ 2566898187 Trailer2CalibInfo_LoadRange 3 "LoadRange_AxleLoadCalibrationNotSupported" 2 "LoadRange_AxleLoadCalibrationDataForMediumLoad" 1 "LoadRange_AxleLoadCalibrationDataForHeavyLoad" 0 "LoadRange_AxleLoadCalibrationDataForLowLoad" ;
VAL_ 2566898187 Trailer2CalibInfo_DataStorage 3 "TrailerCalibDataStore_AxleLoadCalibrationNotSupported" 2 "TrailerCalibDataStore_CalibrationAbortedTimeoutOrError" 1 "TrailerCalibDataStore_NewAxleLoadCalibDataStored" 0 "TrailerCalibDataStore_NoAxleLoadCalibrationDataStorageReq" ;
VAL_ 2566898187 Trailer2CalibInfo_CalibUsage 3 "CalibUsage_StoredCalibrationData_NOT_UsedForAxleLoadOutput" 2 "CalibUsage_spare2" 1 "CalibUsage_spare1" 0 "CalibUsage_StoredCalibrationDataUsedForAxleLoadOutput" ;
VAL_ 2566897931 Trailer1CalibInfo_LoadRange 3 "LoadRange_AxleLoadCalibrationNotSupported" 2 "LoadRange_AxleLoadCalibrationDataForMediumLoad" 1 "LoadRange_AxleLoadCalibrationDataForHeavyLoad" 0 "LoadRange_AxleLoadCalibrationDataForLowLoad" ;
VAL_ 2566897931 Trailer1CalibInfo_CalibUsage 3 "CalibUsage_StoredCalibrationData_NOT_UsedForAxleLoadOutput" 2 "CalibUsage_spare2" 1 "CalibUsage_spare1" 0 "CalibUsage_StoredCalibrationDataUsedForAxleLoadOutput" ;
VAL_ 2566897931 Trailer1CalibInfo_DataStorage 3 "TrailerCalibDataStore_AxleLoadCalibrationNotSupported" 2 "TrailerCalibDataStore_CalibrationAbortedTimeoutOrError" 1 "TrailerCalibDataStore_NewAxleLoadCalibDataStored" 0 "TrailerCalibDataStore_NoAxleLoadCalibrationDataStorageReq" ;
VAL_ 2566878475 Trailer5NormalLevel_LvlPos 3 "LvlPos_NotAvailable" 2 "LvlPos_Error" 1 "LvlPos_VehicleBodyHeightAtLevel2" 0 "LvlPos_VehicleBodyHeightAtLevel1" ;
VAL_ 2566878475 Trailer5NormalLevel_LvlStatus 3 "LvlStatus_NotAvailable" 2 "LvlStatus_Error" 1 "LvlStatus_VehicelBodyAtRequestedLevel" 0 "LvlStatus_VehicelBodyNotAtRequestedLevel" ;
VAL_ 2566878475 Trailer5RampLevel_LvlStatus 3 "LvlStatus_NotAvailable" 2 "LvlStatus_Error" 1 "LvlStatus_VehicelBodyAtRequestedLevel" 0 "LvlStatus_VehicelBodyNotAtRequestedLevel" ;
VAL_ 2566878475 Trailer5BrkLining_Warning 3 "Warning_NotAvailable" 2 "Warning_Error" 1 "Warning_Warning" 0 "Warning_NoWarning" ;
VAL_ 2566878475 Trailer5RampLevel_LvlPos 3 "LvlPos_NotAvailable" 2 "LvlPos_Error" 1 "LvlPos_VehicleBodyHeightAtLevel2" 0 "LvlPos_VehicleBodyHeightAtLevel1" ;
VAL_ 2566878219 Trailer4RampLevel_LvlStatus 3 "LvlStatus_NotAvailable" 2 "LvlStatus_Error" 1 "LvlStatus_VehicelBodyAtRequestedLevel" 0 "LvlStatus_VehicelBodyNotAtRequestedLevel" ;
VAL_ 2566878219 Trailer4NormalLevel_LvlStatus 3 "LvlStatus_NotAvailable" 2 "LvlStatus_Error" 1 "LvlStatus_VehicelBodyAtRequestedLevel" 0 "LvlStatus_VehicelBodyNotAtRequestedLevel" ;
VAL_ 2566878219 Trailer4BrkLining_Warning 3 "Warning_NotAvailable" 2 "Warning_Error" 1 "Warning_Warning" 0 "Warning_NoWarning" ;
VAL_ 2566878219 Trailer4NormalLevel_LvlPos 3 "LvlPos_NotAvailable" 2 "LvlPos_Error" 1 "LvlPos_VehicleBodyHeightAtLevel2" 0 "LvlPos_VehicleBodyHeightAtLevel1" ;
VAL_ 2566878219 Trailer4RampLevel_LvlPos 3 "LvlPos_NotAvailable" 2 "LvlPos_Error" 1 "LvlPos_VehicleBodyHeightAtLevel2" 0 "LvlPos_VehicleBodyHeightAtLevel1" ;
VAL_ 2566877963 Trailer3RampLevel_LvlStatus 3 "LvlStatus_NotAvailable" 2 "LvlStatus_Error" 1 "LvlStatus_VehicelBodyAtRequestedLevel" 0 "LvlStatus_VehicelBodyNotAtRequestedLevel" ;
VAL_ 2566877963 Trailer3RampLevel_LvlPos 3 "LvlPos_NotAvailable" 2 "LvlPos_Error" 1 "LvlPos_VehicleBodyHeightAtLevel2" 0 "LvlPos_VehicleBodyHeightAtLevel1" ;
VAL_ 2566877963 Trailer3NormalLevel_LvlPos 3 "LvlPos_NotAvailable" 2 "LvlPos_Error" 1 "LvlPos_VehicleBodyHeightAtLevel2" 0 "LvlPos_VehicleBodyHeightAtLevel1" ;
VAL_ 2566877963 Trailer3NormalLevel_LvlStatus 3 "LvlStatus_NotAvailable" 2 "LvlStatus_Error" 1 "LvlStatus_VehicelBodyAtRequestedLevel" 0 "LvlStatus_VehicelBodyNotAtRequestedLevel" ;
VAL_ 2566877963 Trailer3BrkLining_Warning 3 "Warning_NotAvailable" 2 "Warning_Error" 1 "Warning_Warning" 0 "Warning_NoWarning" ;
VAL_ 2566877707 Trailer2BrkLining_Warning 3 "Warning_NotAvailable" 2 "Warning_Error" 1 "Warning_Warning" 0 "Warning_NoWarning" ;
VAL_ 2566877707 Trailer2RampLevel_LvlPos 3 "LvlPos_NotAvailable" 2 "LvlPos_Error" 1 "LvlPos_VehicleBodyHeightAtLevel2" 0 "LvlPos_VehicleBodyHeightAtLevel1" ;
VAL_ 2566877707 Trailer2RampLevel_LvlStatus 3 "LvlStatus_NotAvailable" 2 "LvlStatus_Error" 1 "LvlStatus_VehicelBodyAtRequestedLevel" 0 "LvlStatus_VehicelBodyNotAtRequestedLevel" ;
VAL_ 2566877707 Trailer2NormalLevel_LvlPos 3 "LvlPos_NotAvailable" 2 "LvlPos_Error" 1 "LvlPos_VehicleBodyHeightAtLevel2" 0 "LvlPos_VehicleBodyHeightAtLevel1" ;
VAL_ 2566877707 Trailer2NormalLevel_LvlStatus 3 "LvlStatus_NotAvailable" 2 "LvlStatus_Error" 1 "LvlStatus_VehicelBodyAtRequestedLevel" 0 "LvlStatus_VehicelBodyNotAtRequestedLevel" ;
VAL_ 2566877451 Trailer1NormalLevel_LvlPos 3 "LvlPos_NotAvailable" 2 "LvlPos_Error" 1 "LvlPos_VehicleBodyHeightAtLevel2" 0 "LvlPos_VehicleBodyHeightAtLevel1" ;
VAL_ 2566877451 Trailer1BrkLining_Warning 3 "Warning_NotAvailable" 2 "Warning_Error" 1 "Warning_Warning" 0 "Warning_NoWarning" ;
VAL_ 2566877451 Trailer1RampLevel_LvlPos 3 "LvlPos_NotAvailable" 2 "LvlPos_Error" 1 "LvlPos_VehicleBodyHeightAtLevel2" 0 "LvlPos_VehicleBodyHeightAtLevel1" ;
VAL_ 2566877451 Trailer1NormalLevel_LvlStatus 3 "LvlStatus_NotAvailable" 2 "LvlStatus_Error" 1 "LvlStatus_VehicelBodyAtRequestedLevel" 0 "LvlStatus_VehicelBodyNotAtRequestedLevel" ;
VAL_ 2566877451 Trailer1RampLevel_LvlStatus 3 "LvlStatus_NotAvailable" 2 "LvlStatus_Error" 1 "LvlStatus_VehicelBodyAtRequestedLevel" 0 "LvlStatus_VehicelBodyNotAtRequestedLevel" ;
SIG_GROUP_ 2566897419 Trailer2PneumSupply_sg 1 : Trailer2PneumSupply_Pressure Trailer2PneumSupply_Status;
SIG_GROUP_ 2566897419 Trailer2NomBodyLevel_sg 1 : Trailer2NomBodyLevel_RearLevel Trailer2NomBodyLevel_FrontLevel;
SIG_GROUP_ 2566892811 Trailer1NomBodyLevel_sg 1 : Trailer1NomBodyLevel_RearLevel Trailer1NomBodyLevel_FrontLevel;
SIG_GROUP_ 2566892811 Trailer1PneumSupply_sg 1 : Trailer1PneumSupply_Pressure Trailer1PneumSupply_Status;
SIG_GROUP_ 2566887947 Trailer5TireInfoISO_sg_ISig_1 1 : Trailer5TireInfoISO_Leakage_ISig Trailer5TireInfoISO_PowerSupply_ Trailer5TireInfoISO_TireId_ISig_ Trailer5TireInfoISO_Pressure_ISi Trailer5TireInfoISO_Temperature_ Trailer5TireInfoISO_PresSuff_ISi Trailer5TireInfoISO_Warning_ISig Trailer5TireInfoISO_Active_ISig_;
SIG_GROUP_ 2566883339 Trailer4TireInfoISO_sg_ISig_1 1 : Trailer4TireInfoISO_Temperature_ Trailer4TireInfoISO_TireId_ISig_ Trailer4TireInfoISO_PowerSupply_ Trailer4TireInfoISO_Warning_ISig Trailer4TireInfoISO_Pressure_ISi Trailer4TireInfoISO_Leakage_ISig Trailer4TireInfoISO_Active_ISig_ Trailer4TireInfoISO_PresSuff_ISi;
SIG_GROUP_ 2566878731 Trailer3TireInfoISO_sg_ISig_1 1 : Trailer3TireInfoISO_Pressure_ISi Trailer3TireInfoISO_PowerSupply_ Trailer3TireInfoISO_PresSuff_ISi Trailer3TireInfoISO_Temperature_ Trailer3TireInfoISO_TireId_ISig_ Trailer3TireInfoISO_Leakage_ISig Trailer3TireInfoISO_Active_ISig_ Trailer3TireInfoISO_Warning_ISig;
SIG_GROUP_ 2566874123 Trailer2TireInfoISO_sg_ISig_1 1 : Trailer2TireInfoISO_Warning_ISig Trailer2TireInfoISO_Leakage_ISig Trailer2TireInfoISO_PresSuff_ISi Trailer2TireInfoISO_Pressure_ISi Trailer2TireInfoISO_Temperature_ Trailer2TireInfoISO_PowerSupply_ Trailer2TireInfoISO_TireId_ISig_ Trailer2TireInfoISO_Active_ISig_;
SIG_GROUP_ 2566869259 Trailer1TireInfoISO_sg_ISig_1 1 : Trailer1TireInfoISO_Active_ISig_ Trailer1TireInfoISO_PowerSupply_ Trailer1TireInfoISO_PresSuff_ISi Trailer1TireInfoISO_Warning_ISig Trailer1TireInfoISO_TireId_ISig_ Trailer1TireInfoISO_Pressure_ISi Trailer1TireInfoISO_Leakage_ISig Trailer1TireInfoISO_Temperature_;
SIG_GROUP_ 2566864651 Trailer4BrakeTemp_sg 1 : Trailer4BrakeTemp_Temp Trailer4BrakeTemp_TireId Trailer4BrakeTemp_Status;
SIG_GROUP_ 2566864651 Trailer5BrakeTemp_sg 1 : Trailer5BrakeTemp_TireId Trailer5BrakeTemp_Temp Trailer5BrakeTemp_Status;
SIG_GROUP_ 2566860043 Trailer2BrakeTemp_sg 1 : Trailer2BrakeTemp_Temp Trailer2BrakeTemp_TireId Trailer2BrakeTemp_Status;
SIG_GROUP_ 2566860043 Trailer3BrakeTemp_sg 1 : Trailer3BrakeTemp_Status Trailer3BrakeTemp_Temp Trailer3BrakeTemp_TireId;
SIG_GROUP_ 2566860043 Trailer1BrakeTemp_sg 1 : Trailer1BrakeTemp_Status Trailer1BrakeTemp_TireId Trailer1BrakeTemp_Temp;
SIG_GROUP_ 2566899211 Trailer1TowedVehStat_sg 1 : Trailer1TowedVehStat_DetectSupp Trailer1TowedVehStat_CANAvail Trailer1TowedVehStat_DetectStat Trailer1TowedVehStat_BrakeSystem;
SIG_GROUP_ 2566899211 Trailer3TowedVehStat_sg 1 : Trailer3TowedVehStat_DetectStat Trailer3TowedVehStat_DetectSupp Trailer3TowedVehStat_CANAvail Trailer3TowedVehStat_BrakeSystem;
SIG_GROUP_ 2566899211 Trailer5TowedVehStat_sg 1 : Trailer5TowedVehStat_BrakeSystem Trailer5TowedVehStat_DetectSupp Trailer5TowedVehStat_DetectStat Trailer5TowedVehStat_CANAvail;
SIG_GROUP_ 2566899211 Trailer2TowedVehStat_sg 1 : Trailer2TowedVehStat_CANAvail Trailer2TowedVehStat_DetectStat Trailer2TowedVehStat_BrakeSystem Trailer2TowedVehStat_DetectSupp;
SIG_GROUP_ 2566899211 Trailer4TowedVehStat_sg 1 : Trailer4TowedVehStat_DetectSupp Trailer4TowedVehStat_CANAvail Trailer4TowedVehStat_DetectStat Trailer4TowedVehStat_BrakeSystem;
SIG_GROUP_ 2566898955 Trailer5CalibInfo_sg 1 : Trailer5CalibInfo_LoadRange Trailer5CalibInfo_AxleId Trailer5CalibInfo_Year Trailer5CalibInfo_ScaleLoad Trailer5CalibInfo_CalibUsage Trailer5CalibInfo_DataStorage Trailer5CalibInfo_UncalibLoad Trailer5CalibInfo_Month;
SIG_GROUP_ 2566898699 Trailer4CalibInfo_sg 1 : Trailer4CalibInfo_AxleId Trailer4CalibInfo_LoadRange Trailer4CalibInfo_CalibUsage Trailer4CalibInfo_UncalibLoad Trailer4CalibInfo_DataStorage Trailer4CalibInfo_ScaleLoad Trailer4CalibInfo_Year Trailer4CalibInfo_Month;
SIG_GROUP_ 2566898443 Trailer3CalibInfo_sg 1 : Trailer3CalibInfo_CalibUsage Trailer3CalibInfo_LoadRange Trailer3CalibInfo_Month Trailer3CalibInfo_ScaleLoad Trailer3CalibInfo_UncalibLoad Trailer3CalibInfo_AxleId Trailer3CalibInfo_Year Trailer3CalibInfo_DataStorage;
SIG_GROUP_ 2566898187 Trailer2CalibInfo_sg 1 : Trailer2CalibInfo_LoadRange Trailer2CalibInfo_DataStorage Trailer2CalibInfo_Year Trailer2CalibInfo_AxleId Trailer2CalibInfo_CalibUsage Trailer2CalibInfo_Month Trailer2CalibInfo_ScaleLoad Trailer2CalibInfo_UncalibLoad;
SIG_GROUP_ 2566897931 Trailer1CalibInfo_sg 1 : Trailer1CalibInfo_Year Trailer1CalibInfo_LoadRange Trailer1CalibInfo_AxleId Trailer1CalibInfo_CalibUsage Trailer1CalibInfo_UncalibLoad Trailer1CalibInfo_Month Trailer1CalibInfo_DataStorage Trailer1CalibInfo_ScaleLoad;
SIG_GROUP_ 2566878475 Trailer5RampLevel_sg 1 : Trailer5RampLevel_LvlStatus Trailer5RampLevel_LvlPos;
SIG_GROUP_ 2566878475 Trailer5BrkLining_sg 1 : Trailer5BrkLining_Wear Trailer5BrkLining_BrkLnTireId Trailer5BrkLining_Warning;
SIG_GROUP_ 2566878475 Trailer5NormalLevel_sg 1 : Trailer5NormalLevel_LvlPos Trailer5NormalLevel_LvlStatus;
SIG_GROUP_ 2566878475 Trailer5RelBodyLevel_sg 1 : Trailer5RelBodyLevel_RearLevel Trailer5RelBodyLevel_FrontLevel;
SIG_GROUP_ 2566878219 Trailer4RelBodyLevel_sg 1 : Trailer4RelBodyLevel_FrontLevel Trailer4RelBodyLevel_RearLevel;
SIG_GROUP_ 2566878219 Trailer4RampLevel_sg 1 : Trailer4RampLevel_LvlStatus Trailer4RampLevel_LvlPos;
SIG_GROUP_ 2566878219 Trailer4BrkLining_sg 1 : Trailer4BrkLining_BrkLnTireId Trailer4BrkLining_Wear Trailer4BrkLining_Warning;
SIG_GROUP_ 2566878219 Trailer4NormalLevel_sg 1 : Trailer4NormalLevel_LvlStatus Trailer4NormalLevel_LvlPos;
SIG_GROUP_ 2566877963 Trailer3RelBodyLevel_sg 1 : Trailer3RelBodyLevel_RearLevel Trailer3RelBodyLevel_FrontLevel;
SIG_GROUP_ 2566877963 Trailer3NormalLevel_sg 1 : Trailer3NormalLevel_LvlPos Trailer3NormalLevel_LvlStatus;
SIG_GROUP_ 2566877963 Trailer3BrkLining_sg 1 : Trailer3BrkLining_BrkLnTireId Trailer3BrkLining_Wear Trailer3BrkLining_Warning;
SIG_GROUP_ 2566877963 Trailer3RampLevel_sg 1 : Trailer3RampLevel_LvlStatus Trailer3RampLevel_LvlPos;
SIG_GROUP_ 2566877707 Trailer2BrkLining_sg 1 : Trailer2BrkLining_Warning Trailer2BrkLining_Wear Trailer2BrkLining_BrkLnTireId;
SIG_GROUP_ 2566877707 Trailer2RampLevel_sg 1 : Trailer2RampLevel_LvlPos Trailer2RampLevel_LvlStatus;
SIG_GROUP_ 2566877707 Trailer2RelBodyLevel_sg 1 : Trailer2RelBodyLevel_RearLevel Trailer2RelBodyLevel_FrontLevel;
SIG_GROUP_ 2566877707 Trailer2NormalLevel_sg 1 : Trailer2NormalLevel_LvlPos Trailer2NormalLevel_LvlStatus;
SIG_GROUP_ 2566877451 Trailer1RampLevel_sg 1 : Trailer1RampLevel_LvlPos Trailer1RampLevel_LvlStatus;
SIG_GROUP_ 2566877451 Trailer1NormalLevel_sg 1 : Trailer1NormalLevel_LvlPos Trailer1NormalLevel_LvlStatus;
SIG_GROUP_ 2566877451 Trailer1RelBodyLevel_sg 1 : Trailer1RelBodyLevel_FrontLevel Trailer1RelBodyLevel_RearLevel;
SIG_GROUP_ 2566877451 Trailer1BrkLining_sg 1 : Trailer1BrkLining_BrkLnTireId Trailer1BrkLining_Wear Trailer1BrkLining_Warning;
